VERSION "HNNBNNNYNNNNNNNNNNNNNNNNNNNNNNNNNNNNNNNNNN/4/%%%/4/'%**4NNN///"

NS_ :

BS_:

BU_: Airbag Allrad_Haldex BAP_Tester DCC_Gen3 EBKV_MQBW ESC_MQBW Gateway_Max Lenkhilfe_REPS

BO_ 958 Motor_14: 8 Gateway_Max
 SG_ Motor_14_CRC : 0|8@1+ (1,0) [0|255] ""  ESC_MQBW
 SG_ Motor_14_BZ : 8|4@1+ (1,0) [0|15] ""  ESC_MQBW
 SG_ MO_StartStopp_Status : 12|2@1+ (1.0,0.0) [0.0|3] ""  ESC_MQBW,Lenkhilfe_REPS
 SG_ MO_StartStopp_Wiederstart : 14|1@1+ (1.0,0.0) [0.0|1] ""  EBKV_MQBW,ESC_MQBW,Lenkhilfe_REPS
 SG_ MO_StartStopp_Motorstopp : 15|1@1+ (1.0,0.0) [0.0|1] ""  ESC_MQBW,Lenkhilfe_REPS
 SG_ MO_Freig_Reku : 16|2@1+ (1.0,0.0) [0.0|3] ""  Vector__XXX
 SG_ MO_Kl_75 : 18|1@1+ (1.0,0.0) [0.0|1] ""  EBKV_MQBW,ESC_MQBW,Lenkhilfe_REPS
 SG_ MO_Kl_50 : 19|1@1+ (1.0,0.0) [0.0|1] ""  EBKV_MQBW,ESC_MQBW
 SG_ MO_Gangposition : 20|4@1+ (1.0,0.0) [0.0|15] ""  Airbag,Allrad_Haldex,EBKV_MQBW
 SG_ MO_StartStopp_Fahrerwunsch : 24|2@1+ (1.0,0.0) [0.0|3] ""  ESC_MQBW,Lenkhilfe_REPS
 SG_ MO_HYB_Fahrbereitschaft : 26|1@1+ (1.0,0.0) [0.0|1] ""  EBKV_MQBW,ESC_MQBW,Lenkhilfe_REPS
 SG_ MO_Ext_E_Fahrt_aktiv : 27|1@1+ (1.0,0.0) [0.0|1] ""  Vector__XXX
 SG_ MO_Fahrer_bremst : 28|1@1+ (1.0,0.0) [0.0|1] ""  Airbag,Allrad_Haldex,ESC_MQBW
 SG_ MO_QBit_Fahrer_bremst : 29|1@1+ (1.0,0.0) [0.0|1] ""  Airbag,Allrad_Haldex,ESC_MQBW
 SG_ MO_BLS : 30|1@1+ (1.0,0.0) [0.0|1] ""  Airbag,ESC_MQBW,Lenkhilfe_REPS
 SG_ MO_Konsistenz_Bremsped : 31|1@1+ (1.0,0.0) [0.0|1] ""  Vector__XXX
 SG_ MO_Timeout_ESP : 32|1@1+ (1.0,0.0) [0.0|1] ""  ESC_MQBW
 SG_ MO_Klima_Eingr : 33|2@1+ (1.0,0.0) [0.0|3] ""  Vector__XXX
 SG_ MO_Aussp_Anlass : 35|1@1+ (1.0,0.0) [0.0|1] ""  Vector__XXX
 SG_ MO_Freig_Anlass : 36|1@1+ (1.0,0.0) [0.0|1] ""  Lenkhilfe_REPS
 SG_ MO_Kuppl_schalter : 37|1@1+ (1.0,0.0) [0.0|1] ""  Allrad_Haldex,ESC_MQBW
 SG_ MO_Interlock : 38|1@1+ (1.0,0.0) [0.0|1] ""  Vector__XXX
 SG_ MO_Motor_laeuft : 39|1@1+ (1.0,0.0) [0.0|1] ""  ESC_MQBW
 SG_ MO_Kickdown : 40|1@1+ (1.0,0.0) [0.0|1] ""  ESC_MQBW,Lenkhilfe_REPS
 SG_ MO_QBit_KL_75 : 41|1@1+ (1.0,0.0) [0.0|1] ""  EBKV_MQBW,ESC_MQBW,Lenkhilfe_REPS
 SG_ MO_EKlKomLeiRed : 42|2@1+ (1.0,0.0) [0.0|3] ""  Vector__XXX
 SG_ MO_Handshake_STH : 44|1@1+ (1.0,0.0) [0.0|1] ""  Vector__XXX
 SG_ MO_BKV_Unterdruckwarnung : 45|1@1+ (1.0,0.0) [0.0|1] ""  Vector__XXX
 SG_ MO_Freigabe_Segeln : 46|1@1+ (1.0,0.0) [0.0|1] ""  Vector__XXX
 SG_ MO_PTC_Status : 47|3@1+ (1.0,0.0) [0.0|7] ""  Vector__XXX
 SG_ MO_QBit_Gangposition : 50|1@1+ (1.0,0.0) [0.0|1] ""  Airbag
 SG_ MO_Signalquelle_Gangposition : 51|1@1+ (1.0,0.0) [0.0|1] ""  Vector__XXX
 SG_ MO_Remotestart_Betrieb : 52|1@1+ (1.0,0.0) [0.0|1] ""  Vector__XXX
 SG_ MO_Remotestart_moeglich : 53|1@1+ (1.0,0.0) [0.0|1] ""  Vector__XXX
 SG_ MO_FMAus_aktiv : 55|1@1+ (1.0,0.0) [0.0|1] ""  ESC_MQBW
 SG_ MO_FMAus_Startvariante : 56|2@1+ (1.0,0.0) [0.0|3] ""  Vector__XXX
 SG_ MO_BMS_NV_Anf_stuetzen : 58|1@1+ (1.0,0.0) [0.0|1] ""  Vector__XXX
 SG_ MO_Zylinderabschaltung : 59|2@1+ (1.0,0.0) [0.0|3] ""  ESC_MQBW
 SG_ MO_HYB_VM_aktiv : 61|1@1+ (1.0,0.0) [0.0|1] ""  Vector__XXX
 SG_ MO_StartVorauss_erfuellt : 62|2@1+ (1.0,0.0) [0.0|3] ""  Vector__XXX

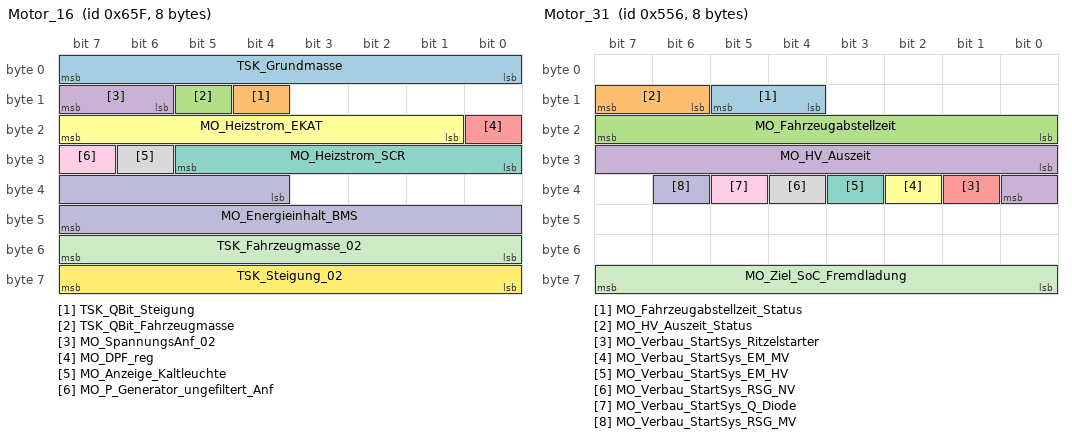
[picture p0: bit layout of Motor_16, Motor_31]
BO_ 1631 Motor_16: 8 Gateway_Max
 SG_ TSK_Grundmasse : 0|8@1+ (32,0) [0|8128] "Unit_KiloGram"  Vector__XXX
 SG_ TSK_QBit_Steigung : 12|1@1+ (1.0,0.0) [0.0|1] ""  Vector__XXX
 SG_ TSK_QBit_Fahrzeugmasse : 13|1@1+ (1.0,0.0) [0.0|1] ""  ESC_MQBW
 SG_ MO_SpannungsAnf_02 : 14|2@1+ (1.0,0.0) [0.0|3] ""  Vector__XXX
 SG_ MO_DPF_reg : 16|1@1+ (1.0,0.0) [0.0|1] ""  Vector__XXX
 SG_ MO_Heizstrom_EKAT : 17|7@1+ (1,0) [0|126] "Unit_Amper"  Vector__XXX
 SG_ MO_Heizstrom_SCR : 24|6@1+ (1,0) [0|62] "Unit_Amper"  Vector__XXX
 SG_ MO_Anzeige_Kaltleuchte : 30|1@1+ (1.0,0.0) [0.0|1] ""  Vector__XXX
 SG_ MO_P_Generator_ungefiltert_Anf : 31|1@1+ (1.0,0.0) [0.0|1] ""  Vector__XXX
 SG_ MO_Energieinhalt_BMS : 36|12@1+ (25,0) [0|102325] "Unit_WattHour"  Vector__XXX
 SG_ TSK_Fahrzeugmasse_02 : 48|8@1+ (32,0) [0|8128] "Unit_KiloGram"  ESC_MQBW
 SG_ TSK_Steigung_02 : 56|8@1+ (0.8,-101.6) [-100.8|101.6] "Unit_PerCent"  Vector__XXX

BO_ 1648 Motor_18: 8 Gateway_Max
 SG_ MO_max_Ladedruck : 0|6@1+ (0.1,0) [0.0|6.3] "Unit_Bar"  Vector__XXX
 SG_ MO_ANC_Kennfeld_Anf : 6|2@1+ (1.0,0.0) [0.0|3] ""  Vector__XXX
 SG_ MO_Bremslicht_Reku : 8|1@1+ (1.0,0.0) [0.0|1] ""  ESC_MQBW
 SG_ MO_StartStopp_PopUp : 9|2@1+ (1.0,0.0) [0.0|3] ""  Vector__XXX
 SG_ MO1_Sperr_Info_WFS : 11|1@1+ (1.0,0.0) [0.0|1] ""  Vector__XXX
 SG_ MO1_Freigabe_Info_WFS : 12|1@1+ (1.0,0.0) [0.0|1] ""  Vector__XXX
 SG_ MO_EPCL : 13|3@1+ (1.0,0.0) [0.0|7] ""  Vector__XXX
 SG_ MO_Zylabsch_Texte_02 : 16|4@1+ (1.0,0.0) [0.0|15] ""  Vector__XXX
 SG_ MO_Fahrzeugtyp : 20|3@1+ (1.0,0.0) [0.0|7] ""  EBKV_MQBW,ESC_MQBW
 SG_ MO_NMAX_Schaltanzeige : 23|9@1+ (25,0) [0|12775] "Unit_MinutInver"  Vector__XXX
 SG_ MO_Abstellzeit : 32|8@1+ (8,0) [0|2024] "Unit_Minut"  Vector__XXX
 SG_ MO_Abstellzeit_Status : 40|2@1+ (1.0,0.0) [0.0|3] ""  Vector__XXX
 SG_ MO1_Freigabe_Verfallsinfo_WFS : 42|1@1+ (1.0,0.0) [0.0|1] ""  Vector__XXX
 SG_ MO_Hybrid_StartStopp_LED : 43|2@1+ (1.0,0.0) [0.0|3] ""  Vector__XXX
 SG_ MO_Fehler_Zylabsch : 45|2@1+ (1.0,0.0) [0.0|3] ""  Vector__XXX
 SG_ MO_Anzahl_Abgesch_Zyl : 47|3@1+ (1.0,0.0) [0.0|7] ""  ESC_MQBW
 SG_ MO_Zylabsch_Texte : 50|2@1+ (1.0,0.0) [0.0|3] ""  Vector__XXX
 SG_ MO_Ethanol_BS_Texte : 52|3@1+ (1.0,0.0) [0.0|7] ""  Vector__XXX
 SG_ MO_Drehzahl_Warnung : 55|1@1+ (1.0,0.0) [0.0|1] ""  Vector__XXX
 SG_ MO_obere_Drehzahlgrenze : 56|8@1+ (50,0) [50|12750] "Unit_MinutInver"  Vector__XXX

BO_ 1366 Motor_31: 8 Gateway_Max
 SG_ MO_Fahrzeugabstellzeit_Status : 12|2@1+ (1.0,0.0) [0.0|3] ""  EBKV_MQBW
 SG_ MO_HV_Auszeit_Status : 14|2@1+ (1.0,0.0) [0.0|3] ""  Vector__XXX
 SG_ MO_Fahrzeugabstellzeit : 16|8@1+ (8,0) [0|2024] "Unit_Minut"  EBKV_MQBW
 SG_ MO_HV_Auszeit : 24|9@1+ (4,0) [0|2036] "Unit_Minut"  Vector__XXX
 SG_ MO_Verbau_StartSys_Ritzelstarter : 33|1@1+ (1.0,0.0) [0.0|1] ""  Vector__XXX
 SG_ MO_Verbau_StartSys_EM_MV : 34|1@1+ (1.0,0.0) [0.0|1] ""  Vector__XXX
 SG_ MO_Verbau_StartSys_EM_HV : 35|1@1+ (1.0,0.0) [0.0|1] ""  Vector__XXX
 SG_ MO_Verbau_StartSys_RSG_NV : 36|1@1+ (1.0,0.0) [0.0|1] ""  Vector__XXX
 SG_ MO_Verbau_StartSys_Q_Diode : 37|1@1+ (1.0,0.0) [0.0|1] ""  Vector__XXX
 SG_ MO_Verbau_StartSys_RSG_MV : 38|1@1+ (1.0,0.0) [0.0|1] ""  Vector__XXX
 SG_ MO_Ziel_SoC_Fremdladung : 56|8@1+ (0.4,0) [0.0|100.0] "Unit_PerCent"  Vector__XXX

BO_ 269 Motor_50: 48 Gateway_Max
 SG_ Motor_50_CRC : 0|8@1+ (1,0) [0|255] ""  ESC_MQBW
 SG_ Motor_50_BZ : 8|4@1+ (1,0) [0|15] ""  ESC_MQBW
 SG_ MO_Mom_Soll_Roh : 12|10@1+ (1,-509) [-509|509] ""  Allrad_Haldex,DCC_Gen3,ESC_MQBW,Lenkhilfe_REPS
 SG_ MO_Mom_Ist_Summe : 22|10@1+ (1,-509) [-509|509] ""  Allrad_Haldex,ESC_MQBW,Lenkhilfe_REPS
 SG_ MO_Mom_Traegheit_Summe : 32|10@1+ (1,-509) [-509|509] ""  ESC_MQBW,Lenkhilfe_REPS
 SG_ MO_Mom_Soll_gefiltert : 42|10@1+ (1,-509) [-509|509] ""  Allrad_Haldex
 SG_ MO_Mom_Schub : 52|9@1+ (1,-509) [-509|0] ""  Allrad_Haldex,ESC_MQBW,Lenkhilfe_REPS
 SG_ MO_Status_Normalbetrieb_01 : 61|1@1+ (1.0,0.0) [0.0|1] ""  Allrad_Haldex
 SG_ MO_erste_Ungenauschwelle : 62|1@1+ (1.0,0.0) [0.0|1] ""  Vector__XXX
 SG_ MO_QBit_Motormomente : 63|1@1+ (1.0,0.0) [0.0|1] ""  ESC_MQBW,Lenkhilfe_REPS
 SG_ MO_Mom_neg_verfuegbar : 76|9@1+ (1,-509) [-509|0] ""  Vector__XXX
 SG_ MO_Mom_Begr_Fahr : 85|9@1+ (1,0) [0|509] ""  Vector__XXX
 SG_ MO_Mom_Begr_Schalt : 94|10@1+ (1,-509) [-509|509] ""  Vector__XXX
 SG_ MO_Momentenintegral_02 : 104|7@1+ (1,0) [0|100] "Unit_PerCent"  Vector__XXX
 SG_ MO_QBit_Drehzahl_01 : 111|1@1+ (1.0,0.0) [0.0|1] ""  Airbag,ESC_MQBW,Lenkhilfe_REPS
 SG_ MO_Drehzahl_01 : 112|16@1+ (0.25,0) [0.00|16383.00] "Unit_MinutInver"  Airbag,Allrad_Haldex,ESC_MQBW,Lenkhilfe_REPS
 SG_ MO_HYB_EMode_Info : 142|2@1+ (1.0,0.0) [0.0|3] ""  Vector__XXX
 SG_ MO_HYB_max_ind_VM_Mom_02 : 144|8@1+ (1.186,0) [0.000|300.058] "Unit_NewtoMeter"  Vector__XXX
 SG_ MO_HYB_Zielzustand : 152|3@1+ (1.0,0.0) [0.0|7] ""  ESC_MQBW
 SG_ MO_HYB_Modus_Ankopplung_VM : 155|1@1+ (1.0,0.0) [0.0|1] ""  Vector__XXX
 SG_ MO_HYB_Freigabe_VM_Eingr : 156|2@1+ (1.0,0.0) [0.0|3] ""  Vector__XXX
 SG_ MO_HYB_Sollstatus_K0 : 158|1@1+ (1.0,0.0) [0.0|1] ""  Vector__XXX
 SG_ MO_HYB_Komfortstufe : 159|1@1+ (1.0,0.0) [0.0|1] ""  Vector__XXX
 SG_ MO_HYB_VM_bereit : 160|1@1+ (1.0,0.0) [0.0|1] ""  Vector__XXX
 SG_ MO_HYB_Stoppmodus : 161|1@1+ (1.0,0.0) [0.0|1] ""  Vector__XXX
 SG_ MO_HYB_LowSpeedModus : 162|1@1+ (1.0,0.0) [0.0|1] ""  Vector__XXX
 SG_ MO_HYB_Schaltverhinderung : 163|1@1+ (1.0,0.0) [0.0|1] ""  Vector__XXX
 SG_ MO_HYB_E_Faktor : 164|4@1+ (1.0,0.0) [0.0|15] ""  Vector__XXX
 SG_ MO_HYB_VM_Mom_oE_02 : 168|8@1+ (1.186,-50) [-50.000|250.058] "Unit_NewtoMeter"  Vector__XXX
 SG_ MO_Drehzahl_VM : 176|16@1+ (0.25,0) [0.00|16383.00] "Unit_MinutInver"  EBKV_MQBW,ESC_MQBW
 SG_ MO_EM1_SollDrehzahl : 192|15@1+ (1,-10000) [-10000|22766] "Unit_MinutInver"  Vector__XXX
 SG_ MO_Luftpfad_Verzugszeit_praed : 207|5@1+ (10,0) [10|310] "Unit_MilliSecon"  Vector__XXX
 SG_ MO_EM2_SollDrehzahl : 212|15@1+ (1,-10000) [-10000|22766] "Unit_MinutInver"  Vector__XXX
 SG_ MO_TNW_Min_Strom_Lim : 227|13@1+ (0.5,-2047) [-2047.0|2047.5] "Unit_Amper"  Vector__XXX
 SG_ MO_TNW_Max_Strom_Lim : 240|13@1+ (0.5,-2047) [-2047.0|2047.5] "Unit_Amper"  Vector__XXX

BO_ 267 Motor_51_Auth: 48 Gateway_Max
 SG_ Motor_51_CRC : 0|8@1+ (1,0) [0|255] ""  ESC_MQBW
 SG_ Motor_51_BZ : 8|4@1+ (1,0) [0|15] ""  ESC_MQBW
 SG_ MO_Fahrpedalrohwert_01 : 12|8@1+ (0.4,0) [0.0|101.6] "Unit_PerCent"  Airbag,Allrad_Haldex,DCC_Gen3,EBKV_MQBW,ESC_MQBW,Lenkhilfe_REPS
 SG_ MO_QBit_Fahrpedalwerte_01 : 20|1@1+ (1.0,0.0) [0.0|1] ""  Airbag,Allrad_Haldex,EBKV_MQBW,ESC_MQBW,Lenkhilfe_REPS
 SG_ MO_Fahrpedalgradient : 21|8@1+ (25,0) [0|6350] "Unit_PerCentPerSecon"  ESC_MQBW
 SG_ MO_Sig_Fahrpedalgradient : 29|1@1+ (1.0,0.0) [0.0|1] ""  ESC_MQBW
 SG_ MO_rel_Saugrohrdruck : 30|6@1+ (18,0) [0|1116] "Unit_MilliBar"  Vector__XXX
 SG_ MO_rel_Saugrohrdruck_gem_err : 36|1@1+ (1.0,0.0) [0.0|1] ""  Vector__XXX
 SG_ MO_Moment_im_Leerlauf : 37|1@1+ (1.0,0.0) [0.0|1] ""  ESC_MQBW
 SG_ MO_Schubabschaltung : 38|1@1+ (1.0,0.0) [0.0|1] ""  Vector__XXX
 SG_ MO_StartStopp_StoppVorbereitung : 39|1@1+ (1.0,0.0) [0.0|1] ""  Vector__XXX
 SG_ MO_Solldrehz_Leerlauf : 40|8@1+ (10,0) [0|2540] "Unit_MinutInver"  ESC_MQBW
 SG_ MO_Entkopplung_Sollschlupf : 48|7@1+ (20,0) [0|2480] "Unit_MinutInver"  Vector__XXX
 SG_ MO_temporaere_Fahrerabwesenheit : 55|1@1+ (1.0,0.0) [0.0|1] ""  ESC_MQBW
 SG_ TSK_a_Soll_gradientenbegrenzt : 57|7@1+ (0.1,-7.2) [-7.2|5.4] "Unit_MeterPerSeconSquar"  Vector__XXX
 SG_ TSK_Radbremsmom : 76|12@1+ (8,0) [0|32760] "Unit_NewtoMeter"  ESC_MQBW
 SG_ TSK_Status : 88|3@1+ (1.0,0.0) [0.0|7] ""  Airbag,ESC_MQBW
 SG_ TSK_v_Begrenzung_aktiv : 91|1@1+ (1.0,0.0) [0.0|1] ""  Vector__XXX
 SG_ TSK_Standby_Anf_ESP : 92|1@1+ (1.0,0.0) [0.0|1] ""  ESC_MQBW
 SG_ TSK_Freig_Verzoeg_Anf : 94|1@1+ (1.0,0.0) [0.0|1] ""  ESC_MQBW
 SG_ TSK_Limiter_ausgewaehlt : 95|1@1+ (1.0,0.0) [0.0|1] ""  Vector__XXX
 SG_ TSK_Hauptschalter_GRA_ACC : 106|2@1+ (1.0,0.0) [0.0|3] ""  Vector__XXX
 SG_ TSK_SRBM_Anf_ASIL : 108|3@1+ (1.0,0.0) [0.0|7] ""  ESC_MQBW
 SG_ TSK_ax_Getriebe_02 : 112|9@1+ (0.024,-2.016) [-2.016|10.224] "Unit_MeterPerSeconSquar"  Vector__XXX
 SG_ TSK_Zwangszusch_ESP : 121|1@1+ (1.0,0.0) [0.0|1] ""  ESC_MQBW
 SG_ TSK_zul_Regelabw : 122|6@1+ (0.024,0) [0.000|1.512] "Unit_MeterPerSeconSquar"  Vector__XXX
 SG_ TSK_Radsollmoment : 128|16@1+ (0.5,-16383) [-16383.0|16383.5] "Unit_NewtoMeter"  Vector__XXX
 SG_ TSK_Kategorie_Verzoegerungsfkt : 144|2@1+ (1.0,0.0) [0.0|3] ""  ESC_MQBW
 SG_ TSK_Notstopp_Anf : 233|2@1+ (1.0,0.0) [0.0|3] ""  ESC_MQBW
 SG_ MO_Status_MinDrzEingriff : 235|3@1+ (1.0,0.0) [0.0|7] ""  Vector__XXX
 SG_ MO_Status_MaxDrzEingriff : 238|3@1+ (1.0,0.0) [0.0|7] ""  Vector__XXX
 SG_ MO_Status_MinDrzEingriff_sek : 241|3@1+ (1.0,0.0) [0.0|7] ""  Vector__XXX
 SG_ MO_Status_MaxDrzEingriff_sek : 244|3@1+ (1.0,0.0) [0.0|7] ""  Vector__XXX
 SG_ TSK_SRBM_max_Gradient : 248|7@1+ (50,0) [0|6250] "Unit_NewtoMeterPerSecon"  ESC_MQBW
 SG_ SOK_Motor_51_Signatur : 352|32@1+ (1,0) [0|4294967295] ""  Vector__XXX

BO_ 512 Motor_53: 32 Gateway_Max
 SG_ TSK_Wunschgeschw : 12|10@1+ (0.32,0) [0.00|326.72] "Unit_KiloMeterPerHour"  Vector__XXX
 SG_ TSK_praediktiver_Hinweis : 22|3@1+ (1.0,0.0) [0.0|7] ""  Vector__XXX
 SG_ TSK_naechstes_Event : 25|6@1+ (1.0,0.0) [0.0|63] ""  Vector__XXX
 SG_ TSK_Fahrzeugstatus_praed_Fkt : 31|3@1+ (1.0,0.0) [0.0|7] ""  Vector__XXX
 SG_ TSK_praediktiver_Automode : 34|1@1+ (1.0,0.0) [0.0|1] ""  Vector__XXX
 SG_ CE_StStrtDlyEmiSysPrep : 35|2@1+ (1.0,0.0) [0.0|3] ""  Vector__XXX
 SG_ CE_StLdRdcEmiSysPrep : 37|3@1+ (1.0,0.0) [0.0|7] ""  Vector__XXX
 SG_ TSK_Texte : 40|5@1+ (1.0,0.0) [0.0|31] ""  Vector__XXX
 SG_ TSK_Akustik : 45|3@1+ (1.0,0.0) [0.0|7] ""  Vector__XXX
 SG_ TSK_Texte_Primaeranz : 48|5@1+ (1.0,0.0) [0.0|31] ""  Vector__XXX
 SG_ TSK_Limiter_Fahrerinfo : 53|2@1+ (1.0,0.0) [0.0|3] ""  Vector__XXX
 SG_ TSK_Limiter_Anzeige : 55|1@1+ (1.0,0.0) [0.0|1] ""  Vector__XXX
 SG_ TSK_Fahrzeugstatus_GRA : 56|1@1+ (1.0,0.0) [0.0|1] ""  Vector__XXX
 SG_ TSK_Fahrzeugstatus_Limiter : 57|1@1+ (1.0,0.0) [0.0|1] ""  Vector__XXX
 SG_ MO_Motorlaufwarnung : 58|1@1+ (1.0,0.0) [0.0|1] ""  Vector__XXX
 SG_ TSK_naechstes_Event_Einheit : 60|1@1+ (1.0,0.0) [0.0|1] ""  Vector__XXX
 SG_ TSK_Status_Anzeige : 61|3@1+ (1.0,0.0) [0.0|7] ""  Vector__XXX
 SG_ MO_Sperrung_FahrPr_BZS : 64|8@1+ (1.0,0.0) [0.0|255] ""  Vector__XXX
 SG_ MO_Rampenzeit_Generator_Anf : 72|4@1+ (1.0,0.0) [0.0|15] ""  Vector__XXX
 SG_ MO_Prio_MAX_Wunschdrehzahl : 76|1@1+ (1.0,0.0) [0.0|1] ""  Vector__XXX
 SG_ MO_Prio_MIN_Wunschdrehzahl : 77|1@1+ (1.0,0.0) [0.0|1] ""  Vector__XXX
 SG_ MO_Luftpfad_aktiv : 78|1@1+ (1.0,0.0) [0.0|1] ""  Vector__XXX
 SG_ MO_v_Begrenz_Aktivierbar : 79|1@1+ (1.0,0.0) [0.0|1] ""  Vector__XXX
 SG_ MO_Drehzahlbeeinflussung : 80|8@1+ (0.39,0) [0.00|99.45] "Unit_PerCent"  Vector__XXX
 SG_ MO_MIN_Wunschdrehzahl : 88|8@1+ (25,0) [0|6350] "Unit_MinutInver"  Vector__XXX
 SG_ MO_MAX_Wunschdrehzahl : 96|9@1+ (25,0) [0|12750] "Unit_MinutInver"  Vector__XXX
 SG_ MO_Charisma_FahrPr : 105|4@1+ (1.0,0.0) [0.0|15] ""  Vector__XXX
 SG_ MO_Charisma_Status : 109|2@1+ (1.0,0.0) [0.0|3] ""  Vector__XXX
 SG_ MO_StSt_Charisma_FahrPr : 111|4@1+ (1.0,0.0) [0.0|15] ""  Vector__XXX
 SG_ MO_StSt_Charisma_Status : 115|2@1+ (1.0,0.0) [0.0|3] ""  Vector__XXX
 SG_ MO_BZS_Charisma_FahrPr : 117|4@1+ (1.0,0.0) [0.0|15] ""  Vector__XXX
 SG_ MO_BZS_Charisma_Status : 121|2@1+ (1.0,0.0) [0.0|3] ""  Vector__XXX
 SG_ MO_NGS_Position : 123|1@1+ (1.0,0.0) [0.0|1] ""  ESC_MQBW
 SG_ MO_NGS_Status : 124|2@1+ (1.0,0.0) [0.0|3] ""  ESC_MQBW
 SG_ MO_v_Begrenzung_Niveau : 126|2@1+ (1.0,0.0) [0.0|3] ""  Vector__XXX
 SG_ MO_Anzeige_Rekuperation : 128|8@1+ (0.5,-0.5) [0.0|100.0] "Unit_PerCent"  Vector__XXX
 SG_ PEA_Fortschrittsanzeige : 136|7@1+ (1,0) [0|100] "Unit_PerCent"  Vector__XXX
 SG_ MO_Anzeige_Fahrbereitschaft : 143|1@1+ (1.0,0.0) [0.0|1] ""  Vector__XXX
 SG_ MO_Boost_verfuegbar : 144|8@1+ (0.4,-0.4) [0.0|100.4] "Unit_PerCent"  Vector__XXX
 SG_ MO_Overboost : 152|1@1+ (1.0,0.0) [0.0|1] ""  Vector__XXX
 SG_ MO_Boost_aktiv : 153|1@1+ (1.0,0.0) [0.0|1] ""  Vector__XXX
 SG_ MO_Anzeige_Betriebsmodus : 154|4@1+ (1.0,0.0) [0.0|15] ""  Vector__XXX
 SG_ PEA_Hinweis : 158|2@1+ (1.0,0.0) [0.0|3] ""  Vector__XXX
 SG_ PEA_Ereignisanzeige : 160|5@1+ (1.0,0.0) [0.0|31] ""  Vector__XXX
 SG_ PEA_Ereignisanzeige_temporaer : 165|1@1+ (1.0,0.0) [0.0|1] ""  Vector__XXX
 SG_ PEA_Abschalttexte : 166|2@1+ (1.0,0.0) [0.0|3] ""  Vector__XXX
 SG_ PEA_Zielgeschw_Einheit : 168|1@1+ (1.0,0.0) [0.0|1] ""  Vector__XXX
 SG_ PEA_Zielgeschw : 169|5@1+ (1.0,0.0) [0.0|31] ""  Vector__XXX
 SG_ MO_Antriebsstrang_Warnung_HS : 174|2@1+ (1.0,0.0) [0.0|3] ""  Vector__XXX
 SG_ MO_Anzeige_Verbrauch_oE : 176|16@1+ (0.005,0) [0.000|327.675] "Unit_None"  Vector__XXX
 SG_ MO_Text_Aktivierung_Antrieb : 192|4@1+ (1.0,0.0) [0.0|15] ""  Vector__XXX
 SG_ ISA_Tempolimit_Regelung : 196|6@1+ (1.0,0.0) [0.0|63] ""  Vector__XXX
 SG_ PEA_Fahrerinfo : 202|4@1+ (1.0,0.0) [0.0|15] ""  Vector__XXX
 SG_ CE_CtrPrpPrep : 206|3@1+ (1.0,0.0) [0.0|7] ""  Vector__XXX
 SG_ CE_PrctPrpPrep : 209|7@1+ (1,0) [0|100] "Unit_PerCent"  Vector__XXX
 SG_ MO_Kuehlmitttel_Sensor_AGB2 : 216|1@1+ (1.0,0.0) [0.0|1] ""  Vector__XXX
 SG_ CE_FlgEmiColdLmp : 217|1@1+ (1.0,0.0) [0.0|1] ""  Vector__XXX
 SG_ CE_FlgEmiColdTxt : 218|1@1+ (1.0,0.0) [0.0|1] ""  Vector__XXX
 SG_ CE_FlgHybModAdvi : 219|1@1+ (1.0,0.0) [0.0|1] ""  Vector__XXX
 SG_ CE_FlgPTLimPrfTxt : 220|1@1+ (1.0,0.0) [0.0|1] ""  Vector__XXX
 SG_ TSK_praed_Wunschgeschw : 246|10@1+ (0.32,0) [0.00|326.72] "Unit_KiloMeterPerHour"  Vector__XXX

BO_ 332 Motor_54: 32 Gateway_Max
 SG_ Motor_54_CRC : 0|8@1+ (1,0) [0|255] ""  ESC_MQBW
 SG_ Motor_54_BZ : 8|4@1+ (1,0) [0|15] ""  ESC_MQBW
 SG_ MO_Anforderung_HMS : 12|3@1+ (1.0,0.0) [0.0|7] ""  ESC_MQBW
 SG_ FoD_DTC_TSK_GRA : 15|1@1+ (1.0,0.0) [0.0|1] ""  Vector__XXX
 SG_ TSK_vMax_aktuell : 16|8@1+ (1,0) [0|253] "Unit_KiloMeterPerHour"  Vector__XXX
 SG_ ISA_Status : 24|3@1+ (1.0,0.0) [0.0|7] ""  Vector__XXX
 SG_ ISA_Regelung_aktiv : 27|1@1+ (1.0,0.0) [0.0|1] ""  Vector__XXX
 SG_ ISA_Tempolimitwarnung : 28|1@1+ (1.0,0.0) [0.0|1] ""  Vector__XXX
 SG_ MO_Red_El_Fahrleistung : 29|3@1+ (1.0,0.0) [0.0|7] ""  Vector__XXX
 SG_ TSK_Status_EA : 32|3@1+ (1.0,0.0) [0.0|7] ""  Vector__XXX
 SG_ FoD_DTC_TSK_ACC : 35|1@1+ (1.0,0.0) [0.0|1] ""  Vector__XXX
 SG_ TSK_ACC_FoD_Status : 36|2@1+ (1.0,0.0) [0.0|3] ""  Vector__XXX
 SG_ TSK_GRA_FoD_Status : 38|2@1+ (1.0,0.0) [0.0|3] ""  Vector__XXX
 SG_ TSK_vMax_Fahrerassistenz : 40|9@1+ (1,0) [0|510] ""  Vector__XXX
 SG_ TSK_Einheit_vMax_Fahrerassistenz : 49|1@1+ (1.0,0.0) [0.0|1] ""  Vector__XXX
 SG_ TSK_Status_PLA : 50|3@1+ (1.0,0.0) [0.0|7] ""  Vector__XXX
 SG_ TSK_aktives_System : 53|3@1+ (1.0,0.0) [0.0|7] ""  Vector__XXX
 SG_ TSK_erhoehter_Fahrwiderstand : 56|1@1+ (1.0,0.0) [0.0|1] ""  Vector__XXX
 SG_ TSK_Anf_Antriebsmoment : 57|1@1+ (1.0,0.0) [0.0|1] ""  Vector__XXX
 SG_ TSK_Status_ARA : 58|3@1+ (1.0,0.0) [0.0|7] ""  Vector__XXX
 SG_ TSK_Status_IPA : 61|3@1+ (1.0,0.0) [0.0|7] ""  Vector__XXX
 SG_ TSK_aktives_System_02 : 64|4@1+ (1.0,0.0) [0.0|15] ""  ESC_MQBW
 SG_ TSK_Status_RHP : 68|3@1+ (1.0,0.0) [0.0|7] ""  ESC_MQBW
 SG_ MO_Kuppl_betaetigt : 72|1@1+ (1.0,0.0) [0.0|1] ""  Vector__XXX
 SG_ MO_QBit_Kuppl_betaetigt : 73|1@1+ (1.0,0.0) [0.0|1] ""  Vector__XXX
 SG_ MO_Klima_Regelmodus : 74|2@1+ (1.0,0.0) [0.0|3] ""  Vector__XXX
 SG_ MO_Fahrbereitschaft : 76|2@1+ (1.0,0.0) [0.0|3] ""  EBKV_MQBW,ESC_MQBW,Lenkhilfe_REPS
 SG_ MO_Freilauf_Info : 78|2@1+ (1.0,0.0) [0.0|3] ""  Vector__XXX
 SG_ CE_FlgLnchCtlPreCnd : 80|1@1+ (1.0,0.0) [0.0|1] ""  Vector__XXX
 SG_ MO_Krit_Heckobjekt : 81|3@1+ (1.0,0.0) [0.0|7] ""  Vector__XXX
 SG_ MO_NGS_Gangpos : 84|3@1+ (1.0,0.0) [0.0|7] ""  Vector__XXX
 SG_ MO_Freilauf_Status : 87|3@1+ (1.0,0.0) [0.0|7] ""  Vector__XXX
 SG_ MO_EBoost_verf_praed : 90|2@1+ (1.0,0.0) [0.0|3] ""  Vector__XXX
 SG_ MO_Heckspoiler_Anf : 92|1@1+ (1.0,0.0) [0.0|1] ""  Vector__XXX
 SG_ MO_eLaunch_verf : 93|2@1+ (1.0,0.0) [0.0|3] ""  Vector__XXX
 SG_ MO_Positionierung_aktiv : 95|1@1+ (1.0,0.0) [0.0|1] ""  Vector__XXX
 SG_ MO_Veto_Launchcontrol : 96|1@1+ (1.0,0.0) [0.0|1] ""  Vector__XXX
 SG_ MO_Startwunsch : 100|1@1+ (1.0,0.0) [0.0|1] ""  Vector__XXX
 SG_ MO_LaunchControl : 101|1@1+ (1.0,0.0) [0.0|1] ""  Vector__XXX
 SG_ MO_UBE_Hybrid_Reserve : 102|10@1+ (5,0) [0|5110] "Unit_WattHour"  Vector__XXX
 SG_ OBDProtocol_req : 112|8@1+ (1.0,0.0) [0.0|255] ""  EBKV_MQBW,ESC_MQBW
 SG_ OBD_Calc_Load_Val : 128|8@1+ (0.39215686274509803,0) [0E-17|99.99999999999999765] "Unit_PerCent"  EBKV_MQBW,ESC_MQBW
 SG_ OBD_Eng_Cool_Temp : 136|8@1+ (1,-40) [-40|215] "Unit_DegreCelsi"  EBKV_MQBW,ESC_MQBW
 SG_ OBD_Abs_Throttle_Pos : 144|8@1+ (0.39215686274509803,0) [0E-17|99.99999999999999765] "Unit_PerCent"  Airbag,EBKV_MQBW,ESC_MQBW
 SG_ OBD_Abs_Load_Val : 152|16@1+ (0.39215686274509803,0) [0E-17|25699.99999999999939605] "Unit_PerCent"  EBKV_MQBW,ESC_MQBW
 SG_ OBD_Abs_Pedal_Pos : 168|8@1+ (0.39215686274509803,0) [0E-17|99.99999999999999765] "Unit_PerCent"  EBKV_MQBW,ESC_MQBW
 SG_ MO_Servicemodus : 176|4@1+ (1.0,0.0) [0.0|15] ""  Vector__XXX
 SG_ OBD_ClearMem_Inhibit : 183|1@1+ (1.0,0.0) [0.0|1] ""  EBKV_MQBW,ESC_MQBW
 SG_ OBD_Sperrung_Kaltstart_Denom : 184|1@1+ (1.0,0.0) [0.0|1] ""  EBKV_MQBW,ESC_MQBW
 SG_ MO_QBit_Aussen_Temp : 185|1@1+ (1.0,0.0) [0.0|1] ""  Vector__XXX
 SG_ OBD_Sperrung_IUMPR : 186|1@1+ (1.0,0.0) [0.0|1] ""  EBKV_MQBW,ESC_MQBW
 SG_ OBD_Kaltstart_Denominator : 187|1@1+ (1.0,0.0) [0.0|1] ""  EBKV_MQBW,ESC_MQBW
 SG_ OBD_Minimum_Trip : 188|1@1+ (1.0,0.0) [0.0|1] ""  EBKV_MQBW,ESC_MQBW
 SG_ OBD_Driving_Cycle : 189|1@1+ (1.0,0.0) [0.0|1] ""  EBKV_MQBW,ESC_MQBW
 SG_ OBD_Warm_Up_Cycle : 190|1@1+ (1.0,0.0) [0.0|1] ""  DCC_Gen3,EBKV_MQBW,ESC_MQBW,Lenkhilfe_REPS
 SG_ OBD_Normed_Trip : 191|1@1+ (1.0,0.0) [0.0|1] ""  EBKV_MQBW,ESC_MQBW
 SG_ MO_EMG_Min_Leistung : 192|11@1+ (100,-102200) [-102200|102300] "Unit_Watt"  Vector__XXX
 SG_ MO_EMG_Max_Leistung : 203|11@1+ (100,-102200) [-102200|102300] "Unit_Watt"  Vector__XXX
 SG_ MO_MVEM_MinLeistung_MVVerbrauch : 214|10@1+ (50,-10500) [-10500|40500] "Unit_Watt"  Vector__XXX
 SG_ MO_MVEM_MaxLeistung_MVVerbrauch : 224|10@1+ (50,-10500) [-10500|40500] "Unit_Watt"  Vector__XXX
 SG_ MO_UBE_Reserve : 238|10@1+ (5,0) [0|5110] "Unit_WattHour"  Vector__XXX
 SG_ OBD_Aussen_Temp_gef : 248|8@1+ (1,-40) [-40|213] "Unit_DegreCelsi"  ESC_MQBW

BO_ 553 Motor_54_SOK_Signatur: 4 Gateway_Max
 SG_ SOK_Motor_54_Signatur : 0|32@1+ (1,0) [0|4294967295] ""  EBKV_MQBW,ESC_MQBW

BO_ 246 Motor_55_Auth: 48 Gateway_Max
 SG_ Motor_55_CRC : 0|8@1+ (1,0) [0|255] ""  ESC_MQBW
 SG_ Motor_55_BZ : 8|4@1+ (1,0) [0|15] ""  ESC_MQBW
 SG_ TS_Faktor_Radmomente : 12|2@1+ (1.0,0.0) [0.0|3] ""  ESC_MQBW
 SG_ TS_Status_MomRad_Ist : 14|2@1+ (1.0,0.0) [0.0|3] ""  ESC_MQBW
 SG_ TS_MomRad_verfuegb_maxReku_Summe : 16|12@1+ (3,-12279) [-12279|0] ""  ESC_MQBW
 SG_ TS_MomRad_Ist : 28|13@1+ (3,-12279) [-12279|12279] "Unit_None"  ESC_MQBW
 SG_ TS_MomRad_Soll_Summe : 41|13@1+ (3,-12279) [-12279|12279] "Unit_None"  ESC_MQBW
 SG_ TS_MomRad_Wunsch : 54|13@1+ (3,-12279) [-12279|12279] "Unit_None"  ESC_MQBW
 SG_ TS_MomRad_Wunsch_sek : 67|13@1+ (3,-12279) [-12279|12279] "Unit_None"  ESC_MQBW
 SG_ TS_MomRad_verfuegb_max : 80|12@1+ (3,0) [0|12279] "Unit_None"  ESC_MQBW
 SG_ TS_MomRad_verfuegb_max_sek : 92|12@1+ (3,0) [0|12279] "Unit_None"  Vector__XXX
 SG_ TS_MomRad_verfuegb_maxReku : 104|12@1+ (3,-12279) [-12279|0] "Unit_None"  ESC_MQBW
 SG_ TS_MomRad_verfuegb_maxReku_sek : 116|12@1+ (3,-12279) [-12279|0] "Unit_None"  Vector__XXX
 SG_ TS_MomRad_Ist_sek : 128|13@1+ (3,-12279) [-12279|12279] "Unit_None"  Vector__XXX
 SG_ TS_Allrad_Anteil_sek : 141|9@1+ (0.2,0) [0.0|100.0] "Unit_PerCent"  Vector__XXX
 SG_ FDR_Allrad_Anteil_max_sek : 150|9@1+ (0.2,0) [0.0|100.0] "Unit_PerCent"  Vector__XXX
 SG_ FDR_Allrad_Anteil_min_sek : 159|9@1+ (0.2,0) [0.0|100.0] "Unit_PerCent"  Vector__XXX
 SG_ FDR_MomRad_Eingriff : 168|13@1+ (3,-12279) [-12279|12279] "Unit_NewtoMeter"  Vector__XXX
 SG_ FDR_Status_Eingriff : 181|1@1+ (1.0,0.0) [0.0|1] ""  Vector__XXX
 SG_ FDR_MomRad_Eingriff_sek : 182|13@1+ (3,-12279) [-12279|12279] "Unit_NewtoMeter"  Vector__XXX
 SG_ FDR_Status_Eingriff_sek : 195|1@1+ (1.0,0.0) [0.0|1] ""  Vector__XXX
 SG_ MO_Mom_Begr_Fahr_Pred : 196|9@1+ (1,0) [0|509] ""  Vector__XXX
 SG_ FDR_Zwangszusch_ESP : 205|1@1+ (1.0,0.0) [0.0|1] ""  Vector__XXX
 SG_ MO_EMG_Sollmodus : 206|4@1+ (1.0,0.0) [0.0|15] ""  Vector__XXX
 SG_ TS_Status_DrzReg : 210|2@1+ (1.0,0.0) [0.0|3] ""  Vector__XXX
 SG_ TS_Status_DrzReg_sek : 212|2@1+ (1.0,0.0) [0.0|3] ""  Vector__XXX
 SG_ MO_EMG_SollDrehzahl : 257|15@1+ (1,-10000) [-10000|22766] "Unit_MinutInver"  Vector__XXX
 SG_ MO_EMG_Max_Momentengradient : 272|7@1+ (1,0) [0|124] "Unit_NewtoMeterPerSecon"  Vector__XXX
 SG_ MO_EMG_Generator_Leistung : 279|11@1+ (20,-20440) [-20440|20460] "Unit_Watt"  Vector__XXX
 SG_ MO_EMG_Max_Strom_Lim : 290|11@1+ (1,-1023) [-1023|1022] "Unit_Amper"  Vector__XXX
 SG_ MO_EMG_Min_Strom_Lim : 301|11@1+ (1,-1023) [-1023|1022] "Unit_Amper"  Vector__XXX
 SG_ MO_EMG_Max_Spannung_Lim : 312|8@1+ (0.25,0) [0.00|63.25] "Unit_Volt"  Vector__XXX
 SG_ MO_EMG_Min_Spannung_Lim : 320|8@1+ (0.25,0) [0.00|63.25] "Unit_Volt"  Vector__XXX
 SG_ MO_EMG_SollMoment_02 : 328|16@1+ (0.01,-327.68) [-327.68|327.65] "Unit_NewtoMeter"  Vector__XXX
 SG_ MO_EMG_Sollspannung : 344|8@1+ (0.25,0) [0.00|63.25] "Unit_Volt"  Vector__XXX
 SG_ SOK_Motor_55_Signatur : 352|32@1+ (1,0) [0|4294967295] ""  Vector__XXX

CM_ BO_ 1648 "Kombischnittstelle";

CM_ SG_ 958 MO_Aussp_Anlass "Das Signal zeigt an, ob die Wiederholstartsperre aktiv ist. D. h. eine Ansteuerung des Anlassers wird auch bei erfüllten Startvoraussetzungen (HS: Interlock betätigt bzw. AT: P/N eingelegt und Bremse betätigt) nicht erfolgen.";
CM_ SG_ 958 MO_BKV_Unterdruckwarnung "Über die Unterdruckwarnung signalisiert das MSG dem ESP, dass kein ausreichender Unterdruck für den BKV zur Verfügung gestellt werden kann.";
CM_ SG_ 958 MO_BLS "Ungefiltertes Rohsignal des Bremslichtschalters, nur wenn HW-Eingang bestückt und ausgewertet wird. Bei Motoren ohne genutzten HW-Eingang wird kein Ersatzwert (bspw. SW-Signal über CAN) ausgegeben!
Bei AUDI muss das Signal wg. Bremslichtfunktion immer be";
CM_ SG_ 958 MO_BMS_NV_Anf_stuetzen "Garantierte Unterstützung des Zusatzspeichers ist erforderlich. Zusatzspeicher muss an das Versorgungsnezt angebunden werden. ";
CM_ SG_ 958 MO_EKlKomLeiRed "Anforderung an die Klimasteuerung, die Leistungsaufnahme des E-Kompressors bei schlechtem SOC und in bestimmten Fahrsituationen zu begrenzen. (Das bereits bestehende Signal 'Klimakompressor aus' als stets umzusetzende Anforderung bleibt unverändert besteh";
CM_ SG_ 958 MO_Ext_E_Fahrt_aktiv "Funktionsrückmeldung zum erw. E-Fahr-Betrieb über Lampe/LED im E-Mode-Taster";
CM_ SG_ 958 MO_Fahrer_bremst "Redundante Bremsinformation vom Motor.

MLB:
AUDI D4: Zykluszeit: 10ms (siehe Zykluszeit schnell/Cycletime Fast)
Im AUDI B8 wird in diesem Bit der Wert der ESP-CAN-Information 'ESP_Fahrer_bremst' ausgegeben.

Achtung:
Reduktion der Zykluszeit Motor";
CM_ SG_ 958 MO_FMAus_aktiv "Das Signal gibt Rückmeldung ob Freilauf Motor aus aktiv ist. Beleibt auch 0km/h (unterhalb der StartStopp Schwelle) weiterhin aktiv.";
CM_ SG_ 958 MO_FMAus_Startvariante "Startvariante beim Motorstart aus der Freilauf-Motor-AUS Phase";
CM_ SG_ 958 MO_Freig_Anlass "Bit wird gesetzt, wenn der Motor beim Automatikstart gestartet werden darf (Motorstillstand, Emissionsmaßnahmen sind erfüllt).";
CM_ SG_ 958 MO_Freig_Reku "Empfehlung des Motor-SG's zur Spannungsabsenkung/-anhebung für den Rekuperationsbetrieb";
CM_ SG_ 958 MO_Freigabe_Segeln "Freigabebit des Segelbetriebs im Getriebe. Bedingt durch bestimmte Diagnosen und Adaptionen des MSGs, die nur im Schub möglich sind, darf nicht jede Schubphase für einen Segelbetrieb genutzt werden. Eine Freigabe bleibt auch außerhalb einer Schubphase bes";
CM_ SG_ 958 MO_Gangposition "MLB:
Stellung des Wählhebels in der Schaltgasse des Handschaltgetriebes.
MLBevo: 
Ausweitung der Bedienung auch auf Automatikgetriebe;
Routing des Signals GE_Fahrstufe: 
1. Position_R (dez. 6) auf MO_Gangposition: Gang_R (dez. 13) wegen Entfall Signa";
CM_ SG_ 958 MO_Handshake_STH "Es gilt: Signalspec MO_Handshake v1.0

Handshake zwischen MSG und STH. Wenn das MSG die EKP aufgrund einer STH-Anforderung ansteuert und kein Fehlereintrag bzgl. EKP/KPE/NDR vorliegt, wird das Bit gesetzt.";
CM_ SG_ 958 MO_HYB_Fahrbereitschaft "Signal steuert u.a. in der Lenkhilfe zusammen mit weiteren Informationen den Modewechsel in den 'Drivemode'
Grüne Anzeige im Kombiinstrument zur Signalisierung der Bereitschaft des Hybridsystems.";
CM_ SG_ 958 MO_HYB_VM_aktiv "0 = VMotor wird nicht aktiv gehalten (nVM < n_min und keine LL-Regelung aktiv)
1 = VMotor aktiv (ab der ersten Einspritzung; gilt auch für Schubbetrieb, wenn VMotor spätestens durch LLRegelung befeuert würde)
Verwendet zur Bestimmung des Ist-Zustandes";
CM_ SG_ 958 MO_Interlock "Das Motorsteuergerät gibt die Information aus, ab wann der Kupplungsschalter durch das Motorsteuergerät als getreten gesehen wird.
Bei Systemen für Start Stopp muss das Interlocksignal für einen Start durch das MSG generiert werden, sobald der Schalthebe";
CM_ SG_ 958 MO_Kickdown "Es gilt: Signalspec MO_Kickdown v1.0";
CM_ SG_ 958 MO_Kl_50 "Klemme 50: Startausführung durch Ritzelstarter

MLB: nicht von allen Motoren gesendet
MQB/MLBevo: gesendet von allen Motoren";
CM_ SG_ 958 MO_Kl_75 "Klemme X
";
CM_ SG_ 958 MO_Klima_Eingr "Eingriffe des Motor bei der Klima";
CM_ SG_ 958 MO_Konsistenz_Bremsped "MLB:

AUDI D4: Zykluszeit: 10ms (siehe Zykluszeit schnell/Cycletime Fast)
Siehe 'Funktionsspezifikation Bremslichtinfo B8'

Achtung:
Reduktion der Zykluszeit Motor_03 auf 10ms geplant.
Projektabhängig soll künftig mit 10ms gesendet werden.
Empfäng";
CM_ SG_ 958 MO_Kuppl_schalter "MLB:
Das Motorsteuergerät gibt die Information aus, ab wann der Kupplungsschalter durch das Motorsteuergerät als getreten gesehen wird
0x0: Schalter sagt betätigt (Ausgekuppelt)
0x1: Schalter sagt nicht betätigt (Eingekuppelt)

MQB:
Nur Handschalter";
CM_ SG_ 958 MO_Motor_laeuft "Das Motorsteuergerät gibt die Information aus, ab wann der Motor verbrennungsbedingt autark läuft und durch zuschaltbare Nebenaggregate mechanisch belastbar ist (z.B. durch Generator, Klimakompressor, etc.).

Die 'Motor läuft' Information wird ausgegebe";
CM_ SG_ 958 MO_PTC_Status "Status-Rückmeldung vom MSG zum aktuellen PTC-Status (stufiges PTC, Relais am MSG). Bei Ansteuerung eines stufigen PTC durch ein anderes SG beschreibt das Signal die vom MSG freigegebene PTC-Stufe.";
CM_ SG_ 958 MO_QBit_Fahrer_bremst "MLB:
AUDI D4: Zykluszeit: 10ms (siehe Zykluszeit schnell/Cycletime Fast)

Achtung:
Reduktion der Zykluszeit Motor_03 auf 10ms geplant.
Projektabhängig soll künftig mit 10ms gesendet werden.
Empfänger die in weiteren Konzern-Projekten eingesetzt werd";
CM_ SG_ 958 MO_QBit_Gangposition "Qualitätsbit zum Signal MO_Gangposition";
CM_ SG_ 958 MO_QBit_KL_75 "Q - Bit für das KL 75 Signal zur Vermeidung der fehlerhaften Erkennung von Motorstarts. 
Wird auf 1 gesetzt, solange das Motorsteuergerät KL15 = AUS erkannt hat.";
CM_ SG_ 958 MO_Remotestart_Betrieb "Das MSG ist für den Remotestart-Betrieb bereit. Nach Empfang der Motorstartanforderung für RSt-Betrieb durch BCM wird der Fahrzeugmotor gestartet und solange der Motor läuft, bleibt dieses Bit aktiv. Dieses Signal ist nur zur Verwendung durch das BCM zur ";
CM_ SG_ 958 MO_Remotestart_moeglich "Wenn Bit gesetzt, würde das MSG bei entsprechender Anforderung durch das BCM den Remotestartbetrieb einleiten, d.h. das MSG ist remotestartfähig und es liegen aktuell keine relevanten Fehler oder andere Abbruchgründe vor.";
CM_ SG_ 958 MO_Signalquelle_Gangposition "Signalquelle des Signals MO_Gangposition
0: Signalquelle Gangpositionssensor
1: Signalquelle Modellwert (v/n)";
CM_ SG_ 958 MO_StartStopp_Fahrerwunsch "Fahreraktivität Start/Stop";
CM_ SG_ 958 MO_StartStopp_Motorstopp "Motor-Stopp durch Start/Stopp-Koordinator
HYBRID:
Wenn MO_Hybridfahrzeug = 1 gilt:
Verbrennungsmotor durch Hybrid-Koordinator im MSG ausgeschaltet. 
Die definierten Start/Stopp-Signale beziehen sich nur auf den Verbrennungsmotor!";
CM_ SG_ 958 MO_StartStopp_Status "Aktivitätsstatus Start/Stopp-Koordinator
HYBRID:
Wenn MO_Hybridfahrzeug = 1 gilt:
Signal bezieht sich nur auf den Verbrennungsmotor, nicht auf den Hybridantrieb
";
CM_ SG_ 958 MO_StartStopp_Wiederstart "Motorwiederstart durch Start/Stopp-Koordinator
HYBRID:
Wenn MO_Hybridfahrzeug =1 gilt:
Warnung vor Spannungseinbruch beim Zustart des Verbrennungsmotors. 
-nicht relevant, da derzeit kein Start über 12V-Starter geplant-
Dieses Signal wird nur vom Hyb";
CM_ SG_ 958 MO_StartVorauss_erfuellt "Dient der Fallunterscheidung bei ZAT-Betätigung im Zustand 'KL15 ein' (bei nicht gesetztem Signal folgt KL15 aus, bei gesetztem Signal folgt setzen KL50-Anf.)

0: Signal nicht bedient 
1: Voraussetzungen zur Antriebsstrangaktivierung / Startvoraussetzu";
CM_ SG_ 958 MO_Timeout_ESP "500 ms Timeout auf Bremsen-Botschaft ist >= 1 mal aufgelaufen, Löschen des Bits nach Neustart (KL15).

MLB:
AUDI D4: Zykluszeit: 10ms (siehe Zykluszeit schnell/Cycletime Fast)

Achtung:
Reduktion der Zykluszeit Motor_03 auf 10ms geplant.
Projektabh";
CM_ SG_ 958 MO_Zylinderabschaltung "Status Zylinderabschaltung Motor";
CM_ SG_ 958 Motor_14_CRC "Ab MQB und MLBevo:
'Berechnung siehe Lastenheft 'End-to-End Kommunikationsabsicherung'

Endwerte siehe Begleitdokument 'S-PDU Kennungsfolgen'";

CM_ SG_ 1631 MO_Anzeige_Kaltleuchte "Fahrleistungseinschänkungen aus dem Motor-Abgasmanagement zur Anzeige als Lampe ohne Hinweistext im Kombiinstrument";
CM_ SG_ 1631 MO_DPF_reg "Regeneration Diesel-Partikel-Filter";
CM_ SG_ 1631 MO_Energieinhalt_BMS "Restenergieinhalt der Traktionsbatterie, beeinflusst durch Fahrstrategie und weiteren Faktoren der Antriebssteuerung.";
CM_ SG_ 1631 MO_Heizstrom_EKAT "Aktuelle Gesamtstromaufnahme des E-Katalysators";
CM_ SG_ 1631 MO_Heizstrom_SCR "Aktuelle Gesamtstromaufnahme der Tank-, Fördermodul- und Leitungsheizung des SCR-Systems";
CM_ SG_ 1631 MO_P_Generator_ungefiltert_Anf "Bei Empfang der Anforderung soll der Sender BEM_P_Generator ungefiltert befüllen.";
CM_ SG_ 1631 MO_SpannungsAnf_02 "Forderung des Motor-SG's zur Spannungsanhebung";
CM_ SG_ 1631 TSK_Fahrzeugmasse_02 "Neue Definition ab D4
Fahrzeugmasse in kg. Das Signal dient der Anpassung der Sollbeschleunigung vom ACC


";
CM_ SG_ 1631 TSK_Grundmasse "Fahrzeuggrundmasse in kg. Das Signal dient der Anpassung der Sollbeschleunigung vom ACC

Hinweis: Ehemaliger Fehlerwert 0x7F wird senderseitig nicht unterstützt. Diesen Wert aus Kompatibilitätsgründen nicht neu belegen!";
CM_ SG_ 1631 TSK_Steigung_02 "Steigung in % Berg. Das Signal dient der Anpassung der Sollbeschleunigung vom ACC

Positive Werte > bergauf; 
Negative Werte < bergab

Fehler: Die Steigung aufgrund eines Fehlers (mit KD-Fehlereintrag) nicht mehr berechnet werden";

CM_ SG_ 1648 MO1_Freigabe_Info_WFS "WFS-Freigabeinformation";
CM_ SG_ 1648 MO1_Freigabe_Verfallsinfo_WFS "WFS-Freigabeverfallsinformation";
CM_ SG_ 1648 MO1_Sperr_Info_WFS "WFS-Sperrinformation";
CM_ SG_ 1648 MO_Abstellzeit "Abstelldauer nach letztem KL15 aus

Hinweis: 
Ehemaliger Fehlerwert 0xFF wird senderseitig nicht unterstützt. 
Diesen Wert aus Kompatibilitätsgründen nicht neu belegen!";
CM_ SG_ 1648 MO_Abstellzeit_Status "Statusinformation zur Abstellzeit
0: Die dem Status zugeordnete Variable konnte noch nicht berechnet werden. 
1: Die dem Status zugehörige Variable wurde korrekt berechnet. 
2: Der Wert der zugehörigen Variablen ist nur ein Minimalwert. 
3: Der Wert d";
CM_ SG_ 1648 MO_ANC_Kennfeld_Anf "Anforderung ANC Kennfeldumschaltung";
CM_ SG_ 1648 MO_Anzahl_Abgesch_Zyl "Gibt die Anzahl der abgeschalteten Zylinder an. In Übergangszuständen wird der Zielbetriebszustand angezeigt.";
CM_ SG_ 1648 MO_Bremslicht_Reku "Bremslicht (ggf. bei Rekuperation durch E-Motor) wird angesteuert";
CM_ SG_ 1648 MO_Drehzahl_Warnung "Warnhinweis zum Kombi im Fall einer fehlerbehafteten Drehzahlbegrenzung";
CM_ SG_ 1648 MO_EPCL "Die Anforderung der EPC-Lampe vom MSG ans Kombi soll durch das Bus-Signal MO_EPCL gemäß folgender Logik erfolgen:
MO_EPCL = 0 dez -> EPC Lampe aus, kein Text
MO_EPCL = 1 dez -> gelbe EPC-Symbolik, Text „Antrieb: Störung! Bitte Service aufsuchen“
MO_EPC";
CM_ SG_ 1648 MO_Ethanol_BS_Texte "Ethanol Brennstoff-Texte im Kombi

0 = kein Text
1 = E85 Warm_Up
2 = FlexFuel Warnung 3.Stufe (Too cold for ethanol)
3 = Warmfahrempfehlung MQB / FlexFuel Warnung 1.Stufe (Refuel with gasoline)
4 = FlexFuel Warnung 2. Stufe (Refuel with gasoline)
5";
CM_ SG_ 1648 MO_Fahrzeugtyp "Unterscheidet die Fahrzeugtypen bzgl. der Antriebsart";
CM_ SG_ 1648 MO_Fehler_Zylabsch "Fehlerstatus der Funktion Zylinderabschaltung ";
CM_ SG_ 1648 MO_Hybrid_StartStopp_LED "Ansteuerung der Funktions-LED der Hybrid Taste bzw. Start/Stop Deaktivierungstaste.
Der Start/Stopp-Master (derzeit im MSG) (oder ein künftiger Hybrid-Master) soll die Ansteuerung senden.";
CM_ SG_ 1648 MO_max_Ladedruck "maximal möglicher Ladedruck (zur Anpassung des Anzeigebereichs bei absoluter Ladedruckanzeige)";
CM_ SG_ 1648 MO_NMAX_Schaltanzeige "Maximaldrehzahl für Schaltanzeige";
CM_ SG_ 1648 MO_obere_Drehzahlgrenze "obere Drehzahlgrenze des Motors";
CM_ SG_ 1648 MO_StartStopp_PopUp "Das Signal zeigt an, ob der StSt-Status mittels Deaktivierungstaster geändert wurde. Ein Wechsel auf die Werte 01 oder 10 löst im Kombi ein entsprechendes PopUp aus. Bei einem Statuswechsel durch andere Signalquellen (z.B. Charisma, fehlerbedingte Abschal";
CM_ SG_ 1648 MO_Zylabsch_Texte "Zylinderabschaltung mode in Kombi, fuer Zylinderabschaltung";
CM_ SG_ 1648 MO_Zylabsch_Texte_02 "ZAS-Anzeige für den Fahrer im Kombi
0: kein ZAS (generell keinerlei ZAS-Anzeigen)  (Init für nicht ZAS-Motor)
1: ZAS im Vollmotorbetrieb  (Init für ZAS-Motor)
2: ZAS im Abschaltbetrieb: 1 Zyl aktiv
3: ZAS im Abschaltbetrieb: 2 Zyl aktiv
4: ZAS im Abs";

CM_ SG_ 1366 MO_Fahrzeugabstellzeit "Zeit seit letzter Fahrbereitschaft.";
CM_ SG_ 1366 MO_Fahrzeugabstellzeit_Status "Status Fahrzeugabstellzeit";
CM_ SG_ 1366 MO_HV_Auszeit "Zeit seit letzter Hochvoltaktivität.";
CM_ SG_ 1366 MO_HV_Auszeit_Status "Status HV-Auszeit.";
CM_ SG_ 1366 MO_Verbau_StartSys_EM_HV "Signal zeigt an, welche Komponenten des Startsystemes verbaut sind.
Verbau E-Maschine HV";
CM_ SG_ 1366 MO_Verbau_StartSys_EM_MV "Signal zeigt an, welche Komponenten des Startsystemes verbaut sind.
Verbau E-Maschine MV z.B. 48V";
CM_ SG_ 1366 MO_Verbau_StartSys_Q_Diode "Signal zeigt an, welche Komponenten des Startsystemes verbaut sind.
Verbau Q_Diode";
CM_ SG_ 1366 MO_Verbau_StartSys_Ritzelstarter "Signal zeigt an, welche Komponenten des Startsystemes verbaut sind.
Verbau Ritzel Starter";
CM_ SG_ 1366 MO_Verbau_StartSys_RSG_MV "Signal zeigt an, welche Komponenten des Startsystemes verbaut sind.
Verbau Riemen Starter Generator MV z.B. 48V";
CM_ SG_ 1366 MO_Verbau_StartSys_RSG_NV "Signal zeigt an, welche Komponenten des Startsystemes verbaut sind.
Verbau Riemen Starter Generator NV z.B. 12V";
CM_ SG_ 1366 MO_Ziel_SoC_Fremdladung "Auf diesen SoC soll MHEV-Speicher geladen werden, wenn ein Ladegerät erkannt ist.";

CM_ SG_ 269 MO_Drehzahl_01 "Im Fehlerfall wird die Motordrehzahl über die Nockenwellendrehzahl als Ersatzgrösse ausgegeben

Bei Parallelhybrid: Getriebeeingangsdrehzahl (=E-Maschinen Drehzahl)

Hinweis: 
Ehemaliger Fehlerwert 0xFFFF wird senderseitig nicht unterstützt. 
Diesen";
CM_ SG_ 269 MO_Drehzahl_VM "Motordrehzahl des Verbrennungsmotors

für OBD freeze frame

Hinweis: 
Ehemaliger Fehlerwert 0xFFFF wird senderseitig nicht unterstützt. 
Diesen Wert aus Kompatibilitätsgründen nicht neu belegen!";
CM_ SG_ 269 MO_EM1_SollDrehzahl "E-Maschinen Soll-Drehzahl";
CM_ SG_ 269 MO_EM2_SollDrehzahl "E-Maschinen Soll-Drehzahl";
CM_ SG_ 269 MO_erste_Ungenauschwelle "Zusätzliche Ungenauigkeit (zur Grundungenauigkeit). Motormomente ungenau >8% (kleinste Ungenauschwelle)
";
CM_ SG_ 269 MO_HYB_E_Faktor "Signed Nibble, verwendet vom GSG zur Interpolation zwischen VMKennfeld und dem Rekuperations-Grenzkennfeld (negative Werte des E-Faktors) bzw. dem Boost-Grenzkennfeld (positive Werte des E-Faktors).
0000 = VM-Kennfeld (keine Interpolation)
0001..0111 = ";
CM_ SG_ 269 MO_HYB_EMode_Info "Hybrid-Mode der Motorsteuerung zur Beeinflussung der Schaltkennfelder im Getriebe. Nicht-Hybridfahrzeuge senden den Initwert.";
CM_ SG_ 269 MO_HYB_Freigabe_VM_Eingr "Hybridsteuerung zeigt an, ob der VM beim Ankoppeln nicht anbrennen darf bzw. anbrennen soll.
";
CM_ SG_ 269 MO_HYB_Komfortstufe "Hybridsteuerung zeigt Startkomfort(-wunsch) an";
CM_ SG_ 269 MO_HYB_LowSpeedModus "MSG legt fest:
0 = klassisches Ausrollen/Anfahren mit N_mot >= N_Leerlauf_VM
1 = elektr. Ausrollen/Anfahren mit geschl. Triebstrang mit N_mot < N_Leerlauf_VM";
CM_ SG_ 269 MO_HYB_max_ind_VM_Mom_02 "inneres maximal mögliches VM-Moment bei einer Drehzahl (z.B. Rauchbegrenzung oder Fehlerfall).";
CM_ SG_ 269 MO_HYB_Modus_Ankopplung_VM "Hybridsteuerung zeigt an, auf welche Weise  der VM angekoppelt werden soll.";
CM_ SG_ 269 MO_HYB_Schaltverhinderung "Schaltungen werden an den DZ-Grenzen (Nullgas-Schaltdrehzahl und Kickdown-Schaltdrehzahl) ausgeführt.";
CM_ SG_ 269 MO_HYB_Sollstatus_K0 "Zusatzinformation zu MO_HYB_Zielzustand, die den  Zielzustand  mit geschlossener bzw. nicht offener K0  weiter differenziert in  die Unterstatus  'schlupfend 'und 'geschlossen'. Zur  Darstellung von asynchronen Ankopplungsvorgängen wie asynchronem Schmier";
CM_ SG_ 269 MO_HYB_Stoppmodus "Hybridsteuerung zeigt an, auf welche Weise gestoppt werden soll.";
CM_ SG_ 269 MO_HYB_VM_bereit "Hybridspezifisches Signal zum VKM-Status beim Ankoppeln,
VKM ist brennbereit";
CM_ SG_ 269 MO_HYB_VM_Mom_oE_02 "Verbrenner-Fahrmoment abzüglich Verbrenner-Verlustmoment. Vorzeichenbehaftet. Für Benutzung in Getriebe-Schaltstrategie";
CM_ SG_ 269 MO_HYB_Zielzustand "Ziel-Betriebszustand des Hybriden, definiert die gewünschten Status der K0 und der Getriebekupplungen.
Der Zielzustand  gibt dabei u.a. an, ob der VM angekoppelt ist oder nicht. Er beinhaltet nicht die Information, ob der VM tatsächlich einspritzt und an";
CM_ SG_ 269 MO_Luftpfad_Verzugszeit_praed "Aktuelle Verzugszeit des luftführenden Systems im Motor, welche dem Getriebe bereitgestellt wird, um reduzierende Momenteneingriffe einer Hochschaltung entsprechend dieser Zeit zu prädizieren.";
CM_ SG_ 269 MO_Mom_Begr_Fahr "Einheitenloser Wert! Faktor in MO_Faktor_Momente (CAN V6.x) bzw. MO_Faktor_Momente_02 (CAN V7.x und höher) in Motor_Code_01 beachten!

Bei aktueller Drehzahl quasistationär (nach ca. 3…5 s) max. mögliches Getriebeeingangsmoment (Summe aus Verbrennungsmo";
CM_ SG_ 269 MO_Mom_Begr_Schalt "Einheitenloser Wert! Faktor in MO_Faktor_Momente (CAN V6.x) bzw. MO_Faktor_Momente_02 (CAN V7.x/8.x) in Motor_Code_01 beachten!

Bei aktueller Drehzahl kurzfristig (ca. 100..200 ms) für momentenerhöhende Getriebeeingriffe max. zur Verfügung stehendes Ge";
CM_ SG_ 269 MO_Mom_Ist_Summe "Einheitenloser Wert! Faktor in MO_Faktor_Momente_02 in Motor_Code_01 beachten!

Ist-Moment als Summe aus Verbrennungsmotor und E-Motor (bei Hybrid-Konzepten) incl. allen Eingriffen und Korrekturen

In Fahrzeugen mit einer Antriebsachse bzw. mit mechan";
CM_ SG_ 269 MO_Mom_neg_verfuegbar "Einheitenloser Wert! Faktor in MO_Faktor_Momente (CAN V6.x) bzw. MO_Faktor_Momente_02 (CAN V7.x) in Motor_Code_01 beachten!

Bei aktueller Drehzahl im nächsten Task (bei CAN-Übertragung z.B. 10ms) tatsächlich verfügbares negatives Moment (Summe aus Verl";
CM_ SG_ 269 MO_Mom_Schub "Einheitenloser Wert! Faktor in MO_Faktor_Momente_02 in Motor_Code_01 beachten!

Moment das sich einstellt, wenn der Fahrer 0% Fahrpedal gibt; bei konventionellen Projekten = alle Verluste (mechanische Reibung und sonstige Verluste) des Verbrennungsmotor";
CM_ SG_ 269 MO_Mom_Soll_gefiltert "Einheitenloser Wert! Faktor in MO_Faktor_Momente_02 in Motor_Code_01 beachten!

MO_Mom_Soll_Roh nach Fahrverhaltensfilter, begrenzt nach oben mit MO_Mom_Begr_dyn, Einrechnung der plausibilisierten Bremsen-Eingriffe; ohne Getriebe-Schalt-Eingriffe, ohne ";
CM_ SG_ 269 MO_Mom_Soll_Roh "Einheitenloser Wert! Faktor in MO_Faktor_Momente_02 in Motor_Code_01 beachten!

Momentenanforderung aus Fahrpedal bzw. von ACC/GRA bzw. aus dem Leerlaufregler (quasistatischer Anteil) bzw. aus Rekuperationsanforderung; keine Begrenzungen, keine Filterun";
CM_ SG_ 269 MO_Mom_Traegheit_Summe "Einheitenloser Wert! Faktor in MO_Faktor_Momente (CAN V6.x) bzw. MO_Faktor_Momente_02 (CAN V7.x) in Motor_Code_01 beachten!

Moment, das zur Beschleunigung der trägen Massen aufgewendet wird bzw. frei wird; Summen aus Anteilen für Verbrennungsmotor und ";
CM_ SG_ 269 MO_Momentenintegral_02 "100  %  entspricht volle Verfügbarkeit aktuell vorhanden. 0 % entspricht Integral bis Limit gefüllt, erhöhender Eingriff kann aktuell nicht berücksichtigt werden oder aufgrund eines Fehlers nicht verfügbar
";
CM_ SG_ 269 MO_QBit_Drehzahl_01 "AUDI D4: Zykluszeit: 10ms (siehe Zykluszeit schnell/Cycletime Fast)

Achtung:
Reduktion der Zykluszeit Motor_03 auf 10ms geplant.
Projektabhängig soll künftig mit 10ms gesendet werden.
Empfänger die in weiteren Konzern-Projekten eingesetzt werden müs";
CM_ SG_ 269 MO_QBit_Motormomente "AUDI D4: Zykluszeit: 10ms (siehe Zykluszeit schnell/Cycletime Fast)

Ungenaue Momentenangaben, weil die Momente aus Ersatzwerten berechnet wurden (z.B. HFM ausgefallen). Qualifizierungsbit für die Motormomente.

Achtung:
Reduktion der Zykluszeit Moto";
CM_ SG_ 269 MO_Status_Normalbetrieb_01 "Das Motorsteuergerät sendet das Informationsbit, wenn die Initialisierungsphase des Steuergerätes abgeschlossen ist. Zusätzlich muss die Klemme 15 eingeschalten sein und eine applizierbare Mindestdrehzahlschwelle (Kennlinie in Abh. von der Kühlwassertempe";
CM_ SG_ 269 MO_TNW_Max_Strom_Lim "maximal zulässiger HV-Strom, der von dem TNW (Traktionsnetzwandler) im motorischen Betrieb aufgenommen werden darf; Abregelstrom zum Einhalten der HV-Systemgrenzen (Bauteilschutz)";
CM_ SG_ 269 MO_TNW_Min_Strom_Lim "minimal zulässiger HV-Strom, der von dem TNW (Traktionsnetzwandler) im generatorischen Betrieb abgegeben werden darf (betragsmäßig maximal aber i.d.R. negativ, daher ‚Min‘); Abregelstrom zum Einhalten der HV-Systemgrenzen (Bauteilschutz)";
CM_ SG_ 269 Motor_50_BZ "4bit Botschaftszähler, wird mit jeder Sendebotschaft inkrementiert";
CM_ SG_ 269 Motor_50_CRC "Für MLB:
Berechnung siehe Lastenheft 'Kommunikationsabsicherung für FlexRay und CAN'
Ab MQB und MLBevo:
Berechnung siehe Lastenheft 'End-to-End Kommunikationsabsicherung'

Endwerte siehe Begleitdokument 'S-PDU Kennungsfolgen'";

CM_ SG_ 267 MO_Entkopplung_Sollschlupf "MSG fordert von GSG an, das Anfahrelement (Fahr-/Wandlerkupplung) zu entkoppeln; das GSG soll die gesendete Drehzahl als Schlupf einstellen und ggf. die Regler-Parameter umschalten, damit Rucke aus dem Antrieb nicht im Fahrzeug spürbar werden; nutzbar z.B";
CM_ SG_ 267 MO_Fahrpedalgradient "Das Motorsteuergerät besitzt 2 analoge Fahrpedalsignale. Das Signal des ersten Kanals wird alle 4ms abgetastet. Um Bitschwankungen des A/D-Wandler herauszufiltern wird das Signal entjittert. Anschließend wird der Gradient berechnet. Entsprechend der Zyklu";
CM_ SG_ 267 MO_Fahrpedalrohwert_01 "AUDI D4: Zykluszeit: 10ms (siehe Zykluszeit schnell/Cycletime Fast)

Stellung des Fahrpedales (Rohwert, ohne Überlagerung durch GRA-Eingriffe etc.)

Die Funktionen zur Berechung des Fahrpedalrohwerts laufen im 10ms Raster. Der Fahrpedalwert berechnet ";
CM_ SG_ 267 MO_Moment_im_Leerlauf "Fahrerwunschmoment ist minimal: keine Momentenanforderung durch Fahrpedal, ACC oder GRA+; (Das Signal ist unabhängig von Momentenerhöhungen durch Leerlaufregler oder MSR).

AUDI D4: Zykluszeit: 10ms (siehe Zykluszeit schnell/Cycletime Fast)

Achtung:";
CM_ SG_ 267 MO_QBit_Fahrpedalwerte_01 "AUDI D4: Zykluszeit: 10ms (siehe Zykluszeit schnell/Cycletime Fast)

QBit für beide Fahrpedalwerte des Motors (Fahrpedalrohsignal für ESP, EPB, ACC; Fahrpedalwert für Getriebe)

Achtung:
Reduktion der Zykluszeit Motor_03 auf 10ms geplant.
Projektabh";
CM_ SG_ 267 MO_rel_Saugrohrdruck "Der Wert gibt an, um wieviel mbar der Saugrohrdruck unterhalb des Umgebungsdrucks liegt. Überdruck im Saugrohr wird nicht ausgegeben.
0: Saugrohrdruck=Umgebungsdruck";
CM_ SG_ 267 MO_rel_Saugrohrdruck_gem_err "0: mind. eine Modellrechnung wird zur Berechnung des relativen Saugdrucks herangezogen
1: Relativer Saugrohrdruck wird ausschließlich über Messgrößen bestimmt";
CM_ SG_ 267 MO_Schubabschaltung "ESP plausibilisiert Unterdrucksensor nur bei aktiver Schubabschaltung

MLBevo:
Signal wird nur in MLBevo Projekten mit PDKII Getriebe bedient. In allen anderen MLBevo Projekten wird das Signal mit '0' bedient
PDKII berücksichtigt Verzugszeiten, die in";
CM_ SG_ 267 MO_Sig_Fahrpedalgradient "Kennzeichnet das Vorzeichen des Signal 'Fahrpedalgradient'. Die Ausgabe erfolgt nur parallel statisch mit gesendetem Signal: 'Steuerungsbit Fahrpedalgradient' ";
CM_ SG_ 267 MO_Solldrehz_Leerlauf "Leerlaufsolldrehzahl, die im Motor eingestellt ist (Bei Parallelhybrid im E-Fahr-Betrieb Leerlaufsolldrehzahl der E-Maschine). Der Motor paßt aufgrund der Anforderung von anderen Steuergeräten seine Leerlaufsolldrehzahl an, bspw. Kat-Heizen, Anforderung v";
CM_ SG_ 267 MO_StartStopp_StoppVorbereitung "Zeigt allen aktiven Start-/Stoppteilnehmern einen möglichen Motorstopp im Anhaltevorgang an (Empfänger notwendige Vorbereitungen treffen)
Es liegen keine Vetos vor.";
CM_ SG_ 267 MO_Status_MaxDrzEingriff "Aktuell drehzahlführender Anforderer der Maximaldrehzahl (Begrenzungsregelung) des Pulswechselrichters der Primärachse.";
CM_ SG_ 267 MO_Status_MaxDrzEingriff_sek "Aktuell drehzahlführender Anforderer der Maximaldrehzahl (Begrenzungsregelung) des Pulswechselrichters der Sekundärachse.";
CM_ SG_ 267 MO_Status_MinDrzEingriff "Aktuell drehzahlführender Anforderer der Minimaldrehzahl (Begrenzungsregelung) des Pulswechselrichters der Primärachse.";
CM_ SG_ 267 MO_Status_MinDrzEingriff_sek "Aktuell drehzahlführender Anforderer der Minimaldrehzahl (Begrenzungsregelung) des Pulswechselrichters der Sekundärachse.";
CM_ SG_ 267 MO_temporaere_Fahrerabwesenheit "Das Signal dient zur Signalisierung einer temporären Abwesenheit des Fahrers. In dieser Zeit ist es ihm möglich, sich durch gewisse ¿ im Verlassenskonzept definierte ¿ Fahreraktionen im aktuellen Fahrzyklus zurückzumelden.
Das Signal wird gesetzt, sobald";
CM_ SG_ 267 Motor_51_BZ "4bit Botschaftszähler, wird mit jeder Sendebotschaft inkrementiert";
CM_ SG_ 267 Motor_51_CRC "Für MLB:
Berechnung siehe Lastenheft 'Kommunikationsabsicherung für FlexRay und CAN'
Ab MQB und MLBevo:
Berechnung siehe Lastenheft 'End-to-End Kommunikationsabsicherung'

Endwerte siehe Begleitdokument 'S-PDU Kennungsfolgen'";
CM_ SG_ 267 SOK_Motor_51_Signatur "Signatur im Rahmen der durch SOK geschützten Broadcast-Kommunikation

Geschützte Funktion: Bremsfunktion HDC und Airbag-Funktionen 
Geschützte Botschaft: Motor_51";
CM_ SG_ 267 TSK_a_Soll_gradientenbegrenzt "TSK Sollbeschleunigung für Fahrerassistenzsysteme mit aktiver Längsführung (GRA, ACC, IPA...). Der Wert stellt den ruckbegrenzten Sollwert der TSK-Regelung dar und ist Basis der TSK-Antriebs- und Bremsmomentenvorsteuerung.";
CM_ SG_ 267 TSK_ax_Getriebe_02 "Beschleunigungsanforderung des Beschleunigungsreglers (u. a. für ACC, GRA, Speed Limiter). Das Signal wird vom Getriebe benutzt, um die von GRA/ACC geforderte Sollbeschleunigung in dem verbrauchsgünstigsten Gang einzustellen.
MQB: Im MQB wird die Sollbes";
CM_ SG_ 267 TSK_Freig_Verzoeg_Anf "Freigabe der Verzögerungsanforderung der ACC oder ggf. GRA+ Funktion für ECD Regelung im ESP";
CM_ SG_ 267 TSK_Hauptschalter_GRA_ACC "Stellung des GRA/ACC Hauptschalters. Das Signal wird auch bei Fehlerabschaltungen von GRA/ACC weiterhin bedient und ermöglicht für ACC die Steuerung der ACC-Anzeige auch in Fehlerfällen.";
CM_ SG_ 267 TSK_Kategorie_Verzoegerungsfkt "Zeigt der Bremslichtfunktion an, ob die aktuell verzögerungswirksame Teilnehmerfunktion am TSK als Fahrerassistenzsystem oder als Schubrekuperation zu interpretieren ist.";
CM_ SG_ 267 TSK_Limiter_ausgewaehlt "ACC/GRA-Betrieb nur bei nicht ausgewähltem Limiter möglich";
CM_ SG_ 267 TSK_Notstopp_Anf "Anforderung Notstopp des TSK";
CM_ SG_ 267 TSK_Radbremsmom "Bei der Schnittstelle vom TSK zum ESP soll in Folgeprojekten des B8 und insbesondere bei VW-Projekten die Ansteuerung der Bremse nicht über Sollbeschleunigung sondern Bremsmoment erfolgen.  Es handelt sich genauer um das Summenradbremsmoment, welches die ";
CM_ SG_ 267 TSK_Radsollmoment "Sollradmoment vom TSK";
CM_ SG_ 267 TSK_SRBM_Anf_ASIL "ASIL-Level des TSK-Anforderers, der aktuell eine Bremsmomentenanforderung auslöst";
CM_ SG_ 267 TSK_SRBM_max_Gradient "In diesem Signal wird der vom TSK maximal geforderte SummenRadBremsMomentengradient gesendet, der von der Bremse bei der Umsetzung der TSK-Verzögerung nicht überschritten werden darf.";
CM_ SG_ 267 TSK_Standby_Anf_ESP "Mit diesem Bit wird das aktive Bremssystem auf eine anstehende TSK-Verzögerungsanforderung vorbereitet (Überfahren Leerweg, Anlegen Bremsbeläge)";
CM_ SG_ 267 TSK_Status "Betriebszustand des TSK-Reglers";
CM_ SG_ 267 TSK_v_Begrenzung_aktiv "Limiter oder HGB begrenzen die Beschleunigung/das Moment";
CM_ SG_ 267 TSK_zul_Regelabw "Anforderung der zulässigen Regelabweichung vom Triebstrangkoordinator. Zulässiger Betrag der Abweichung zwischen angeforderter 'TSK_Sollbeschleunigung_Getriebe' und umzusetzender Sollbeschleunigung  im Getriebe. Im TSK wird, abhängig vom Arbeitspunkt die ";
CM_ SG_ 267 TSK_Zwangszusch_ESP "Mit diesem Bit wird das ESP/ASR zwangsweise aktiviert. Bei gesetztem Bit ist ein ausgetastetes ESP (oder ASR) wieder aktiviert bzw. wird die Austastung verhindert.";

CM_ SG_ 512 CE_CtrPrpPrep "Anzeigesignal für Countdown des Aufheizfortschritts (VW-Anzeigekonzept)";
CM_ SG_ 512 CE_FlgEmiColdLmp "Ausgabe einer aktiven Momenteneinschränkung während des Kaltstart.";
CM_ SG_ 512 CE_FlgEmiColdTxt "„Volle Antriebsleistung demnächst verfügbar“
VW: mit Aktivierung der Emissionskaltleuchte für 5s sichtbar
AUDI: Anzeige solange max. Leistung < Schwelle (zB. 50%)";
CM_ SG_ 512 CE_FlgHybModAdvi "'Für volle Antriebsleistung Hybrid-Modus wählen'";
CM_ SG_ 512 CE_FlgPTLimPrfTxt "PopUp für Fahrerwarnung bei Derating aufgrund zu hoher Abgastemperatur

„Fahrleistung temporär eingeschränkt“";
CM_ SG_ 512 CE_PrctPrpPrep "Anzeigesignal für Ladebalken des Aufheizfortschritts";
CM_ SG_ 512 CE_StLdRdcEmiSysPrep "Status Lastreduktion zur Konditionierung des Abgassystems";
CM_ SG_ 512 CE_StStrtDlyEmiSysPrep "Startverzögerung aufgrund Emissionssystem";
CM_ SG_ 512 ISA_Tempolimit_Regelung "Anzeige des expliziten Tempolimits zur Regelgrundanzeige";
CM_ SG_ 512 MO_Antriebsstrang_Warnung_HS "Status der Fehlerlampen-Ansteuerung und Textausgabe für Fehlerspeichereinträge aus der Kupplungsschutz-Funktion für Handschaltgetriebe.";
CM_ SG_ 512 MO_Anzeige_Betriebsmodus "Info an das Kombi zur Anzeige verschiedener Betriebsmodi";
CM_ SG_ 512 MO_Anzeige_Fahrbereitschaft "Signalisiert dauerhaft an das Kombi, ob die Fahrbereitschaft vorhanden ist (Drehzahlmesser auf READY)";
CM_ SG_ 512 MO_Anzeige_Rekuperation "Signal steht im Kontext zu MO_Anzeige_Verbrauch und wird für die Anzeige des Reku-Bereiches im grafischen Momentanverbrauch verwendet";
CM_ SG_ 512 MO_Anzeige_Verbrauch_oE "Anzeige Verbrauchssignal fürs Kombi. Im Bezug auf Verbrennerbeteiligung. Das Signal ist einheitenlos. Die zugehörige Einheit wird in MO_Anzeige_Verbr_Einheit übertragen.";
CM_ SG_ 512 MO_Boost_aktiv "Anzeige im Kombi ob Boost aktiv ist.
Die Anzeige wird zusätzlich über das Signal MO_Boost_verfuegbar gesteuert.
";
CM_ SG_ 512 MO_Boost_verfuegbar "Anzeige des aktuell verfügbaren Boostpotentials im Kombiinstrument.";
CM_ SG_ 512 MO_BZS_Charisma_FahrPr "Rückmeldung des aktuellen Charisma-Fahrprogramms der MSG Betriebsstrategie

MLBevo: Aktuelles Fahrprogramm des Charisma-Teilnehmers (siehe Systemlastenheft Drive Select)
MQB: Istwert der Kennlinie (siehe Systemlastenheft MQB FPA)";
CM_ SG_ 512 MO_BZS_Charisma_Status "Charisma Systemstatus des Charisma-Teilnehmers MSG (Betriebszustände)

Wert 0x3 ist nur für Fahrzeuge ab MQB relevant";
CM_ SG_ 512 MO_Charisma_FahrPr "MLBevo: Aktuelles Fahrprogramm des Charisma-Teilnehmers (siehe Systemlastenheft Drive Select)
MQB: Istwert der Kennlinie (siehe Systemlastenheft MQB FPA)";
CM_ SG_ 512 MO_Charisma_Status "Charisma Systemstatus des Charisma-Teilnehmers

Wert 0x3 ist nur für Fahrzeuge ab MQB relevant";
CM_ SG_ 512 MO_Drehzahlbeeinflussung "Faktor zur Anhebung der Fahrdrehzahl im Warmlauf";
CM_ SG_ 512 MO_Kuehlmitttel_Sensor_AGB2 "Signal der Sensorelektroden für den Kühlmittelfüllstand HV-Kreis im HEV aktuell, entstört, bewertet (OK/Mangel)";
CM_ SG_ 512 MO_Luftpfad_aktiv "Getriebeeingriff wird zusätzlich zum Zündungspfad auch über den Luftpfad umgesetzt, kommt zu MLB neu in die PL48-Getriebe";
CM_ SG_ 512 MO_MAX_Wunschdrehzahl "maximale Motorwunschdrehzahl, die vom Getriebe nicht überschritten werden darf

Signal darf GE_Synchro_Wunschdrehzahl nicht spiegeln";
CM_ SG_ 512 MO_MIN_Wunschdrehzahl "minimale Motorwunschdrehzahl aufgrund Regeneration, die vom Getriebe nicht unterschritten werden darf

Hinweis: 
Ehemaliger Fehlerwert 0xFF wird senderseitig nicht unterstützt. 
Diesen Wert aus Kompatibilitätsgründen nicht neu belegen!";
CM_ SG_ 512 MO_Motorlaufwarnung "Signal zur Anforderung der 'Motorlaufwarnung' im Kombi.";
CM_ SG_ 512 MO_NGS_Position "Messwert des Neutralgangsensors
(nur Handschalter)";
CM_ SG_ 512 MO_NGS_Status "Status des Signals MO_NGS_Position. Das MSG prüft die Plausibilität nur hinsichtlich sicher geöffnetem Triebstrang.";
CM_ SG_ 512 MO_Overboost "Nur Turbo. Anzeige eines Overboostpfeils im Kombi während Overboostzustand der Ladedruckregelung.";
CM_ SG_ 512 MO_Prio_MAX_Wunschdrehzahl "Prioritätsbit der Motorwunschdrehzahl  als MAX";
CM_ SG_ 512 MO_Prio_MIN_Wunschdrehzahl "Prioritätsbit der Motorwunschdrehzahl als MIN";
CM_ SG_ 512 MO_Rampenzeit_Generator_Anf "Das Motorsteuergerät kann eine Load-Response-Zeit des Generators vom Niedervoltenergiemanagement (NVEM) anfordern. Die Load-Response-Zeit wird vom NVEM umgesetzt, wenn dies bordnetzverträglich möglich ist.";
CM_ SG_ 512 MO_Sperrung_FahrPr_BZS "Sperrung einzelner Betriebszustände bzgl. Kommunikation zwischen Motor-SG und Charisma-SG (Gateway)";
CM_ SG_ 512 MO_StSt_Charisma_FahrPr "MLBevo: Aktuelles Fahrprogramm des Charisma-Teilnehmers (siehe Systemlastenheft Drive Select)
MQB: Istwert der Kennlinie (siehe Systemlastenheft MQB FPA)";
CM_ SG_ 512 MO_StSt_Charisma_Status "Charisma Systemstatus des Charisma-Teilnehmers

Wert 0x3 ist nur für Fahrzeuge ab MQB relevant";
CM_ SG_ 512 MO_Text_Aktivierung_Antrieb "Fahrerinformation zur Antriebsstrangaktivierung.";
CM_ SG_ 512 MO_v_Begrenz_Aktivierbar "Fehlerbit wird vom Motor-SG gesetzt, wenn dieses nicht in dieGeschwindigkeits-begrenzung gehen kann, ein Fehler während der v-Begrenzung auftritt oder v > v_Begrenzung - v_Delta";
CM_ SG_ 512 MO_v_Begrenzung_Niveau "Zeigt an, ob eine v-Begrenzung aufgrund Anforderung der Niveauregelung  im MSG aktiv ist oder nicht (Signal für Niveau zum Steuern der Kombianzeige).";
CM_ SG_ 512 PEA_Abschalttexte "Das Signal dient dem Anzeigen von Abschalttexten, wenn PEA nicht verfügbar ist";
CM_ SG_ 512 PEA_Ereignisanzeige "Das Signal dient der Anzeige des Hinweisgrundes";
CM_ SG_ 512 PEA_Ereignisanzeige_temporaer "Signal dient zur Steuerung einer TPA Anzeige im Kombi";
CM_ SG_ 512 PEA_Fahrerinfo "PEA sendet im Hinweis-/Störungsfall an das Kombi Informationen zum Anzeigen (Text + Akustik)";
CM_ SG_ 512 PEA_Fortschrittsanzeige "Ablaufbalken für PEA-Hinweise";
CM_ SG_ 512 PEA_Hinweis "Aufforderung für Fahrerhandlung durch PEA";
CM_ SG_ 512 PEA_Zielgeschw "Das Signal dient der Anzeige einer Geschwindigkeit eines Geschwindigkeitsereignisses für PEA";
CM_ SG_ 512 PEA_Zielgeschw_Einheit "Einheit der anzuzeigenden Zielgeschwindigkeit für PEA (Prädiktiver Effizienz Assistent)";
CM_ SG_ 512 TSK_Akustik "Anforderung zur Ausgabe Akustischer Meldungen des Triebstrangkoordinators";
CM_ SG_ 512 TSK_Fahrzeugstatus_GRA "Zur Anzeige der Nicht-Verfuegbarkeit des Geschwindigkeitsregelanlage im Fahrzeugstatus";
CM_ SG_ 512 TSK_Fahrzeugstatus_Limiter "Zur Anzeige der Nicht-Verfuegbarkeit des Speedlimiters im Fahrzeugstatus";
CM_ SG_ 512 TSK_Fahrzeugstatus_praed_Fkt "Zeigt den Status der Prädiktion der Kundenfunktionen P_LIM und P_ GRA an";
CM_ SG_ 512 TSK_Limiter_Anzeige "Signalisiert den Wunsch des MSG an das Kombiinstrument, seine Anzeige auf Limiter umzuschalten";
CM_ SG_ 512 TSK_Limiter_Fahrerinfo "Fahrerhinweise und Warnungen des Speedlimiters";
CM_ SG_ 512 TSK_naechstes_Event "Anzeige des naechsten Streckenereignisses, welches in der PGRA-PLIM Regelung eine Änderung der Zielgeschwindigkeit zur Folge hat";
CM_ SG_ 512 TSK_naechstes_Event_Einheit "Das Signal zeigt an in welcher Einheit der Hinweis anzuzeigen ist. Bspw. Schilder in mph und Anzeige in Km/h";
CM_ SG_ 512 TSK_praed_Wunschgeschw "Zur Anzeige der prädiktiven Wunschgeschwindigkeit von GRA/Speedlimiter im Kombiinstrument";
CM_ SG_ 512 TSK_praediktiver_Automode "Signal zur Anzeige des Automodes bei praediktivem Limiter/GRA";
CM_ SG_ 512 TSK_praediktiver_Hinweis "Anzeigesteuerung ob Geschwindigkeitshinweis als Vorschlag (zur Übernahme) oder als Hinweis (bei automatischer Übernahme) behandelt werden soll";
CM_ SG_ 512 TSK_Status_Anzeige "Signalisiert den Status von GRA oder Limiter zur Anzeige im Kombiinstrument.
Der Signalwert 'Limitierung_aktiv' wird nur verwendet für den Audi Speedlimiter und zeigt bei aktivier Funktion an, dass nahe an der Abregelgeschwindigkeit gefahren wird und die";
CM_ SG_ 512 TSK_Texte "Textmeldungen des TSK zur Darstellung im Kombi";
CM_ SG_ 512 TSK_Texte_Primaeranz "Trigger für Anzeigetexte von GRA und Limiter, GRA Temporäranzeige (Audi) und Limiter Warnungen

0 keine Anzeige 
1 GRA Symbol passiv xxx km/h / mph (nur Audi)
2 GRA Symbol aktiv xxx km/h / mph (nur Audi)
3 Bremse überhitzt ! (reserv.)
4 Limiter Modu";
CM_ SG_ 512 TSK_Wunschgeschw "Zur Anzeige der Wunschgeschwindigkeit von GRA/Speedlimiter im Kombiinstrument";

CM_ SG_ 332 CE_FlgLnchCtlPreCnd "Launch Control: status of combustion engine preconditions";
CM_ SG_ 332 FoD_DTC_TSK_ACC "DTC ist entweder bereits eingetragen oder wird eingetragen, sobald die zugehörige FOD Funktion freigeschaltet wird.";
CM_ SG_ 332 FoD_DTC_TSK_GRA "DTC ist entweder bereits eingetragen oder wird eingetragen, sobald die zugehörige FoD Funktion freigeschaltet wird.";
CM_ SG_ 332 ISA_Regelung_aktiv "Signalisiert, dass die Regelung zur Überführung der Fahrzeuggeschwindigkeit auf ein gültiges Tempolimit der Funktion Intelligent Speed Assist (ISA) aktiv ist.";
CM_ SG_ 332 ISA_Status "Signalisiert den Status der Funktion Intelligent Speed Assist (ISA). Der Status zeigt an, ob ISA Tempolimits übernimmt und einregelt. Dabei wird unterschieden, ob es sich um eine globale Aktivierung/Deaktivierung der Funktion, oder um eine temporäre Einsc";
CM_ SG_ 332 ISA_Tempolimitwarnung "Signal zur Ausgabe einer Warnung an den Fahrer, wenn bei aktiviertem Intelligent Speed Assit (ISA) das gültige Tempolimit überschritten wird.";
CM_ SG_ 332 MO_Anforderung_HMS "Halteanforderung vom Motor an HMS";
CM_ SG_ 332 MO_EBoost_verf_praed "Zeigt an, ob für eine im Projekt definierte Zeit (max. 10s) E-Boost in Höhe von EM1_maxPred_Moment verfügbar sein wird.

0 - Init_oder_nicht_verfügbar
1 - EBoost_kurzzeit_verfügbar (~3Sek.)
2 - EBoost_langzeit_verfügbar (~10Sek)";
CM_ SG_ 332 MO_eLaunch_verf "Zeigt an, ob aus Antriebssicht E-Launch verfügbar ist.";
CM_ SG_ 332 MO_EMG_Max_Leistung "zugeteilte elektrische Leistung für den motorischen Betrieb;
elektrische Leistung zur Berechnung eines momentan möglichen maximalen Moments";
CM_ SG_ 332 MO_EMG_Min_Leistung "zugeteilte elektrische Leistung für den generatorischen Betrieb;
elektrische Leistung zur Berechnung eines momentan möglichen minimalen Moments";
CM_ SG_ 332 MO_Fahrbereitschaft "Das Signal MO_Fahrbereitschaft zeigt in mehreren Stufen an, ob der Motor in einem anfahrbereiten Zustand ist.";
CM_ SG_ 332 MO_Freilauf_Info "Freilauf Informationssignal vom Motorsteuergerät zum Getriebesteuergerät. Das Motorsteuergerät kann über dieses Signal den Freilauf freigeben, verhindern bzw. explizit anfordern.";
CM_ SG_ 332 MO_Freilauf_Status "Freilauf-Status-Signal vom Frailauf-Master an aktive Freilauf-Teilnehmer. In diesem Signal zeigt der Freilauf-Master an, welchen aktuellen Status die Freilauf-Betriebsstrategie hat.";
CM_ SG_ 332 MO_Heckspoiler_Anf "Anforderung den Heckspoiler zur Ladeluft- bzw. Motorraumkühlung auszufahren.";
CM_ SG_ 332 MO_Klima_Regelmodus "Anforderung an Klima SG zur Regelungsanpassung der HV Klimakomponenten bei bestimmten Umweltbedingungen";
CM_ SG_ 332 MO_Krit_Heckobjekt "Beschreibt die Kritikalität des hinter einem in der Spur fahrenden Fahrzeuges";
CM_ SG_ 332 MO_Kuppl_betaetigt "Das Motorsteuergerät gibt eine plausibilisierte Information aus, ob die Kupplung betätigt oder nicht betätigt wurde.";
CM_ SG_ 332 MO_LaunchControl "Signalisierung einer verfügbaren LaunchControl Funktion ans Kombiinstrument";
CM_ SG_ 332 MO_MVEM_MaxLeistung_MVVerbrauch "Einzuhaltende Max-Grenze der Leistungsaufnahme bzw. -abgabe der 48V-Verbraucher (inkl 48V-DC/DC-Wandler) im 48V-Netz. Für Begrenzung der Leistungsaufnahme der MV-Verbraucher vorgesehen.

Verbrauch - positiv";
CM_ SG_ 332 MO_MVEM_MinLeistung_MVVerbrauch "Einzuhaltende Min-Grenze der Leistungsaufnahme bzw. -abgabe der 48V-Verbraucher (inkl 48V-DC/DC-Wandler) im 48V-Netz. Für Anforderung einer Leistungsaufnahme der MV-Verbraucher vorgesehen. 
 
Verbrauch - positiv
Rückspeisung - negativ";
CM_ SG_ 332 MO_NGS_Gangpos "Gang- bzw. Neutralinformation des erweiterten Neutralgangsensors. Bedingt durch den eingeschränkten Erfassungssbereich des Sensors sind die Ganginformationen als eingelegt bzw. fast eingelegt/vorausgewählt zu interpretieren (nur Handschalter)";
CM_ SG_ 332 MO_Positionierung_aktiv "Zeigt an, dass die Motorpositionierung mit Hilfe des Riemenstartergenerator momentan aktiv ist.";
CM_ SG_ 332 MO_QBit_Aussen_Temp "QBit der Aussentemperatur. Gesetzt bei Ersatzwert, Init oder Fehler.";
CM_ SG_ 332 MO_QBit_Kuppl_betaetigt "Q - Bit für das Signal Kupplung betätigt";
CM_ SG_ 332 MO_Red_El_Fahrleistung "Anzeige einer eingeschränkten Fahrleistung";
CM_ SG_ 332 MO_Servicemodus "Ausgabe aktiver Service-Mode";
CM_ SG_ 332 MO_Startwunsch "o	Setzen bei Erfüllung der kompletten Fahrerbedienhandlung (z.B. Zündanlasstaster + Bremse + Fahrstufe P/N [klassisch] oder Fahrstufe D/R + Bremse [MEB]), je nach Fahrzeug z.T. bereits vor oder immer erst nach Einschalten der Klemme 15;
o	Rücksetzen bei ";
CM_ SG_ 332 MO_UBE_Hybrid_Reserve "Seitens Antrieb in einem (P)HEV erforderliche Energiereserve der HV-Batterie, die den Fußpunkt der „Usable Battery Energy“ (BMS_UBE) verschiebt. Die Reserve dient der Darstellung von Hybrid-Grundfunktionen (z.B. Start/Stopp, elektrisch Kriechen,usw.) unte";
CM_ SG_ 332 MO_UBE_Reserve "Seitens Antrieb erforderliche Energiereserve der HV-Batterie, die den Fußpunkt der „Usable Battery Energy“ (BMS_UBE) verschiebt. Die Reserve dient der Gewährleistung von Sicherheitsfunktionen und ggf. Emissionierungsmaßnahmen unterhalb des Fahrbetriebs im";
CM_ SG_ 332 MO_Veto_Launchcontrol "Veto des Motor-Steuergeräts bzgl. der Aktivierung der Launch-Control";
CM_ SG_ 332 Motor_54_BZ "4bit Botschaftszähler, wird mit jeder Sendebotschaft inkrementiert";
CM_ SG_ 332 Motor_54_CRC "Für MLB:
Berechnung siehe Lastenheft 'Kommunikationsabsicherung für FlexRay und CAN'
Ab MQB und MLBevo:
Berechnung siehe Lastenheft 'End-to-End Kommunikationsabsicherung'

Endwerte siehe Begleitdokument 'S-PDU Kennungsfolgen'";
CM_ SG_ 332 OBD_Abs_Load_Val "Absolute Load Value

Übertragung von Meßgrößen an das Getriebesteuergerät für Freeze Frame Abspeicherung bei Getriebefehlern

PID $43 Absolute Load Value; 0 .. 25700%  mit 100/255 %/bit";
CM_ SG_ 332 OBD_Abs_Pedal_Pos "Absolute Pedal Position

Übertragung von Meßgrößen an das Getriebesteuergerät für Freeze Frame Abspeicherung bei Getriebefehlern

PID $49 Accelerator Pedal Position D; 0 .. 100% mit 100/255 %/bit";
CM_ SG_ 332 OBD_Abs_Throttle_Pos "Absolute Throttle Position

Übertragung von Meßgrößen an das Getriebesteuergerät für Freeze Frame Abspeicherung bei Getriebefehlern

PID $11 Absolute Throttle Position; 0 .. 100% mit 100/255 %/bit";
CM_ SG_ 332 OBD_Aussen_Temp_gef "Gefilterte Aussentemperatur vom Motor für OBD Funktionen.";
CM_ SG_ 332 OBD_Calc_Load_Val "Calculated Load Value

Übertragung von Meßgrößen an das Getriebesteuergerät für Freeze Frame Abspeicherung bei Getriebefehlern

PID $04 Calculated Load Value; 0 .. 100% mit 100/255 % per bit
";
CM_ SG_ 332 OBD_ClearMem_Inhibit "Bei FSP_Loeschen_zulässig müssen alle OBD-ECUs im Gesamtfahrzeug einen Service 04hex Request (Ereignisspeicher löschen) korrekt ausführen. 

In MLB-, MLBevo-, MQB-Fahrzeugkonzepten muss der MIL-Master/Motorsteuergerät bei Kl.15 ein, projektabhängig, kon";
CM_ SG_ 332 OBD_Driving_Cycle "Signalisierung Driving Cycle Qualifizierung - Trigger Ignition Cycle Counter";
CM_ SG_ 332 OBD_Eng_Cool_Temp "Engine Coolant Temperature

Übertragung von Meßgrößen an das Getriebesteuergerät für Freeze Frame Abspeicherung bei Getriebefehlern

PID $05 Engine Coolant Temperature; -40 .. +215°C mit 1°C/bit und 40°C Offset";
CM_ SG_ 332 OBD_Kaltstart_Denominator "Bestimmte Diagnosen werden nur unter Kaltstartbedingungen durchgeführt, der entsprechende Denominator bei IUMPR-pflichtigen Systemen wird anhand dieses vom MSG gebildeten Signals inkrementiert. (Entspricht EVAP-Denominator)";
CM_ SG_ 332 OBD_Minimum_Trip "Grundlage OBD-Gesetz CCR 1968.2 (d)(4.3) Denominator Specifications
Bildung des General Denominator 'Normed Trip':
 600 sec. (kumulativ) Zeit nach Motorstart
 300 sec. (kumulativ) mit Fahrzeuggeschwindigkeit > 25 mph (40 km/h)
 30 sec. (kontinuierlich";
CM_ SG_ 332 OBD_Normed_Trip "Gesetzlich definierte 'Normed Condition' erfüllt, 'General Denominator' darf erhöht werden";
CM_ SG_ 332 OBD_Sperrung_IUMPR "Wenn der General Denominator auf Grund eines Fehlers in den Eingangsgrößen gesperrt wird, wird diese Information über Bussystem als OBD-Statusinformation OBD_Sperrung_IUMPR für andere OBD-Steuergeräte bereitgestellt. 

Das MSG (MIL-Master) setzt dieses ";
CM_ SG_ 332 OBD_Sperrung_Kaltstart_Denom "Information vom MIL Master, dass die Bildung des EVAP Denominators  im Motor nicht möglich ist und damit der noECM-Denominator gesperrt werden darf.";
CM_ SG_ 332 OBD_Warm_Up_Cycle "Mit dem Warm-Up-Cycle wird der zentrale Verlernzähler vom Gateway inkrementiert";
CM_ SG_ 332 OBDProtocol_req "Der PrimaryOBDECU_MILMaster stellt allen PrimaryOBDECUnoMILMaster über das Bussignal [OBDProtocol_req], das für das Fahrzeug zu verwendende OBD-Diagnoseprotokoll bereit.";
CM_ SG_ 332 TSK_ACC_FoD_Status "Information, ob die TSK-ACC-Funktion freigeschaltet ist oder nicht.";
CM_ SG_ 332 TSK_aktives_System "Anzeige der in der TSK-Längsführung aktiven Funktion";
CM_ SG_ 332 TSK_aktives_System_02 "Anzeige der in der TSK-Längsführung aktiven Funktion";
CM_ SG_ 332 TSK_Anf_Antriebsmoment "Das Signal zeigt an, ob die TSK-Laengsregelung aktuell Antriebsmoment anfordert, zur Verwendung in der ASR/EDS-Funktion";
CM_ SG_ 332 TSK_Einheit_vMax_Fahrerassistenz "Einheit zu Signal TSK_vMax_Fahrerassistenz";
CM_ SG_ 332 TSK_erhoehter_Fahrwiderstand "Rueckmeldung vom Triebstrangkoordinator, dass eine große Reglerdifferenz detektiert wurde. Soll ermoeglichen, einen ggfs. unbekannten Fahrwiderstand am Boden zu erkennen.";
CM_ SG_ 332 TSK_GRA_FoD_Status "Information, ob die TSK-GRA-Funktion freigeschaltet ist oder nicht.";
CM_ SG_ 332 TSK_Status_ARA "Funktionsstatus des Triebstrangkoordinators für den Anhängerrangierassistenten";
CM_ SG_ 332 TSK_Status_EA "Funktionsstatus des Triebstrangkoordinators für den Anforderer Emergency Assist";
CM_ SG_ 332 TSK_Status_IPA "Funktionsstatus des Triebstrangkoordinators für die Längsführung des Einparkassistenten";
CM_ SG_ 332 TSK_Status_PLA "Funktionsstatus des Triebstrangkoordinators für den Speedlimiter des Parkassistenten";
CM_ SG_ 332 TSK_Status_RHP "Functional status of the drive train coordinator for the longitudinal guidance of the rush hour pilot.";
CM_ SG_ 332 TSK_vMax_aktuell "Im aktuellen Betriebszustand global gültige Geschwindigkeitslimitierung.";
CM_ SG_ 332 TSK_vMax_Fahrerassistenz "maximale Sollgeschwindigkeit für GRA/ACC/Limiter
Hinweis: Signal ist mit Signal TSK_Einheit_vMax_Fahrerassistenz zu interpretieren.  Das Signal wird abwechselnd in km/h und mph gesendet.";

CM_ SG_ 553 SOK_Motor_54_Signatur "Signatur im Rahmen der durch SOK geschützten Broadcast-Kommunikation

Geschützte Funktion: ORU
Geschützte Botschaft: Motor_54";

CM_ SG_ 246 FDR_Allrad_Anteil_max_sek "Maximaler prozentualer Anteil der sekundären Antriebsachse am Gesamtmoment - wird soweit dies durch die Leistungsfähigkeit der Achse möglich ist eingehalten";
CM_ SG_ 246 FDR_Allrad_Anteil_min_sek "Minimaler prozentualer Anteil der sekundären Antriebsachse am Gesamtmoment - wird soweit dies durch die Leistungsfähigkeit der Achse möglich ist eingehalten";
CM_ SG_ 246 FDR_MomRad_Eingriff "maximal zulässiges Moment primäre Antriebsachse";
CM_ SG_ 246 FDR_MomRad_Eingriff_sek "maximal zulässiges Moment sekundäre Antriebsachse";
CM_ SG_ 246 FDR_Status_Eingriff "Eingriff primäre Antriebsachse aktiv";
CM_ SG_ 246 FDR_Status_Eingriff_sek "Eingriff sekundäre Antriebsachse aktiv";
CM_ SG_ 246 FDR_Zwangszusch_ESP "Mit diesem Bit wird das ESP/ASR zwangsweise aktiviert. Bei gesetztem Bit ist ein ausgetastetes ESP (oder ASR) wieder aktiviert bzw. wird die Austastung verhindert.";
CM_ SG_ 246 MO_EMG_Generator_Leistung "Elektrische Wunschleistung zur Berechnung eines momentan erforderlichen Moments im Generatorbetrieb";
CM_ SG_ 246 MO_EMG_Max_Momentengradient "maximale Änderung des E-Maschinen Moments";
CM_ SG_ 246 MO_EMG_Max_Spannung_Lim "Maximal zulässige Spannung (DC), die vom RSG im generatorischen Betrieb nicht überschritten werden darf; Abregelspannung zur Begrenzung des minimalen Moments im generatorischen Betrieb";
CM_ SG_ 246 MO_EMG_Max_Strom_Lim "maximal zulässiger Strom, der vom RSG im motorischen Betrieb aufgenommen werden darf;
Abregelstrom zur Begrenzung des maximalen Moments im motorischen Betrieb";
CM_ SG_ 246 MO_EMG_Min_Spannung_Lim "Minimal zulässige Spannung (DC), die vom RSG im motorischen Betrieb nicht unterschritten werden darf;
Abregelspannung zur Begrenzung des maximalen Moments im motorischen Betrieb";
CM_ SG_ 246 MO_EMG_Min_Strom_Lim "minimal zulässiger HV-Strom, der von der LE im generatorischen Betrieb abgegeben werden darf (betragsmäßig maximal aber i.d.R. negativ, daher ‚Min‘);
Abregelstrom zur Begrenzung des minimalen Moments im generatorischen Betrieb";
CM_ SG_ 246 MO_EMG_SollDrehzahl "E-Maschinen Soll-Drehzahl";
CM_ SG_ 246 MO_EMG_Sollmodus "Anforderung der Betriebsart der E-Maschine
Werte:
0: Standby; Kommunikation aktiv
1: Momentenregelung
2: Drehzahlregelung (interner Regelkreis)
3: Spannungsregelung
4: Spannungsregelung Batterie Ab
6: Kalibrierung / Anlernen einer neuen EM
8: Frei";
CM_ SG_ 246 MO_EMG_SollMoment_02 "48V-RSG Soll-Moment vom Hybridcontroller";
CM_ SG_ 246 MO_EMG_Sollspannung "Sollspannung des MSGs für den Spannungsgeregelten Modus";
CM_ SG_ 246 MO_Mom_Begr_Fahr_Pred "Einheitenloser Wert!  MO_Faktor_Momente_02  in Motor_Code_01 beachten!

Bei Bezugsdrehzahl quasistationär max. mögliches Moment (Summe aus max. Moment des Verbren-nungsmotors und max. Moment des E-Motors).

Die Bezugsdrehzahl soll je nach Bedienung de";
CM_ SG_ 246 Motor_55_BZ "4bit Botschaftszähler, wird mit jeder Sendebotschaft inkrementiert";
CM_ SG_ 246 Motor_55_CRC "Für MLB:
Berechnung siehe Lastenheft 'Kommunikationsabsicherung für FlexRay und CAN'
Ab MQB und MLBevo:
Berechnung siehe Lastenheft 'End-to-End Kommunikationsabsicherung'

Endwerte siehe Begleitdokument 'S-PDU Kennungsfolgen'";
CM_ SG_ 246 SOK_Motor_55_Signatur "Signatur im Rahmen der durch SOK geschützten Broadcast-Kommunikation

Geschützte Funktion: Bremsfunktionen 
Geschützte Botschaft: Motor_55";
CM_ SG_ 246 TS_Allrad_Anteil_sek "Vom Antrieb gewünschter prozentualer Anteil der sekundären Antriebsachse am Gesamtmoment";
CM_ SG_ 246 TS_Faktor_Radmomente "Schaltet den Wertebereich von Rad-Momenten-Signale diverser SG um, so dass zum einen die max. möglichen Werte übertragen werden können und zum anderen die Auflösung möglichst hoch ist.
Faktor ist über Laufzeit konstant, variiert nur zwischen Fahrzeug-Pro";
CM_ SG_ 246 TS_MomRad_Ist "Gesamt-Istmoment der Antriebsmaschinen, umgerechnet auf Radebene, unter Berücksichtigung der Massenträgheiten der Antriebsmaschinen und des Getriebes, unter Berücksichtigung der Verluste der Antriebsmaschinen, der Nebenaggregate und des Getriebes (d.h. ke";
CM_ SG_ 246 TS_MomRad_Ist_sek "Gesamt-Istmoment der Antriebsmaschinen, umgerechnet auf Radebene, unter Berücksichtigung der Massenträgheiten der Antriebsmaschinen und des Getriebes, unter Berücksichtigung der Verluste der Antriebsmaschinen, der Nebenaggregate und des Getriebes.
Zeigt ";
CM_ SG_ 246 TS_MomRad_Soll_Summe "Faktor in TS_Faktor_Radmomente beachten!

Momentenanforderung aus Fahrpedal bzw. von ACC/GRA bzw. aus dem Leerlaufregler (quasistatischer Anteil); keine Begrenzungen, keine Fahrverhaltensformung, keine Abbildung externer Eingriffsanforderungen; definier";
CM_ SG_ 246 TS_MomRad_verfuegb_max "Faktor in TS_Faktor_Radmomente beachten!

In aktuellem Betriebszustand (u.a. Übersetzung) kurzfristig (ca. 100..200 ms) verfügbares max. positives Moment; 

Zeigt bei antriebstechnisch getrennten Achsen das Moment der primären Achse; zeigt bei mechani";
CM_ SG_ 246 TS_MomRad_verfuegb_max_sek "Faktor in TS_Faktor_Radmomente beachten!

In aktuellem Betriebszustand (u.a. Übersetzung) kurzfristig (ca. 100..200 ms) verfügbares max. positives Moment; 

Zeigt bei antriebstechnisch getrennten Achsen das Moment der sekundären Achse; steht bei mecha";
CM_ SG_ 246 TS_MomRad_verfuegb_maxReku "Faktor in TS_Faktor_Radmomente beachten!

In aktuellem Betriebszustand (u.a. Übersetzung) kurzfristig (ca. 100..200 ms) verfügbares max. negatives Moment; 

Zeigt bei antriebstechnisch getrennten Achsen das Moment der primären Achse; zeigt bei mechani";
CM_ SG_ 246 TS_MomRad_verfuegb_maxReku_sek "Faktor in TS_Faktor_Radmomente beachten!

In aktuellem Betriebszustand (u.a. Übersetzung) kurzfristig (ca. 100..200 ms) verfügbares max. negatives Moment; 

Zeigt bei antriebstechnisch getrennten Achsen das Moment der sekundären Achse; steht bei mecha";
CM_ SG_ 246 TS_MomRad_verfuegb_maxReku_Summe "Im aktuellen Betriebszustand kurzfristig (ca. 100..200 ms) verfügbares max. negatives Summenmoment; definiert auf Bezugsebene Rad.
Faktor in TS_Faktor_Radmomente beachten!";
CM_ SG_ 246 TS_MomRad_Wunsch "Faktor in TS_Faktor_Radmomente beachten!

Wunsch-Moment nach MSG-Betriebs-Strategie-Aufteilung und Umverteilung der Achs-Aufteilung durch EF; nach Lastschlagdämpfung der jeweiligen Achse; incl. Deckelung aufgrund von Schutz-Eingriffen, ohne Berücksichti";
CM_ SG_ 246 TS_MomRad_Wunsch_sek "Faktor in TS_Faktor_Radmomente beachten!

Wunsch-Moment nach MSG-Betriebs-Strategie-Aufteilung und Umverteilung der Achs-Aufteilung durch EF; nach Lastschlagdämpfung der jeweiligen Achse; incl. Deckelung aufgrund von Schutz-Eingriffen, ohne Berücksichti";
CM_ SG_ 246 TS_Status_DrzReg "Dient zur Kommunikation von Fehlerzuständen von Antrieb zum ESC";
CM_ SG_ 246 TS_Status_DrzReg_sek "Dient zur Kommunikation von Fehlerzuständen von Antrieb zum ESC (sekundäre Achse)";
CM_ SG_ 246 TS_Status_MomRad_Ist "Qualitätsstatus zu TS_MomRad_Ist und TS_MomRad_Ist_Sek
Qualifiziert bei antriebstechnisch getrennten Achsen sowohl das Moment der primären Achse als auch das Moment der sekundären Achse, und bei mechanischem Allradantrieb das Gesamtmoment für beide Achse";
BA_DEF_REL_ BU_SG_REL_  "GenSigTimeoutTime" INT 0 65535;
BA_DEF_ BO_  "DiagRequest" ENUM "No", "Yes";
BA_DEF_ BO_  "DiagResponse" ENUM "No", "Yes";
BA_DEF_ BO_  "DiagState" ENUM "No", "Yes";
BA_DEF_ BO_  "GenMsgChkConstant" HEX 0 4095;
BA_DEF_ BO_  "GenMsgCycleTime" INT 0 65535;
BA_DEF_ BO_  "GenMsgCycleTimeFast" INT 0 65535;
BA_DEF_ BO_  "GenMsgDelayTime" INT 0 100000;
BA_DEF_ BO_  "GenMsgILSupport" ENUM "No", "Yes";
BA_DEF_ BO_  "GenMsgNrOfRepetition" INT 0 100;
BA_DEF_ BO_  "GenMsgPDUConstants" STRING;
BA_DEF_ BO_  "GenMsgSendType" ENUM "Cyclic", "not_used", "not_used", "not_used", "not_used", "not_used", "not_used", "IfActive", "NoMsgSendType";
BA_DEF_ BO_  "GenMsgStartDelayTime" INT 0 100000;
BA_DEF_ BO_  "NmMessage" ENUM "No", "Yes";
BA_DEF_ BO_  "NmhMessage" ENUM "No", "Yes";
BA_DEF_ BO_  "MsgType" ENUM "Application", "NM ", "NMH", "TP2.0", "ISO-TP ", "BAP", "EID", "KS", "XCP_PRE_CONFIGURED", "XCP_RUNTIME_CONFIGURED";
BA_DEF_ BO_  "VAGTP20_API" HEX 0 255;
BA_DEF_ BO_  "VAGTP20_DynConnection" ENUM "No", "Yes";
BA_DEF_ BO_  "VAGTP20_DynSetup" ENUM "No", "Yes";
BA_DEF_ BO_  "VAGTP20_StatConnection" ENUM "No", "Yes";
BA_DEF_ BO_  "CANFD_BRS" ENUM "0", "1";
BA_DEF_ BO_  "VFrameFormat" ENUM "StandardCAN", "ExtendedCAN", "reserved", "reserved", "reserved", "reserved", "reserved", "reserved", "reserved", "reserved", "reserved", "reserved", "reserved", "reserved", "StandardCAN_FD", "ExtendedCAN_FD";
BA_DEF_ SG_  "GenSigActiveRepetitions" INT -2147483648 2147483647;
BA_DEF_ SG_  "GenSigInactiveValue" INT -2147483648 2147483647;
BA_DEF_ SG_  "GenSigSendType" ENUM "Cyclic", "OnWrite", "OnWriteWithRepetition", "OnChange", "OnChangeWithRepetition", "IfActive", "IfActiveWithRepetition", "NoSigSendType", "OnChangeAndIfActive", "OnChangeAndIfActiveWithRepetition";
BA_DEF_ SG_  "GenSigStartValue" INT -2147483648 2147483647;
BA_DEF_ SG_  "NWM-WakeupAllowed" ENUM "No", "Yes";
BA_DEF_ SG_  "GenSigFuncType" ENUM "NoFunction", "MsgCounter", "CRC-8", "XOR", "XOR-2", "DatedBit", "SW-Kl15", "CHK", "Constant", "Protocol", "CRC-8-SAE_J1850", "CRC-32", "DataLength", "DataID", "MsgCounter16", "SOK-Signatur", "Cluster";
BA_DEF_ SG_  "GenSigSwitchedByIgnition" ENUM "No", "Yes";
BA_DEF_ SG_  "Fehlerwert" HEX 0 2147483647;
BA_DEF_ SG_  "GenSigMissingSourceValue" HEX 0 2147483647;
BA_DEF_DEF_REL_  "GenSigTimeoutTime" 0;
BA_DEF_DEF_  "DiagRequest" "No";
BA_DEF_DEF_  "DiagResponse" "No";
BA_DEF_DEF_  "DiagState" "No";
BA_DEF_DEF_  "GenMsgChkConstant" 0;
BA_DEF_DEF_  "GenMsgCycleTime" 0;
BA_DEF_DEF_  "GenMsgCycleTimeFast" 0;
BA_DEF_DEF_  "GenMsgDelayTime" 0;
BA_DEF_DEF_  "GenMsgILSupport" "No";
BA_DEF_DEF_  "GenMsgNrOfRepetition" 0;
BA_DEF_DEF_  "GenMsgPDUConstants" "";
BA_DEF_DEF_  "GenMsgSendType" "NoMsgSendType";
BA_DEF_DEF_  "GenMsgStartDelayTime" 0;
BA_DEF_DEF_  "NmMessage" "No";
BA_DEF_DEF_  "NmhMessage" "No";
BA_DEF_DEF_  "MsgType" "Application";
BA_DEF_DEF_  "VAGTP20_API" 0;
BA_DEF_DEF_  "VAGTP20_DynConnection" "No";
BA_DEF_DEF_  "VAGTP20_DynSetup" "No";
BA_DEF_DEF_  "VAGTP20_StatConnection" "No";
BA_DEF_DEF_  "CANFD_BRS" "1";
BA_DEF_DEF_  "VFrameFormat" "StandardCAN";
BA_DEF_DEF_  "GenSigActiveRepetitions" 0;
BA_DEF_DEF_  "GenSigInactiveValue" 0;
BA_DEF_DEF_  "GenSigSendType" "NoSigSendType";
BA_DEF_DEF_  "GenSigStartValue" 0;
BA_DEF_DEF_  "NWM-WakeupAllowed" "No";
BA_DEF_DEF_  "GenSigFuncType" "NoFunction";
BA_DEF_DEF_  "GenSigSwitchedByIgnition" "Yes";
BA_DEF_DEF_  "Fehlerwert" 0;
BA_DEF_DEF_  "GenSigMissingSourceValue" 0;
BA_ "GenMsgCycleTime" BO_ 958 100;
BA_ "GenMsgDelayTime" BO_ 958 10;
BA_ "GenMsgILSupport" BO_ 958 1;
BA_ "GenMsgPDUConstants" BO_ 958 "0x1f,0x28,0xc6,0x85,0xe6,0xf8,0xb0,0x19,0x5b,0x64,0x35,0x21,0xe4,0xf7,0x9c,0x24";
BA_ "GenMsgSendType" BO_ 958 0;
BA_ "VFrameFormat" BO_ 958 14;
BA_ "GenMsgCycleTime" BO_ 1631 500;
BA_ "GenMsgILSupport" BO_ 1631 1;
BA_ "GenMsgSendType" BO_ 1631 0;
BA_ "VFrameFormat" BO_ 1631 14;
BA_ "GenMsgCycleTime" BO_ 1648 500;
BA_ "GenMsgDelayTime" BO_ 1648 20;
BA_ "GenMsgILSupport" BO_ 1648 1;
BA_ "GenMsgSendType" BO_ 1648 0;
BA_ "VFrameFormat" BO_ 1648 14;
BA_ "GenMsgCycleTime" BO_ 1366 1000;
BA_ "GenMsgILSupport" BO_ 1366 1;
BA_ "GenMsgSendType" BO_ 1366 0;
BA_ "VFrameFormat" BO_ 1366 14;
BA_ "GenMsgCycleTime" BO_ 269 10;
BA_ "GenMsgILSupport" BO_ 269 1;
BA_ "GenMsgPDUConstants" BO_ 269 "0x0f,0x67,0x6e,0x8a,0xa9,0xae,0x23,0x22,0x77,0x4d,0xf9,0xd0,0x81,0x51,0x9c,0x80";
BA_ "GenMsgSendType" BO_ 269 0;
BA_ "VFrameFormat" BO_ 269 14;
BA_ "GenMsgCycleTime" BO_ 267 20;
BA_ "GenMsgILSupport" BO_ 267 1;
BA_ "GenMsgPDUConstants" BO_ 267 "0x2c,0xb1,0x1a,0x75,0xbb,0x65,0x79,0x47,0x81,0x2b,0xcc,0x96,0x17,0xdb,0xc0,0x94";
BA_ "GenMsgSendType" BO_ 267 0;
BA_ "VFrameFormat" BO_ 267 14;
BA_ "GenMsgCycleTime" BO_ 512 50;
BA_ "GenMsgILSupport" BO_ 512 1;
BA_ "GenMsgSendType" BO_ 512 0;
BA_ "VFrameFormat" BO_ 512 14;
BA_ "GenMsgCycleTime" BO_ 332 100;
BA_ "GenMsgDelayTime" BO_ 332 10;
BA_ "GenMsgILSupport" BO_ 332 1;
BA_ "GenMsgPDUConstants" BO_ 332 "0x16,0x35,0x59,0x15,0x9a,0x2a,0x97,0xb8,0x0e,0x4e,0x30,0xcc,0xb3,0x07,0x01,0xad";
BA_ "GenMsgSendType" BO_ 332 0;
BA_ "VFrameFormat" BO_ 332 14;
BA_ "GenMsgCycleTime" BO_ 553 100;
BA_ "GenMsgDelayTime" BO_ 553 10;
BA_ "GenMsgSendType" BO_ 553 0;
BA_ "VFrameFormat" BO_ 553 14;
BA_ "GenMsgCycleTime" BO_ 246 10;
BA_ "GenMsgILSupport" BO_ 246 1;
BA_ "GenMsgPDUConstants" BO_ 246 "0xd4,0x37,0x91,0x7d,0x5f,0xf3,0xbc,0xa9,0xd2,0x18,0x96,0x46,0xf8,0x6d,0xf5,0x4d";
BA_ "GenMsgSendType" BO_ 246 0;
BA_ "VFrameFormat" BO_ 246 14;
BA_ "GenSigSendType" SG_ 958 MO_Aussp_Anlass 3;
BA_ "GenSigSwitchedByIgnition" SG_ 958 MO_Aussp_Anlass 0;
BA_ "GenSigSendType" SG_ 958 MO_BKV_Unterdruckwarnung 0;
BA_ "GenSigSwitchedByIgnition" SG_ 958 MO_BKV_Unterdruckwarnung 0;
BA_ "GenSigSendType" SG_ 958 MO_BLS 3;
BA_ "GenSigSwitchedByIgnition" SG_ 958 MO_BLS 0;
BA_ "GenSigSendType" SG_ 958 MO_BMS_NV_Anf_stuetzen 3;
BA_ "GenSigSwitchedByIgnition" SG_ 958 MO_BMS_NV_Anf_stuetzen 0;
BA_ "GenSigSendType" SG_ 958 MO_EKlKomLeiRed 0;
BA_ "GenSigSwitchedByIgnition" SG_ 958 MO_EKlKomLeiRed 0;
BA_ "GenSigSendType" SG_ 958 MO_Ext_E_Fahrt_aktiv 3;
BA_ "NWM-WakeupAllowed" SG_ 958 MO_Ext_E_Fahrt_aktiv 1;
BA_ "GenSigSwitchedByIgnition" SG_ 958 MO_Ext_E_Fahrt_aktiv 0;
BA_ "GenSigSendType" SG_ 958 MO_Fahrer_bremst 3;
BA_ "GenSigSwitchedByIgnition" SG_ 958 MO_Fahrer_bremst 0;
BA_ "GenSigSendType" SG_ 958 MO_FMAus_aktiv 3;
BA_ "GenSigSwitchedByIgnition" SG_ 958 MO_FMAus_aktiv 0;
BA_ "GenSigSendType" SG_ 958 MO_FMAus_Startvariante 3;
BA_ "GenSigSwitchedByIgnition" SG_ 958 MO_FMAus_Startvariante 0;
BA_ "GenSigSendType" SG_ 958 MO_Freig_Anlass 3;
BA_ "GenSigSwitchedByIgnition" SG_ 958 MO_Freig_Anlass 0;
BA_ "GenSigSendType" SG_ 958 MO_Freig_Reku 0;
BA_ "GenSigSwitchedByIgnition" SG_ 958 MO_Freig_Reku 0;
BA_ "GenSigSendType" SG_ 958 MO_Freigabe_Segeln 0;
BA_ "GenSigSwitchedByIgnition" SG_ 958 MO_Freigabe_Segeln 0;
BA_ "GenSigSendType" SG_ 958 MO_Gangposition 3;
BA_ "GenSigStartValue" SG_ 958 MO_Gangposition 14;
BA_ "GenSigSwitchedByIgnition" SG_ 958 MO_Gangposition 0;
BA_ "Fehlerwert" SG_ 958 MO_Gangposition 15;
BA_ "GenSigSendType" SG_ 958 MO_Handshake_STH 0;
BA_ "GenSigSwitchedByIgnition" SG_ 958 MO_Handshake_STH 0;
BA_ "GenSigSendType" SG_ 958 MO_HYB_Fahrbereitschaft 0;
BA_ "GenSigSwitchedByIgnition" SG_ 958 MO_HYB_Fahrbereitschaft 0;
BA_ "GenSigSendType" SG_ 958 MO_HYB_VM_aktiv 3;
BA_ "GenSigSwitchedByIgnition" SG_ 958 MO_HYB_VM_aktiv 0;
BA_ "GenSigSendType" SG_ 958 MO_Interlock 3;
BA_ "GenSigSwitchedByIgnition" SG_ 958 MO_Interlock 0;
BA_ "GenSigSendType" SG_ 958 MO_Kickdown 3;
BA_ "GenSigSwitchedByIgnition" SG_ 958 MO_Kickdown 0;
BA_ "GenSigSendType" SG_ 958 MO_Kl_50 3;
BA_ "GenSigSwitchedByIgnition" SG_ 958 MO_Kl_50 0;
BA_ "GenSigSendType" SG_ 958 MO_Kl_75 3;
BA_ "GenSigSwitchedByIgnition" SG_ 958 MO_Kl_75 0;
BA_ "GenSigSendType" SG_ 958 MO_Klima_Eingr 3;
BA_ "GenSigSwitchedByIgnition" SG_ 958 MO_Klima_Eingr 0;
BA_ "GenSigSendType" SG_ 958 MO_Konsistenz_Bremsped 3;
BA_ "GenSigSwitchedByIgnition" SG_ 958 MO_Konsistenz_Bremsped 0;
BA_ "GenSigSendType" SG_ 958 MO_Kuppl_schalter 3;
BA_ "GenSigSwitchedByIgnition" SG_ 958 MO_Kuppl_schalter 0;
BA_ "GenSigSendType" SG_ 958 MO_Motor_laeuft 3;
BA_ "GenSigSwitchedByIgnition" SG_ 958 MO_Motor_laeuft 0;
BA_ "GenSigSendType" SG_ 958 MO_PTC_Status 0;
BA_ "GenSigSwitchedByIgnition" SG_ 958 MO_PTC_Status 0;
BA_ "GenSigSendType" SG_ 958 MO_QBit_Fahrer_bremst 3;
BA_ "GenSigStartValue" SG_ 958 MO_QBit_Fahrer_bremst 1;
BA_ "GenSigSwitchedByIgnition" SG_ 958 MO_QBit_Fahrer_bremst 0;
BA_ "GenSigSendType" SG_ 958 MO_QBit_Gangposition 3;
BA_ "GenSigStartValue" SG_ 958 MO_QBit_Gangposition 1;
BA_ "GenSigSwitchedByIgnition" SG_ 958 MO_QBit_Gangposition 0;
BA_ "GenSigSendType" SG_ 958 MO_QBit_KL_75 3;
BA_ "GenSigStartValue" SG_ 958 MO_QBit_KL_75 1;
BA_ "GenSigSwitchedByIgnition" SG_ 958 MO_QBit_KL_75 0;
BA_ "GenSigSendType" SG_ 958 MO_Remotestart_Betrieb 3;
BA_ "GenSigSwitchedByIgnition" SG_ 958 MO_Remotestart_Betrieb 0;
BA_ "GenSigSendType" SG_ 958 MO_Remotestart_moeglich 0;
BA_ "GenSigSwitchedByIgnition" SG_ 958 MO_Remotestart_moeglich 0;
BA_ "GenSigSendType" SG_ 958 MO_Signalquelle_Gangposition 0;
BA_ "GenSigSwitchedByIgnition" SG_ 958 MO_Signalquelle_Gangposition 0;
BA_ "GenSigSendType" SG_ 958 MO_StartStopp_Fahrerwunsch 0;
BA_ "GenSigSwitchedByIgnition" SG_ 958 MO_StartStopp_Fahrerwunsch 0;
BA_ "GenSigSendType" SG_ 958 MO_StartStopp_Motorstopp 3;
BA_ "GenSigSwitchedByIgnition" SG_ 958 MO_StartStopp_Motorstopp 0;
BA_ "GenSigSendType" SG_ 958 MO_StartStopp_Status 0;
BA_ "GenSigSwitchedByIgnition" SG_ 958 MO_StartStopp_Status 0;
BA_ "GenSigSendType" SG_ 958 MO_StartStopp_Wiederstart 3;
BA_ "GenSigSwitchedByIgnition" SG_ 958 MO_StartStopp_Wiederstart 0;
BA_ "GenSigSendType" SG_ 958 MO_StartVorauss_erfuellt 3;
BA_ "GenSigStartValue" SG_ 958 MO_StartVorauss_erfuellt 1;
BA_ "GenSigSwitchedByIgnition" SG_ 958 MO_StartVorauss_erfuellt 0;
BA_ "GenSigSendType" SG_ 958 MO_Timeout_ESP 3;
BA_ "GenSigSwitchedByIgnition" SG_ 958 MO_Timeout_ESP 0;
BA_ "GenSigSendType" SG_ 958 MO_Zylinderabschaltung 3;
BA_ "GenSigSwitchedByIgnition" SG_ 958 MO_Zylinderabschaltung 0;
BA_ "GenSigSendType" SG_ 958 Motor_14_BZ 0;
BA_ "GenSigFuncType" SG_ 958 Motor_14_BZ 1;
BA_ "GenSigSwitchedByIgnition" SG_ 958 Motor_14_BZ 0;
BA_ "GenSigSendType" SG_ 958 Motor_14_CRC 0;
BA_ "GenSigFuncType" SG_ 958 Motor_14_CRC 2;
BA_ "GenSigSwitchedByIgnition" SG_ 958 Motor_14_CRC 0;
BA_ "GenSigSendType" SG_ 1631 MO_Anzeige_Kaltleuchte 0;
BA_ "GenSigSwitchedByIgnition" SG_ 1631 MO_Anzeige_Kaltleuchte 0;
BA_ "GenSigSendType" SG_ 1631 MO_DPF_reg 0;
BA_ "GenSigSwitchedByIgnition" SG_ 1631 MO_DPF_reg 0;
BA_ "GenSigSendType" SG_ 1631 MO_Energieinhalt_BMS 0;
BA_ "GenSigStartValue" SG_ 1631 MO_Energieinhalt_BMS 4094;
BA_ "GenSigSwitchedByIgnition" SG_ 1631 MO_Energieinhalt_BMS 0;
BA_ "Fehlerwert" SG_ 1631 MO_Energieinhalt_BMS 4095;
BA_ "GenSigSendType" SG_ 1631 MO_Heizstrom_EKAT 0;
BA_ "GenSigSwitchedByIgnition" SG_ 1631 MO_Heizstrom_EKAT 0;
BA_ "Fehlerwert" SG_ 1631 MO_Heizstrom_EKAT 127;
BA_ "GenSigSendType" SG_ 1631 MO_Heizstrom_SCR 0;
BA_ "GenSigSwitchedByIgnition" SG_ 1631 MO_Heizstrom_SCR 0;
BA_ "Fehlerwert" SG_ 1631 MO_Heizstrom_SCR 63;
BA_ "GenSigSendType" SG_ 1631 MO_P_Generator_ungefiltert_Anf 0;
BA_ "GenSigSwitchedByIgnition" SG_ 1631 MO_P_Generator_ungefiltert_Anf 0;
BA_ "GenSigSendType" SG_ 1631 MO_SpannungsAnf_02 0;
BA_ "GenSigSwitchedByIgnition" SG_ 1631 MO_SpannungsAnf_02 0;
BA_ "GenSigSendType" SG_ 1631 TSK_Fahrzeugmasse_02 0;
BA_ "GenSigSwitchedByIgnition" SG_ 1631 TSK_Fahrzeugmasse_02 0;
BA_ "Fehlerwert" SG_ 1631 TSK_Fahrzeugmasse_02 255;
BA_ "GenSigSendType" SG_ 1631 TSK_Grundmasse 0;
BA_ "GenSigSwitchedByIgnition" SG_ 1631 TSK_Grundmasse 0;
BA_ "GenSigSendType" SG_ 1631 TSK_QBit_Fahrzeugmasse 0;
BA_ "GenSigStartValue" SG_ 1631 TSK_QBit_Fahrzeugmasse 1;
BA_ "GenSigSwitchedByIgnition" SG_ 1631 TSK_QBit_Fahrzeugmasse 0;
BA_ "GenSigSendType" SG_ 1631 TSK_QBit_Steigung 0;
BA_ "GenSigStartValue" SG_ 1631 TSK_QBit_Steigung 1;
BA_ "GenSigSwitchedByIgnition" SG_ 1631 TSK_QBit_Steigung 0;
BA_ "GenSigSendType" SG_ 1631 TSK_Steigung_02 0;
BA_ "GenSigSwitchedByIgnition" SG_ 1631 TSK_Steigung_02 0;
BA_ "Fehlerwert" SG_ 1631 TSK_Steigung_02 255;
BA_ "GenSigSendType" SG_ 1648 MO1_Freigabe_Info_WFS 3;
BA_ "GenSigSwitchedByIgnition" SG_ 1648 MO1_Freigabe_Info_WFS 0;
BA_ "GenSigSendType" SG_ 1648 MO1_Freigabe_Verfallsinfo_WFS 3;
BA_ "GenSigSwitchedByIgnition" SG_ 1648 MO1_Freigabe_Verfallsinfo_WFS 0;
BA_ "GenSigSendType" SG_ 1648 MO1_Sperr_Info_WFS 3;
BA_ "GenSigSwitchedByIgnition" SG_ 1648 MO1_Sperr_Info_WFS 0;
BA_ "GenSigSendType" SG_ 1648 MO_Abstellzeit 0;
BA_ "GenSigStartValue" SG_ 1648 MO_Abstellzeit 254;
BA_ "GenSigSwitchedByIgnition" SG_ 1648 MO_Abstellzeit 0;
BA_ "GenSigSendType" SG_ 1648 MO_Abstellzeit_Status 0;
BA_ "GenSigSwitchedByIgnition" SG_ 1648 MO_Abstellzeit_Status 0;
BA_ "GenSigSendType" SG_ 1648 MO_ANC_Kennfeld_Anf 3;
BA_ "GenSigSwitchedByIgnition" SG_ 1648 MO_ANC_Kennfeld_Anf 0;
BA_ "GenSigSendType" SG_ 1648 MO_Anzahl_Abgesch_Zyl 3;
BA_ "GenSigSwitchedByIgnition" SG_ 1648 MO_Anzahl_Abgesch_Zyl 0;
BA_ "GenSigSendType" SG_ 1648 MO_Bremslicht_Reku 3;
BA_ "GenSigSwitchedByIgnition" SG_ 1648 MO_Bremslicht_Reku 0;
BA_ "GenSigSendType" SG_ 1648 MO_Drehzahl_Warnung 0;
BA_ "GenSigSwitchedByIgnition" SG_ 1648 MO_Drehzahl_Warnung 0;
BA_ "GenSigSendType" SG_ 1648 MO_EPCL 3;
BA_ "GenSigSwitchedByIgnition" SG_ 1648 MO_EPCL 0;
BA_ "GenSigSendType" SG_ 1648 MO_Ethanol_BS_Texte 0;
BA_ "GenSigSwitchedByIgnition" SG_ 1648 MO_Ethanol_BS_Texte 0;
BA_ "GenSigSendType" SG_ 1648 MO_Fahrzeugtyp 0;
BA_ "GenSigFuncType" SG_ 1648 MO_Fahrzeugtyp 8;
BA_ "GenSigSwitchedByIgnition" SG_ 1648 MO_Fahrzeugtyp 0;
BA_ "GenSigSendType" SG_ 1648 MO_Fehler_Zylabsch 0;
BA_ "GenSigSwitchedByIgnition" SG_ 1648 MO_Fehler_Zylabsch 0;
BA_ "GenSigSendType" SG_ 1648 MO_Hybrid_StartStopp_LED 3;
BA_ "GenSigSwitchedByIgnition" SG_ 1648 MO_Hybrid_StartStopp_LED 0;
BA_ "GenSigSendType" SG_ 1648 MO_max_Ladedruck 0;
BA_ "GenSigFuncType" SG_ 1648 MO_max_Ladedruck 8;
BA_ "GenSigSwitchedByIgnition" SG_ 1648 MO_max_Ladedruck 0;
BA_ "GenSigSendType" SG_ 1648 MO_NMAX_Schaltanzeige 3;
BA_ "GenSigSwitchedByIgnition" SG_ 1648 MO_NMAX_Schaltanzeige 0;
BA_ "GenSigSendType" SG_ 1648 MO_obere_Drehzahlgrenze 0;
BA_ "GenSigSwitchedByIgnition" SG_ 1648 MO_obere_Drehzahlgrenze 0;
BA_ "GenSigSendType" SG_ 1648 MO_StartStopp_PopUp 3;
BA_ "GenSigSwitchedByIgnition" SG_ 1648 MO_StartStopp_PopUp 0;
BA_ "GenSigSendType" SG_ 1648 MO_Zylabsch_Texte 0;
BA_ "GenSigSwitchedByIgnition" SG_ 1648 MO_Zylabsch_Texte 0;
BA_ "GenSigSendType" SG_ 1648 MO_Zylabsch_Texte_02 3;
BA_ "GenSigSwitchedByIgnition" SG_ 1648 MO_Zylabsch_Texte_02 0;
BA_ "GenSigSendType" SG_ 1366 MO_Fahrzeugabstellzeit 0;
BA_ "GenSigStartValue" SG_ 1366 MO_Fahrzeugabstellzeit 254;
BA_ "GenSigSwitchedByIgnition" SG_ 1366 MO_Fahrzeugabstellzeit 0;
BA_ "Fehlerwert" SG_ 1366 MO_Fahrzeugabstellzeit 255;
BA_ "GenSigSendType" SG_ 1366 MO_Fahrzeugabstellzeit_Status 0;
BA_ "GenSigSwitchedByIgnition" SG_ 1366 MO_Fahrzeugabstellzeit_Status 0;
BA_ "GenSigSendType" SG_ 1366 MO_HV_Auszeit 0;
BA_ "GenSigStartValue" SG_ 1366 MO_HV_Auszeit 510;
BA_ "GenSigSwitchedByIgnition" SG_ 1366 MO_HV_Auszeit 0;
BA_ "Fehlerwert" SG_ 1366 MO_HV_Auszeit 511;
BA_ "GenSigSendType" SG_ 1366 MO_HV_Auszeit_Status 0;
BA_ "GenSigSwitchedByIgnition" SG_ 1366 MO_HV_Auszeit_Status 0;
BA_ "GenSigSendType" SG_ 1366 MO_Verbau_StartSys_EM_HV 0;
BA_ "GenSigSwitchedByIgnition" SG_ 1366 MO_Verbau_StartSys_EM_HV 0;
BA_ "GenSigSendType" SG_ 1366 MO_Verbau_StartSys_EM_MV 0;
BA_ "GenSigSwitchedByIgnition" SG_ 1366 MO_Verbau_StartSys_EM_MV 0;
BA_ "GenSigSendType" SG_ 1366 MO_Verbau_StartSys_Q_Diode 0;
BA_ "GenSigSwitchedByIgnition" SG_ 1366 MO_Verbau_StartSys_Q_Diode 0;
BA_ "GenSigSendType" SG_ 1366 MO_Verbau_StartSys_Ritzelstarter 0;
BA_ "GenSigSwitchedByIgnition" SG_ 1366 MO_Verbau_StartSys_Ritzelstarter 0;
BA_ "GenSigSendType" SG_ 1366 MO_Verbau_StartSys_RSG_MV 0;
BA_ "GenSigSwitchedByIgnition" SG_ 1366 MO_Verbau_StartSys_RSG_MV 0;
BA_ "GenSigSendType" SG_ 1366 MO_Verbau_StartSys_RSG_NV 0;
BA_ "GenSigSwitchedByIgnition" SG_ 1366 MO_Verbau_StartSys_RSG_NV 0;
BA_ "GenSigSendType" SG_ 1366 MO_Ziel_SoC_Fremdladung 0;
BA_ "GenSigStartValue" SG_ 1366 MO_Ziel_SoC_Fremdladung 254;
BA_ "GenSigSwitchedByIgnition" SG_ 1366 MO_Ziel_SoC_Fremdladung 0;
BA_ "GenSigSendType" SG_ 269 MO_Drehzahl_01 0;
BA_ "GenSigSwitchedByIgnition" SG_ 269 MO_Drehzahl_01 0;
BA_ "GenSigSendType" SG_ 269 MO_Drehzahl_VM 0;
BA_ "GenSigSwitchedByIgnition" SG_ 269 MO_Drehzahl_VM 0;
BA_ "GenSigSendType" SG_ 269 MO_EM1_SollDrehzahl 0;
BA_ "GenSigStartValue" SG_ 269 MO_EM1_SollDrehzahl 32767;
BA_ "GenSigSwitchedByIgnition" SG_ 269 MO_EM1_SollDrehzahl 0;
BA_ "GenSigSendType" SG_ 269 MO_EM2_SollDrehzahl 0;
BA_ "GenSigStartValue" SG_ 269 MO_EM2_SollDrehzahl 32767;
BA_ "GenSigSwitchedByIgnition" SG_ 269 MO_EM2_SollDrehzahl 0;
BA_ "GenSigSendType" SG_ 269 MO_erste_Ungenauschwelle 0;
BA_ "GenSigSwitchedByIgnition" SG_ 269 MO_erste_Ungenauschwelle 0;
BA_ "GenSigSendType" SG_ 269 MO_HYB_E_Faktor 0;
BA_ "GenSigSwitchedByIgnition" SG_ 269 MO_HYB_E_Faktor 0;
BA_ "GenSigSendType" SG_ 269 MO_HYB_EMode_Info 0;
BA_ "GenSigSwitchedByIgnition" SG_ 269 MO_HYB_EMode_Info 0;
BA_ "GenSigSendType" SG_ 269 MO_HYB_Freigabe_VM_Eingr 0;
BA_ "GenSigSwitchedByIgnition" SG_ 269 MO_HYB_Freigabe_VM_Eingr 0;
BA_ "GenSigSendType" SG_ 269 MO_HYB_Komfortstufe 0;
BA_ "GenSigSendType" SG_ 269 MO_HYB_LowSpeedModus 0;
BA_ "GenSigSwitchedByIgnition" SG_ 269 MO_HYB_LowSpeedModus 0;
BA_ "GenSigSendType" SG_ 269 MO_HYB_max_ind_VM_Mom_02 0;
BA_ "GenSigStartValue" SG_ 269 MO_HYB_max_ind_VM_Mom_02 254;
BA_ "GenSigSwitchedByIgnition" SG_ 269 MO_HYB_max_ind_VM_Mom_02 0;
BA_ "Fehlerwert" SG_ 269 MO_HYB_max_ind_VM_Mom_02 255;
BA_ "GenSigSendType" SG_ 269 MO_HYB_Modus_Ankopplung_VM 0;
BA_ "GenSigSwitchedByIgnition" SG_ 269 MO_HYB_Modus_Ankopplung_VM 0;
BA_ "GenSigSendType" SG_ 269 MO_HYB_Schaltverhinderung 0;
BA_ "GenSigSendType" SG_ 269 MO_HYB_Sollstatus_K0 0;
BA_ "GenSigSwitchedByIgnition" SG_ 269 MO_HYB_Sollstatus_K0 0;
BA_ "GenSigSendType" SG_ 269 MO_HYB_Stoppmodus 0;
BA_ "GenSigSendType" SG_ 269 MO_HYB_VM_bereit 0;
BA_ "GenSigSwitchedByIgnition" SG_ 269 MO_HYB_VM_bereit 0;
BA_ "GenSigSendType" SG_ 269 MO_HYB_VM_Mom_oE_02 0;
BA_ "GenSigStartValue" SG_ 269 MO_HYB_VM_Mom_oE_02 254;
BA_ "GenSigSwitchedByIgnition" SG_ 269 MO_HYB_VM_Mom_oE_02 0;
BA_ "Fehlerwert" SG_ 269 MO_HYB_VM_Mom_oE_02 255;
BA_ "GenSigSendType" SG_ 269 MO_HYB_Zielzustand 0;
BA_ "GenSigSwitchedByIgnition" SG_ 269 MO_HYB_Zielzustand 0;
BA_ "Fehlerwert" SG_ 269 MO_HYB_Zielzustand 7;
BA_ "GenSigSendType" SG_ 269 MO_Luftpfad_Verzugszeit_praed 0;
BA_ "GenSigSwitchedByIgnition" SG_ 269 MO_Luftpfad_Verzugszeit_praed 0;
BA_ "GenSigSendType" SG_ 269 MO_Mom_Begr_Fahr 0;
BA_ "GenSigStartValue" SG_ 269 MO_Mom_Begr_Fahr 510;
BA_ "GenSigSwitchedByIgnition" SG_ 269 MO_Mom_Begr_Fahr 0;
BA_ "Fehlerwert" SG_ 269 MO_Mom_Begr_Fahr 511;
BA_ "GenSigSendType" SG_ 269 MO_Mom_Begr_Schalt 0;
BA_ "GenSigStartValue" SG_ 269 MO_Mom_Begr_Schalt 1022;
BA_ "GenSigSwitchedByIgnition" SG_ 269 MO_Mom_Begr_Schalt 0;
BA_ "GenSigSendType" SG_ 269 MO_Mom_Ist_Summe 0;
BA_ "GenSigStartValue" SG_ 269 MO_Mom_Ist_Summe 1022;
BA_ "GenSigSwitchedByIgnition" SG_ 269 MO_Mom_Ist_Summe 0;
BA_ "GenSigSendType" SG_ 269 MO_Mom_neg_verfuegbar 0;
BA_ "GenSigStartValue" SG_ 269 MO_Mom_neg_verfuegbar 510;
BA_ "GenSigSwitchedByIgnition" SG_ 269 MO_Mom_neg_verfuegbar 0;
BA_ "Fehlerwert" SG_ 269 MO_Mom_neg_verfuegbar 511;
BA_ "GenSigSendType" SG_ 269 MO_Mom_Schub 0;
BA_ "GenSigStartValue" SG_ 269 MO_Mom_Schub 510;
BA_ "GenSigSwitchedByIgnition" SG_ 269 MO_Mom_Schub 0;
BA_ "GenSigSendType" SG_ 269 MO_Mom_Soll_gefiltert 0;
BA_ "GenSigStartValue" SG_ 269 MO_Mom_Soll_gefiltert 1022;
BA_ "GenSigSwitchedByIgnition" SG_ 269 MO_Mom_Soll_gefiltert 0;
BA_ "GenSigSendType" SG_ 269 MO_Mom_Soll_Roh 0;
BA_ "GenSigStartValue" SG_ 269 MO_Mom_Soll_Roh 1022;
BA_ "GenSigSwitchedByIgnition" SG_ 269 MO_Mom_Soll_Roh 0;
BA_ "GenSigSendType" SG_ 269 MO_Mom_Traegheit_Summe 0;
BA_ "GenSigStartValue" SG_ 269 MO_Mom_Traegheit_Summe 1022;
BA_ "GenSigSwitchedByIgnition" SG_ 269 MO_Mom_Traegheit_Summe 0;
BA_ "GenSigSendType" SG_ 269 MO_Momentenintegral_02 0;
BA_ "GenSigSwitchedByIgnition" SG_ 269 MO_Momentenintegral_02 0;
BA_ "GenSigSendType" SG_ 269 MO_QBit_Drehzahl_01 0;
BA_ "GenSigStartValue" SG_ 269 MO_QBit_Drehzahl_01 1;
BA_ "GenSigSwitchedByIgnition" SG_ 269 MO_QBit_Drehzahl_01 0;
BA_ "GenSigSendType" SG_ 269 MO_QBit_Motormomente 0;
BA_ "GenSigStartValue" SG_ 269 MO_QBit_Motormomente 1;
BA_ "GenSigSwitchedByIgnition" SG_ 269 MO_QBit_Motormomente 0;
BA_ "GenSigSendType" SG_ 269 MO_Status_Normalbetrieb_01 0;
BA_ "GenSigSwitchedByIgnition" SG_ 269 MO_Status_Normalbetrieb_01 0;
BA_ "GenSigSendType" SG_ 269 MO_TNW_Max_Strom_Lim 0;
BA_ "GenSigStartValue" SG_ 269 MO_TNW_Max_Strom_Lim 8190;
BA_ "GenSigSwitchedByIgnition" SG_ 269 MO_TNW_Max_Strom_Lim 0;
BA_ "GenSigSendType" SG_ 269 MO_TNW_Min_Strom_Lim 0;
BA_ "GenSigStartValue" SG_ 269 MO_TNW_Min_Strom_Lim 8190;
BA_ "GenSigSwitchedByIgnition" SG_ 269 MO_TNW_Min_Strom_Lim 0;
BA_ "GenSigSendType" SG_ 269 Motor_50_BZ 0;
BA_ "GenSigFuncType" SG_ 269 Motor_50_BZ 1;
BA_ "GenSigSwitchedByIgnition" SG_ 269 Motor_50_BZ 0;
BA_ "GenSigSendType" SG_ 269 Motor_50_CRC 0;
BA_ "GenSigFuncType" SG_ 269 Motor_50_CRC 2;
BA_ "GenSigSwitchedByIgnition" SG_ 269 Motor_50_CRC 0;
BA_ "GenSigSendType" SG_ 267 MO_Entkopplung_Sollschlupf 0;
BA_ "GenSigStartValue" SG_ 267 MO_Entkopplung_Sollschlupf 126;
BA_ "GenSigSwitchedByIgnition" SG_ 267 MO_Entkopplung_Sollschlupf 0;
BA_ "GenSigSendType" SG_ 267 MO_Fahrpedalgradient 0;
BA_ "GenSigSwitchedByIgnition" SG_ 267 MO_Fahrpedalgradient 0;
BA_ "Fehlerwert" SG_ 267 MO_Fahrpedalgradient 255;
BA_ "GenSigSendType" SG_ 267 MO_Fahrpedalrohwert_01 0;
BA_ "GenSigSwitchedByIgnition" SG_ 267 MO_Fahrpedalrohwert_01 0;
BA_ "Fehlerwert" SG_ 267 MO_Fahrpedalrohwert_01 255;
BA_ "GenSigSendType" SG_ 267 MO_Moment_im_Leerlauf 0;
BA_ "GenSigSwitchedByIgnition" SG_ 267 MO_Moment_im_Leerlauf 0;
BA_ "GenSigSendType" SG_ 267 MO_QBit_Fahrpedalwerte_01 0;
BA_ "GenSigStartValue" SG_ 267 MO_QBit_Fahrpedalwerte_01 1;
BA_ "GenSigSwitchedByIgnition" SG_ 267 MO_QBit_Fahrpedalwerte_01 0;
BA_ "GenSigSendType" SG_ 267 MO_rel_Saugrohrdruck 0;
BA_ "GenSigSwitchedByIgnition" SG_ 267 MO_rel_Saugrohrdruck 0;
BA_ "Fehlerwert" SG_ 267 MO_rel_Saugrohrdruck 63;
BA_ "GenSigSendType" SG_ 267 MO_rel_Saugrohrdruck_gem_err 0;
BA_ "GenSigSwitchedByIgnition" SG_ 267 MO_rel_Saugrohrdruck_gem_err 0;
BA_ "GenSigSendType" SG_ 267 MO_Schubabschaltung 0;
BA_ "GenSigSwitchedByIgnition" SG_ 267 MO_Schubabschaltung 0;
BA_ "GenSigSendType" SG_ 267 MO_Sig_Fahrpedalgradient 0;
BA_ "GenSigSwitchedByIgnition" SG_ 267 MO_Sig_Fahrpedalgradient 0;
BA_ "GenSigSendType" SG_ 267 MO_Solldrehz_Leerlauf 0;
BA_ "GenSigSwitchedByIgnition" SG_ 267 MO_Solldrehz_Leerlauf 0;
BA_ "GenSigSendType" SG_ 267 MO_StartStopp_StoppVorbereitung 0;
BA_ "GenSigSwitchedByIgnition" SG_ 267 MO_StartStopp_StoppVorbereitung 0;
BA_ "GenSigSendType" SG_ 267 MO_Status_MaxDrzEingriff 0;
BA_ "GenSigSwitchedByIgnition" SG_ 267 MO_Status_MaxDrzEingriff 0;
BA_ "GenSigSendType" SG_ 267 MO_Status_MaxDrzEingriff_sek 0;
BA_ "GenSigSwitchedByIgnition" SG_ 267 MO_Status_MaxDrzEingriff_sek 0;
BA_ "GenSigSendType" SG_ 267 MO_Status_MinDrzEingriff 0;
BA_ "GenSigSwitchedByIgnition" SG_ 267 MO_Status_MinDrzEingriff 0;
BA_ "GenSigSendType" SG_ 267 MO_Status_MinDrzEingriff_sek 0;
BA_ "GenSigSwitchedByIgnition" SG_ 267 MO_Status_MinDrzEingriff_sek 0;
BA_ "GenSigSendType" SG_ 267 MO_temporaere_Fahrerabwesenheit 0;
BA_ "GenSigSwitchedByIgnition" SG_ 267 MO_temporaere_Fahrerabwesenheit 0;
BA_ "GenSigSendType" SG_ 267 Motor_51_BZ 0;
BA_ "GenSigFuncType" SG_ 267 Motor_51_BZ 1;
BA_ "GenSigSwitchedByIgnition" SG_ 267 Motor_51_BZ 0;
BA_ "GenSigSendType" SG_ 267 Motor_51_CRC 0;
BA_ "GenSigFuncType" SG_ 267 Motor_51_CRC 2;
BA_ "GenSigSwitchedByIgnition" SG_ 267 Motor_51_CRC 0;
BA_ "GenSigSendType" SG_ 267 SOK_Motor_51_Signatur 0;
BA_ "GenSigFuncType" SG_ 267 SOK_Motor_51_Signatur 15;
BA_ "GenSigSendType" SG_ 267 TSK_a_Soll_gradientenbegrenzt 0;
BA_ "GenSigStartValue" SG_ 267 TSK_a_Soll_gradientenbegrenzt 127;
BA_ "GenSigSwitchedByIgnition" SG_ 267 TSK_a_Soll_gradientenbegrenzt 0;
BA_ "GenSigSendType" SG_ 267 TSK_ax_Getriebe_02 0;
BA_ "GenSigStartValue" SG_ 267 TSK_ax_Getriebe_02 511;
BA_ "GenSigSwitchedByIgnition" SG_ 267 TSK_ax_Getriebe_02 0;
BA_ "GenSigSendType" SG_ 267 TSK_Freig_Verzoeg_Anf 0;
BA_ "GenSigSwitchedByIgnition" SG_ 267 TSK_Freig_Verzoeg_Anf 0;
BA_ "GenSigSendType" SG_ 267 TSK_Hauptschalter_GRA_ACC 0;
BA_ "GenSigSwitchedByIgnition" SG_ 267 TSK_Hauptschalter_GRA_ACC 0;
BA_ "Fehlerwert" SG_ 267 TSK_Hauptschalter_GRA_ACC 3;
BA_ "GenSigSendType" SG_ 267 TSK_Kategorie_Verzoegerungsfkt 0;
BA_ "GenSigSwitchedByIgnition" SG_ 267 TSK_Kategorie_Verzoegerungsfkt 0;
BA_ "GenSigSendType" SG_ 267 TSK_Limiter_ausgewaehlt 0;
BA_ "GenSigSwitchedByIgnition" SG_ 267 TSK_Limiter_ausgewaehlt 0;
BA_ "GenSigSendType" SG_ 267 TSK_Notstopp_Anf 0;
BA_ "GenSigSwitchedByIgnition" SG_ 267 TSK_Notstopp_Anf 0;
BA_ "GenSigSendType" SG_ 267 TSK_Radbremsmom 0;
BA_ "GenSigSwitchedByIgnition" SG_ 267 TSK_Radbremsmom 0;
BA_ "GenSigSendType" SG_ 267 TSK_Radsollmoment 0;
BA_ "GenSigStartValue" SG_ 267 TSK_Radsollmoment 65534;
BA_ "GenSigSwitchedByIgnition" SG_ 267 TSK_Radsollmoment 0;
BA_ "Fehlerwert" SG_ 267 TSK_Radsollmoment 65535;
BA_ "GenSigSendType" SG_ 267 TSK_SRBM_Anf_ASIL 0;
BA_ "GenSigSwitchedByIgnition" SG_ 267 TSK_SRBM_Anf_ASIL 0;
BA_ "GenSigSendType" SG_ 267 TSK_SRBM_max_Gradient 0;
BA_ "GenSigStartValue" SG_ 267 TSK_SRBM_max_Gradient 126;
BA_ "GenSigSwitchedByIgnition" SG_ 267 TSK_SRBM_max_Gradient 0;
BA_ "Fehlerwert" SG_ 267 TSK_SRBM_max_Gradient 127;
BA_ "GenSigSendType" SG_ 267 TSK_Standby_Anf_ESP 0;
BA_ "GenSigSwitchedByIgnition" SG_ 267 TSK_Standby_Anf_ESP 0;
BA_ "GenSigSendType" SG_ 267 TSK_Status 0;
BA_ "GenSigStartValue" SG_ 267 TSK_Status 1;
BA_ "GenSigSwitchedByIgnition" SG_ 267 TSK_Status 0;
BA_ "GenSigSendType" SG_ 267 TSK_v_Begrenzung_aktiv 0;
BA_ "GenSigSwitchedByIgnition" SG_ 267 TSK_v_Begrenzung_aktiv 0;
BA_ "GenSigSendType" SG_ 267 TSK_zul_Regelabw 0;
BA_ "GenSigSwitchedByIgnition" SG_ 267 TSK_zul_Regelabw 0;
BA_ "GenSigSendType" SG_ 267 TSK_Zwangszusch_ESP 0;
BA_ "GenSigSwitchedByIgnition" SG_ 267 TSK_Zwangszusch_ESP 0;
BA_ "GenSigSendType" SG_ 512 CE_CtrPrpPrep 0;
BA_ "GenSigStartValue" SG_ 512 CE_CtrPrpPrep 7;
BA_ "GenSigSwitchedByIgnition" SG_ 512 CE_CtrPrpPrep 0;
BA_ "GenSigSendType" SG_ 512 CE_FlgEmiColdLmp 0;
BA_ "GenSigSwitchedByIgnition" SG_ 512 CE_FlgEmiColdLmp 0;
BA_ "GenSigSendType" SG_ 512 CE_FlgEmiColdTxt 0;
BA_ "GenSigSwitchedByIgnition" SG_ 512 CE_FlgEmiColdTxt 0;
BA_ "GenSigSendType" SG_ 512 CE_FlgHybModAdvi 0;
BA_ "GenSigSwitchedByIgnition" SG_ 512 CE_FlgHybModAdvi 0;
BA_ "GenSigSendType" SG_ 512 CE_FlgPTLimPrfTxt 0;
BA_ "GenSigSwitchedByIgnition" SG_ 512 CE_FlgPTLimPrfTxt 0;
BA_ "GenSigSendType" SG_ 512 CE_PrctPrpPrep 0;
BA_ "GenSigStartValue" SG_ 512 CE_PrctPrpPrep 126;
BA_ "Fehlerwert" SG_ 512 CE_PrctPrpPrep 127;
BA_ "GenSigSendType" SG_ 512 CE_StLdRdcEmiSysPrep 0;
BA_ "GenSigStartValue" SG_ 512 CE_StLdRdcEmiSysPrep 6;
BA_ "Fehlerwert" SG_ 512 CE_StLdRdcEmiSysPrep 7;
BA_ "GenSigSendType" SG_ 512 CE_StStrtDlyEmiSysPrep 0;
BA_ "GenSigStartValue" SG_ 512 CE_StStrtDlyEmiSysPrep 2;
BA_ "Fehlerwert" SG_ 512 CE_StStrtDlyEmiSysPrep 3;
BA_ "GenSigSendType" SG_ 512 ISA_Tempolimit_Regelung 0;
BA_ "GenSigSwitchedByIgnition" SG_ 512 ISA_Tempolimit_Regelung 0;
BA_ "GenSigSendType" SG_ 512 MO_Antriebsstrang_Warnung_HS 0;
BA_ "GenSigSwitchedByIgnition" SG_ 512 MO_Antriebsstrang_Warnung_HS 0;
BA_ "GenSigSendType" SG_ 512 MO_Anzeige_Betriebsmodus 0;
BA_ "GenSigSwitchedByIgnition" SG_ 512 MO_Anzeige_Betriebsmodus 0;
BA_ "GenSigSendType" SG_ 512 MO_Anzeige_Fahrbereitschaft 0;
BA_ "GenSigSwitchedByIgnition" SG_ 512 MO_Anzeige_Fahrbereitschaft 0;
BA_ "GenSigSendType" SG_ 512 MO_Anzeige_Rekuperation 0;
BA_ "GenSigSwitchedByIgnition" SG_ 512 MO_Anzeige_Rekuperation 0;
BA_ "GenSigSendType" SG_ 512 MO_Anzeige_Verbrauch_oE 0;
BA_ "GenSigSwitchedByIgnition" SG_ 512 MO_Anzeige_Verbrauch_oE 0;
BA_ "GenSigSendType" SG_ 512 MO_Boost_aktiv 0;
BA_ "GenSigSwitchedByIgnition" SG_ 512 MO_Boost_aktiv 0;
BA_ "GenSigSendType" SG_ 512 MO_Boost_verfuegbar 0;
BA_ "GenSigSwitchedByIgnition" SG_ 512 MO_Boost_verfuegbar 0;
BA_ "Fehlerwert" SG_ 512 MO_Boost_verfuegbar 255;
BA_ "GenSigSendType" SG_ 512 MO_BZS_Charisma_FahrPr 0;
BA_ "GenSigSwitchedByIgnition" SG_ 512 MO_BZS_Charisma_FahrPr 0;
BA_ "GenSigSendType" SG_ 512 MO_BZS_Charisma_Status 0;
BA_ "GenSigSwitchedByIgnition" SG_ 512 MO_BZS_Charisma_Status 0;
BA_ "GenSigSendType" SG_ 512 MO_Charisma_FahrPr 0;
BA_ "GenSigSwitchedByIgnition" SG_ 512 MO_Charisma_FahrPr 0;
BA_ "GenSigSendType" SG_ 512 MO_Charisma_Status 0;
BA_ "GenSigSwitchedByIgnition" SG_ 512 MO_Charisma_Status 0;
BA_ "GenSigSendType" SG_ 512 MO_Drehzahlbeeinflussung 0;
BA_ "GenSigSwitchedByIgnition" SG_ 512 MO_Drehzahlbeeinflussung 0;
BA_ "GenSigSendType" SG_ 512 MO_Kuehlmitttel_Sensor_AGB2 0;
BA_ "GenSigSwitchedByIgnition" SG_ 512 MO_Kuehlmitttel_Sensor_AGB2 0;
BA_ "GenSigSendType" SG_ 512 MO_Luftpfad_aktiv 0;
BA_ "GenSigSwitchedByIgnition" SG_ 512 MO_Luftpfad_aktiv 0;
BA_ "GenSigSendType" SG_ 512 MO_MAX_Wunschdrehzahl 0;
BA_ "GenSigSwitchedByIgnition" SG_ 512 MO_MAX_Wunschdrehzahl 0;
BA_ "GenSigSendType" SG_ 512 MO_MIN_Wunschdrehzahl 0;
BA_ "GenSigSwitchedByIgnition" SG_ 512 MO_MIN_Wunschdrehzahl 0;
BA_ "GenSigSendType" SG_ 512 MO_Motorlaufwarnung 0;
BA_ "GenSigSwitchedByIgnition" SG_ 512 MO_Motorlaufwarnung 0;
BA_ "GenSigSendType" SG_ 512 MO_NGS_Position 0;
BA_ "GenSigSwitchedByIgnition" SG_ 512 MO_NGS_Position 0;
BA_ "GenSigSendType" SG_ 512 MO_NGS_Status 0;
BA_ "GenSigSwitchedByIgnition" SG_ 512 MO_NGS_Status 0;
BA_ "Fehlerwert" SG_ 512 MO_NGS_Status 3;
BA_ "GenSigSendType" SG_ 512 MO_Overboost 0;
BA_ "GenSigSwitchedByIgnition" SG_ 512 MO_Overboost 0;
BA_ "GenSigSendType" SG_ 512 MO_Prio_MAX_Wunschdrehzahl 0;
BA_ "GenSigSwitchedByIgnition" SG_ 512 MO_Prio_MAX_Wunschdrehzahl 0;
BA_ "GenSigSendType" SG_ 512 MO_Prio_MIN_Wunschdrehzahl 0;
BA_ "GenSigSwitchedByIgnition" SG_ 512 MO_Prio_MIN_Wunschdrehzahl 0;
BA_ "GenSigSendType" SG_ 512 MO_Rampenzeit_Generator_Anf 0;
BA_ "GenSigStartValue" SG_ 512 MO_Rampenzeit_Generator_Anf 15;
BA_ "GenSigSwitchedByIgnition" SG_ 512 MO_Rampenzeit_Generator_Anf 0;
BA_ "GenSigSendType" SG_ 512 MO_Sperrung_FahrPr_BZS 0;
BA_ "GenSigSwitchedByIgnition" SG_ 512 MO_Sperrung_FahrPr_BZS 0;
BA_ "GenSigSendType" SG_ 512 MO_StSt_Charisma_FahrPr 0;
BA_ "GenSigSwitchedByIgnition" SG_ 512 MO_StSt_Charisma_FahrPr 0;
BA_ "GenSigSendType" SG_ 512 MO_StSt_Charisma_Status 0;
BA_ "GenSigSwitchedByIgnition" SG_ 512 MO_StSt_Charisma_Status 0;
BA_ "GenSigSendType" SG_ 512 MO_Text_Aktivierung_Antrieb 0;
BA_ "GenSigStartValue" SG_ 512 MO_Text_Aktivierung_Antrieb 15;
BA_ "GenSigSwitchedByIgnition" SG_ 512 MO_Text_Aktivierung_Antrieb 0;
BA_ "GenSigSendType" SG_ 512 MO_v_Begrenz_Aktivierbar 0;
BA_ "GenSigSwitchedByIgnition" SG_ 512 MO_v_Begrenz_Aktivierbar 0;
BA_ "GenSigSendType" SG_ 512 MO_v_Begrenzung_Niveau 0;
BA_ "GenSigSwitchedByIgnition" SG_ 512 MO_v_Begrenzung_Niveau 0;
BA_ "GenSigSendType" SG_ 512 PEA_Abschalttexte 0;
BA_ "GenSigSwitchedByIgnition" SG_ 512 PEA_Abschalttexte 0;
BA_ "GenSigSendType" SG_ 512 PEA_Ereignisanzeige 0;
BA_ "GenSigSwitchedByIgnition" SG_ 512 PEA_Ereignisanzeige 0;
BA_ "GenSigSendType" SG_ 512 PEA_Ereignisanzeige_temporaer 0;
BA_ "GenSigSwitchedByIgnition" SG_ 512 PEA_Ereignisanzeige_temporaer 0;
BA_ "GenSigSendType" SG_ 512 PEA_Fahrerinfo 0;
BA_ "GenSigSwitchedByIgnition" SG_ 512 PEA_Fahrerinfo 0;
BA_ "GenSigSendType" SG_ 512 PEA_Fortschrittsanzeige 0;
BA_ "GenSigStartValue" SG_ 512 PEA_Fortschrittsanzeige 127;
BA_ "GenSigSwitchedByIgnition" SG_ 512 PEA_Fortschrittsanzeige 0;
BA_ "GenSigSendType" SG_ 512 PEA_Hinweis 0;
BA_ "GenSigSwitchedByIgnition" SG_ 512 PEA_Hinweis 0;
BA_ "GenSigSendType" SG_ 512 PEA_Zielgeschw 0;
BA_ "GenSigSwitchedByIgnition" SG_ 512 PEA_Zielgeschw 0;
BA_ "GenSigSendType" SG_ 512 PEA_Zielgeschw_Einheit 0;
BA_ "GenSigSwitchedByIgnition" SG_ 512 PEA_Zielgeschw_Einheit 0;
BA_ "GenSigSendType" SG_ 512 TSK_Akustik 0;
BA_ "GenSigSwitchedByIgnition" SG_ 512 TSK_Akustik 0;
BA_ "GenSigSendType" SG_ 512 TSK_Fahrzeugstatus_GRA 0;
BA_ "GenSigSwitchedByIgnition" SG_ 512 TSK_Fahrzeugstatus_GRA 0;
BA_ "GenSigSendType" SG_ 512 TSK_Fahrzeugstatus_Limiter 0;
BA_ "GenSigSwitchedByIgnition" SG_ 512 TSK_Fahrzeugstatus_Limiter 0;
BA_ "GenSigSendType" SG_ 512 TSK_Fahrzeugstatus_praed_Fkt 0;
BA_ "GenSigSwitchedByIgnition" SG_ 512 TSK_Fahrzeugstatus_praed_Fkt 0;
BA_ "GenSigSendType" SG_ 512 TSK_Limiter_Anzeige 0;
BA_ "GenSigSwitchedByIgnition" SG_ 512 TSK_Limiter_Anzeige 0;
BA_ "GenSigSendType" SG_ 512 TSK_Limiter_Fahrerinfo 0;
BA_ "GenSigSwitchedByIgnition" SG_ 512 TSK_Limiter_Fahrerinfo 0;
BA_ "GenSigSendType" SG_ 512 TSK_naechstes_Event 0;
BA_ "GenSigSwitchedByIgnition" SG_ 512 TSK_naechstes_Event 0;
BA_ "GenSigSendType" SG_ 512 TSK_naechstes_Event_Einheit 0;
BA_ "GenSigSwitchedByIgnition" SG_ 512 TSK_naechstes_Event_Einheit 0;
BA_ "GenSigSendType" SG_ 512 TSK_praed_Wunschgeschw 0;
BA_ "GenSigStartValue" SG_ 512 TSK_praed_Wunschgeschw 1022;
BA_ "GenSigSwitchedByIgnition" SG_ 512 TSK_praed_Wunschgeschw 0;
BA_ "GenSigSendType" SG_ 512 TSK_praediktiver_Automode 0;
BA_ "GenSigSwitchedByIgnition" SG_ 512 TSK_praediktiver_Automode 0;
BA_ "GenSigSendType" SG_ 512 TSK_praediktiver_Hinweis 0;
BA_ "GenSigSwitchedByIgnition" SG_ 512 TSK_praediktiver_Hinweis 0;
BA_ "GenSigSendType" SG_ 512 TSK_Status_Anzeige 0;
BA_ "GenSigStartValue" SG_ 512 TSK_Status_Anzeige 1;
BA_ "GenSigSwitchedByIgnition" SG_ 512 TSK_Status_Anzeige 0;
BA_ "GenSigSendType" SG_ 512 TSK_Texte 0;
BA_ "GenSigSwitchedByIgnition" SG_ 512 TSK_Texte 0;
BA_ "GenSigSendType" SG_ 512 TSK_Texte_Primaeranz 0;
BA_ "GenSigSwitchedByIgnition" SG_ 512 TSK_Texte_Primaeranz 0;
BA_ "GenSigSendType" SG_ 512 TSK_Wunschgeschw 0;
BA_ "GenSigSwitchedByIgnition" SG_ 512 TSK_Wunschgeschw 0;
BA_ "GenSigSendType" SG_ 332 CE_FlgLnchCtlPreCnd 0;
BA_ "GenSigSwitchedByIgnition" SG_ 332 CE_FlgLnchCtlPreCnd 0;
BA_ "GenSigSendType" SG_ 332 FoD_DTC_TSK_ACC 0;
BA_ "GenSigSwitchedByIgnition" SG_ 332 FoD_DTC_TSK_ACC 0;
BA_ "GenSigSendType" SG_ 332 FoD_DTC_TSK_GRA 0;
BA_ "GenSigSwitchedByIgnition" SG_ 332 FoD_DTC_TSK_GRA 0;
BA_ "GenSigSendType" SG_ 332 ISA_Regelung_aktiv 3;
BA_ "GenSigSwitchedByIgnition" SG_ 332 ISA_Regelung_aktiv 0;
BA_ "GenSigSendType" SG_ 332 ISA_Status 3;
BA_ "GenSigStartValue" SG_ 332 ISA_Status 1;
BA_ "GenSigSwitchedByIgnition" SG_ 332 ISA_Status 0;
BA_ "GenSigSendType" SG_ 332 ISA_Tempolimitwarnung 3;
BA_ "GenSigSwitchedByIgnition" SG_ 332 ISA_Tempolimitwarnung 0;
BA_ "GenSigSendType" SG_ 332 MO_Anforderung_HMS 3;
BA_ "GenSigSwitchedByIgnition" SG_ 332 MO_Anforderung_HMS 0;
BA_ "GenSigSendType" SG_ 332 MO_EBoost_verf_praed 0;
BA_ "GenSigSwitchedByIgnition" SG_ 332 MO_EBoost_verf_praed 0;
BA_ "GenSigSendType" SG_ 332 MO_eLaunch_verf 0;
BA_ "GenSigSwitchedByIgnition" SG_ 332 MO_eLaunch_verf 0;
BA_ "GenSigSendType" SG_ 332 MO_EMG_Max_Leistung 0;
BA_ "GenSigStartValue" SG_ 332 MO_EMG_Max_Leistung 2046;
BA_ "GenSigSwitchedByIgnition" SG_ 332 MO_EMG_Max_Leistung 0;
BA_ "Fehlerwert" SG_ 332 MO_EMG_Max_Leistung 2047;
BA_ "GenSigSendType" SG_ 332 MO_EMG_Min_Leistung 0;
BA_ "GenSigStartValue" SG_ 332 MO_EMG_Min_Leistung 2046;
BA_ "GenSigSwitchedByIgnition" SG_ 332 MO_EMG_Min_Leistung 0;
BA_ "Fehlerwert" SG_ 332 MO_EMG_Min_Leistung 2047;
BA_ "GenSigSendType" SG_ 332 MO_Fahrbereitschaft 3;
BA_ "GenSigSwitchedByIgnition" SG_ 332 MO_Fahrbereitschaft 0;
BA_ "GenSigSendType" SG_ 332 MO_Freilauf_Info 3;
BA_ "GenSigSwitchedByIgnition" SG_ 332 MO_Freilauf_Info 0;
BA_ "GenSigSendType" SG_ 332 MO_Freilauf_Status 3;
BA_ "GenSigSwitchedByIgnition" SG_ 332 MO_Freilauf_Status 0;
BA_ "Fehlerwert" SG_ 332 MO_Freilauf_Status 7;
BA_ "GenSigSendType" SG_ 332 MO_Heckspoiler_Anf 0;
BA_ "GenSigSwitchedByIgnition" SG_ 332 MO_Heckspoiler_Anf 0;
BA_ "GenSigSendType" SG_ 332 MO_Klima_Regelmodus 0;
BA_ "GenSigSwitchedByIgnition" SG_ 332 MO_Klima_Regelmodus 0;
BA_ "GenSigSendType" SG_ 332 MO_Krit_Heckobjekt 0;
BA_ "GenSigSwitchedByIgnition" SG_ 332 MO_Krit_Heckobjekt 0;
BA_ "Fehlerwert" SG_ 332 MO_Krit_Heckobjekt 7;
BA_ "GenSigSendType" SG_ 332 MO_Kuppl_betaetigt 3;
BA_ "GenSigSwitchedByIgnition" SG_ 332 MO_Kuppl_betaetigt 0;
BA_ "GenSigSendType" SG_ 332 MO_LaunchControl 0;
BA_ "GenSigSwitchedByIgnition" SG_ 332 MO_LaunchControl 0;
BA_ "GenSigSendType" SG_ 332 MO_MVEM_MaxLeistung_MVVerbrauch 0;
BA_ "GenSigStartValue" SG_ 332 MO_MVEM_MaxLeistung_MVVerbrauch 1022;
BA_ "GenSigSwitchedByIgnition" SG_ 332 MO_MVEM_MaxLeistung_MVVerbrauch 0;
BA_ "Fehlerwert" SG_ 332 MO_MVEM_MaxLeistung_MVVerbrauch 1023;
BA_ "GenSigSendType" SG_ 332 MO_MVEM_MinLeistung_MVVerbrauch 0;
BA_ "GenSigStartValue" SG_ 332 MO_MVEM_MinLeistung_MVVerbrauch 1022;
BA_ "GenSigSwitchedByIgnition" SG_ 332 MO_MVEM_MinLeistung_MVVerbrauch 0;
BA_ "Fehlerwert" SG_ 332 MO_MVEM_MinLeistung_MVVerbrauch 1023;
BA_ "GenSigSendType" SG_ 332 MO_NGS_Gangpos 3;
BA_ "GenSigSwitchedByIgnition" SG_ 332 MO_NGS_Gangpos 0;
BA_ "Fehlerwert" SG_ 332 MO_NGS_Gangpos 7;
BA_ "GenSigSendType" SG_ 332 MO_Positionierung_aktiv 0;
BA_ "GenSigSwitchedByIgnition" SG_ 332 MO_Positionierung_aktiv 0;
BA_ "GenSigSendType" SG_ 332 MO_QBit_Aussen_Temp 0;
BA_ "GenSigStartValue" SG_ 332 MO_QBit_Aussen_Temp 1;
BA_ "GenSigSwitchedByIgnition" SG_ 332 MO_QBit_Aussen_Temp 0;
BA_ "GenSigSendType" SG_ 332 MO_QBit_Kuppl_betaetigt 3;
BA_ "GenSigSwitchedByIgnition" SG_ 332 MO_QBit_Kuppl_betaetigt 0;
BA_ "GenSigSendType" SG_ 332 MO_Red_El_Fahrleistung 0;
BA_ "GenSigSwitchedByIgnition" SG_ 332 MO_Red_El_Fahrleistung 0;
BA_ "GenSigSendType" SG_ 332 MO_Servicemodus 0;
BA_ "GenSigSwitchedByIgnition" SG_ 332 MO_Servicemodus 0;
BA_ "GenSigSendType" SG_ 332 MO_Startwunsch 3;
BA_ "GenSigSwitchedByIgnition" SG_ 332 MO_Startwunsch 0;
BA_ "GenSigSendType" SG_ 332 MO_UBE_Hybrid_Reserve 0;
BA_ "GenSigStartValue" SG_ 332 MO_UBE_Hybrid_Reserve 1023;
BA_ "GenSigSwitchedByIgnition" SG_ 332 MO_UBE_Hybrid_Reserve 0;
BA_ "GenSigSendType" SG_ 332 MO_UBE_Reserve 0;
BA_ "GenSigStartValue" SG_ 332 MO_UBE_Reserve 1023;
BA_ "GenSigSwitchedByIgnition" SG_ 332 MO_UBE_Reserve 0;
BA_ "GenSigSendType" SG_ 332 MO_Veto_Launchcontrol 0;
BA_ "GenSigSwitchedByIgnition" SG_ 332 MO_Veto_Launchcontrol 0;
BA_ "GenSigSendType" SG_ 332 Motor_54_BZ 0;
BA_ "GenSigFuncType" SG_ 332 Motor_54_BZ 1;
BA_ "GenSigSwitchedByIgnition" SG_ 332 Motor_54_BZ 0;
BA_ "GenSigSendType" SG_ 332 Motor_54_CRC 0;
BA_ "GenSigFuncType" SG_ 332 Motor_54_CRC 2;
BA_ "GenSigSwitchedByIgnition" SG_ 332 Motor_54_CRC 0;
BA_ "GenSigSendType" SG_ 332 OBD_Abs_Load_Val 0;
BA_ "GenSigStartValue" SG_ 332 OBD_Abs_Load_Val 65535;
BA_ "GenSigSwitchedByIgnition" SG_ 332 OBD_Abs_Load_Val 0;
BA_ "GenSigSendType" SG_ 332 OBD_Abs_Pedal_Pos 0;
BA_ "GenSigStartValue" SG_ 332 OBD_Abs_Pedal_Pos 255;
BA_ "GenSigSwitchedByIgnition" SG_ 332 OBD_Abs_Pedal_Pos 0;
BA_ "GenSigSendType" SG_ 332 OBD_Abs_Throttle_Pos 0;
BA_ "GenSigStartValue" SG_ 332 OBD_Abs_Throttle_Pos 255;
BA_ "GenSigSwitchedByIgnition" SG_ 332 OBD_Abs_Throttle_Pos 0;
BA_ "GenSigSendType" SG_ 332 OBD_Aussen_Temp_gef 0;
BA_ "GenSigStartValue" SG_ 332 OBD_Aussen_Temp_gef 254;
BA_ "GenSigSwitchedByIgnition" SG_ 332 OBD_Aussen_Temp_gef 0;
BA_ "Fehlerwert" SG_ 332 OBD_Aussen_Temp_gef 255;
BA_ "GenSigSendType" SG_ 332 OBD_Calc_Load_Val 0;
BA_ "GenSigStartValue" SG_ 332 OBD_Calc_Load_Val 255;
BA_ "GenSigSwitchedByIgnition" SG_ 332 OBD_Calc_Load_Val 0;
BA_ "GenSigSendType" SG_ 332 OBD_ClearMem_Inhibit 0;
BA_ "GenSigSwitchedByIgnition" SG_ 332 OBD_ClearMem_Inhibit 0;
BA_ "GenSigSendType" SG_ 332 OBD_Driving_Cycle 0;
BA_ "GenSigSwitchedByIgnition" SG_ 332 OBD_Driving_Cycle 0;
BA_ "GenSigSendType" SG_ 332 OBD_Eng_Cool_Temp 0;
BA_ "GenSigStartValue" SG_ 332 OBD_Eng_Cool_Temp 255;
BA_ "GenSigSwitchedByIgnition" SG_ 332 OBD_Eng_Cool_Temp 0;
BA_ "GenSigSendType" SG_ 332 OBD_Kaltstart_Denominator 0;
BA_ "GenSigSwitchedByIgnition" SG_ 332 OBD_Kaltstart_Denominator 0;
BA_ "GenSigSendType" SG_ 332 OBD_Minimum_Trip 0;
BA_ "GenSigSwitchedByIgnition" SG_ 332 OBD_Minimum_Trip 0;
BA_ "GenSigSendType" SG_ 332 OBD_Normed_Trip 0;
BA_ "GenSigSwitchedByIgnition" SG_ 332 OBD_Normed_Trip 0;
BA_ "GenSigSendType" SG_ 332 OBD_Sperrung_IUMPR 0;
BA_ "GenSigSwitchedByIgnition" SG_ 332 OBD_Sperrung_IUMPR 0;
BA_ "GenSigSendType" SG_ 332 OBD_Sperrung_Kaltstart_Denom 0;
BA_ "GenSigSwitchedByIgnition" SG_ 332 OBD_Sperrung_Kaltstart_Denom 0;
BA_ "GenSigSendType" SG_ 332 OBD_Warm_Up_Cycle 0;
BA_ "GenSigSwitchedByIgnition" SG_ 332 OBD_Warm_Up_Cycle 0;
BA_ "GenSigSendType" SG_ 332 OBDProtocol_req 0;
BA_ "GenSigSwitchedByIgnition" SG_ 332 OBDProtocol_req 0;
BA_ "Fehlerwert" SG_ 332 OBDProtocol_req 255;
BA_ "GenSigSendType" SG_ 332 TSK_ACC_FoD_Status 0;
BA_ "GenSigSwitchedByIgnition" SG_ 332 TSK_ACC_FoD_Status 0;
BA_ "GenSigSendType" SG_ 332 TSK_aktives_System 3;
BA_ "GenSigSwitchedByIgnition" SG_ 332 TSK_aktives_System 0;
BA_ "GenSigSendType" SG_ 332 TSK_aktives_System_02 3;
BA_ "GenSigSwitchedByIgnition" SG_ 332 TSK_aktives_System_02 0;
BA_ "GenSigSendType" SG_ 332 TSK_Anf_Antriebsmoment 3;
BA_ "GenSigSwitchedByIgnition" SG_ 332 TSK_Anf_Antriebsmoment 0;
BA_ "GenSigSendType" SG_ 332 TSK_Einheit_vMax_Fahrerassistenz 0;
BA_ "GenSigSwitchedByIgnition" SG_ 332 TSK_Einheit_vMax_Fahrerassistenz 0;
BA_ "GenSigSendType" SG_ 332 TSK_erhoehter_Fahrwiderstand 3;
BA_ "GenSigSwitchedByIgnition" SG_ 332 TSK_erhoehter_Fahrwiderstand 0;
BA_ "GenSigSendType" SG_ 332 TSK_GRA_FoD_Status 0;
BA_ "GenSigSwitchedByIgnition" SG_ 332 TSK_GRA_FoD_Status 0;
BA_ "GenSigSendType" SG_ 332 TSK_Status_ARA 3;
BA_ "GenSigStartValue" SG_ 332 TSK_Status_ARA 1;
BA_ "GenSigSwitchedByIgnition" SG_ 332 TSK_Status_ARA 0;
BA_ "Fehlerwert" SG_ 332 TSK_Status_ARA 7;
BA_ "GenSigSendType" SG_ 332 TSK_Status_EA 3;
BA_ "GenSigStartValue" SG_ 332 TSK_Status_EA 1;
BA_ "GenSigSwitchedByIgnition" SG_ 332 TSK_Status_EA 0;
BA_ "Fehlerwert" SG_ 332 TSK_Status_EA 7;
BA_ "GenSigSendType" SG_ 332 TSK_Status_IPA 3;
BA_ "GenSigStartValue" SG_ 332 TSK_Status_IPA 1;
BA_ "GenSigSwitchedByIgnition" SG_ 332 TSK_Status_IPA 0;
BA_ "Fehlerwert" SG_ 332 TSK_Status_IPA 7;
BA_ "GenSigSendType" SG_ 332 TSK_Status_PLA 3;
BA_ "GenSigStartValue" SG_ 332 TSK_Status_PLA 1;
BA_ "GenSigSwitchedByIgnition" SG_ 332 TSK_Status_PLA 0;
BA_ "Fehlerwert" SG_ 332 TSK_Status_PLA 7;
BA_ "GenSigSendType" SG_ 332 TSK_Status_RHP 3;
BA_ "GenSigStartValue" SG_ 332 TSK_Status_RHP 1;
BA_ "GenSigSwitchedByIgnition" SG_ 332 TSK_Status_RHP 0;
BA_ "GenSigSendType" SG_ 332 TSK_vMax_aktuell 0;
BA_ "GenSigStartValue" SG_ 332 TSK_vMax_aktuell 255;
BA_ "GenSigSendType" SG_ 332 TSK_vMax_Fahrerassistenz 0;
BA_ "GenSigStartValue" SG_ 332 TSK_vMax_Fahrerassistenz 511;
BA_ "GenSigSwitchedByIgnition" SG_ 332 TSK_vMax_Fahrerassistenz 0;
BA_ "GenSigSendType" SG_ 553 SOK_Motor_54_Signatur 0;
BA_ "GenSigFuncType" SG_ 553 SOK_Motor_54_Signatur 15;
BA_ "GenSigSwitchedByIgnition" SG_ 553 SOK_Motor_54_Signatur 0;
BA_ "GenSigSendType" SG_ 246 FDR_Allrad_Anteil_max_sek 0;
BA_ "GenSigStartValue" SG_ 246 FDR_Allrad_Anteil_max_sek 510;
BA_ "Fehlerwert" SG_ 246 FDR_Allrad_Anteil_max_sek 511;
BA_ "GenSigSendType" SG_ 246 FDR_Allrad_Anteil_min_sek 0;
BA_ "GenSigStartValue" SG_ 246 FDR_Allrad_Anteil_min_sek 510;
BA_ "Fehlerwert" SG_ 246 FDR_Allrad_Anteil_min_sek 511;
BA_ "GenSigSendType" SG_ 246 FDR_MomRad_Eingriff 0;
BA_ "GenSigStartValue" SG_ 246 FDR_MomRad_Eingriff 8190;
BA_ "GenSigSwitchedByIgnition" SG_ 246 FDR_MomRad_Eingriff 0;
BA_ "Fehlerwert" SG_ 246 FDR_MomRad_Eingriff 8191;
BA_ "GenSigSendType" SG_ 246 FDR_MomRad_Eingriff_sek 0;
BA_ "GenSigStartValue" SG_ 246 FDR_MomRad_Eingriff_sek 8190;
BA_ "GenSigSwitchedByIgnition" SG_ 246 FDR_MomRad_Eingriff_sek 0;
BA_ "Fehlerwert" SG_ 246 FDR_MomRad_Eingriff_sek 8191;
BA_ "GenSigSendType" SG_ 246 FDR_Status_Eingriff 0;
BA_ "GenSigSwitchedByIgnition" SG_ 246 FDR_Status_Eingriff 0;
BA_ "GenSigSendType" SG_ 246 FDR_Status_Eingriff_sek 0;
BA_ "GenSigSwitchedByIgnition" SG_ 246 FDR_Status_Eingriff_sek 0;
BA_ "GenSigSendType" SG_ 246 FDR_Zwangszusch_ESP 0;
BA_ "GenSigSendType" SG_ 246 MO_EMG_Generator_Leistung 0;
BA_ "GenSigStartValue" SG_ 246 MO_EMG_Generator_Leistung 2046;
BA_ "GenSigSwitchedByIgnition" SG_ 246 MO_EMG_Generator_Leistung 0;
BA_ "Fehlerwert" SG_ 246 MO_EMG_Generator_Leistung 2047;
BA_ "GenSigSendType" SG_ 246 MO_EMG_Max_Momentengradient 0;
BA_ "GenSigStartValue" SG_ 246 MO_EMG_Max_Momentengradient 126;
BA_ "GenSigSwitchedByIgnition" SG_ 246 MO_EMG_Max_Momentengradient 0;
BA_ "GenSigSendType" SG_ 246 MO_EMG_Max_Spannung_Lim 0;
BA_ "GenSigStartValue" SG_ 246 MO_EMG_Max_Spannung_Lim 254;
BA_ "GenSigSwitchedByIgnition" SG_ 246 MO_EMG_Max_Spannung_Lim 0;
BA_ "Fehlerwert" SG_ 246 MO_EMG_Max_Spannung_Lim 255;
BA_ "GenSigSendType" SG_ 246 MO_EMG_Max_Strom_Lim 0;
BA_ "GenSigStartValue" SG_ 246 MO_EMG_Max_Strom_Lim 2046;
BA_ "GenSigSwitchedByIgnition" SG_ 246 MO_EMG_Max_Strom_Lim 0;
BA_ "Fehlerwert" SG_ 246 MO_EMG_Max_Strom_Lim 2047;
BA_ "GenSigSendType" SG_ 246 MO_EMG_Min_Spannung_Lim 0;
BA_ "GenSigStartValue" SG_ 246 MO_EMG_Min_Spannung_Lim 254;
BA_ "GenSigSwitchedByIgnition" SG_ 246 MO_EMG_Min_Spannung_Lim 0;
BA_ "Fehlerwert" SG_ 246 MO_EMG_Min_Spannung_Lim 255;
BA_ "GenSigSendType" SG_ 246 MO_EMG_Min_Strom_Lim 0;
BA_ "GenSigStartValue" SG_ 246 MO_EMG_Min_Strom_Lim 2046;
BA_ "GenSigSwitchedByIgnition" SG_ 246 MO_EMG_Min_Strom_Lim 0;
BA_ "Fehlerwert" SG_ 246 MO_EMG_Min_Strom_Lim 2047;
BA_ "GenSigSendType" SG_ 246 MO_EMG_SollDrehzahl 0;
BA_ "GenSigStartValue" SG_ 246 MO_EMG_SollDrehzahl 32767;
BA_ "GenSigSwitchedByIgnition" SG_ 246 MO_EMG_SollDrehzahl 0;
BA_ "GenSigSendType" SG_ 246 MO_EMG_Sollmodus 0;
BA_ "GenSigStartValue" SG_ 246 MO_EMG_Sollmodus 15;
BA_ "GenSigSwitchedByIgnition" SG_ 246 MO_EMG_Sollmodus 0;
BA_ "GenSigSendType" SG_ 246 MO_EMG_SollMoment_02 0;
BA_ "GenSigStartValue" SG_ 246 MO_EMG_SollMoment_02 65534;
BA_ "GenSigSwitchedByIgnition" SG_ 246 MO_EMG_SollMoment_02 0;
BA_ "GenSigSendType" SG_ 246 MO_EMG_Sollspannung 0;
BA_ "GenSigStartValue" SG_ 246 MO_EMG_Sollspannung 254;
BA_ "GenSigSwitchedByIgnition" SG_ 246 MO_EMG_Sollspannung 0;
BA_ "Fehlerwert" SG_ 246 MO_EMG_Sollspannung 255;
BA_ "GenSigSendType" SG_ 246 MO_Mom_Begr_Fahr_Pred 0;
BA_ "GenSigStartValue" SG_ 246 MO_Mom_Begr_Fahr_Pred 510;
BA_ "GenSigSwitchedByIgnition" SG_ 246 MO_Mom_Begr_Fahr_Pred 0;
BA_ "GenSigSendType" SG_ 246 Motor_55_BZ 0;
BA_ "GenSigFuncType" SG_ 246 Motor_55_BZ 1;
BA_ "GenSigSwitchedByIgnition" SG_ 246 Motor_55_BZ 0;
BA_ "GenSigSendType" SG_ 246 Motor_55_CRC 0;
BA_ "GenSigFuncType" SG_ 246 Motor_55_CRC 2;
BA_ "GenSigSwitchedByIgnition" SG_ 246 Motor_55_CRC 0;
BA_ "GenSigSendType" SG_ 246 SOK_Motor_55_Signatur 0;
BA_ "GenSigFuncType" SG_ 246 SOK_Motor_55_Signatur 15;
BA_ "GenSigSendType" SG_ 246 TS_Allrad_Anteil_sek 0;
BA_ "GenSigStartValue" SG_ 246 TS_Allrad_Anteil_sek 510;
BA_ "GenSigSwitchedByIgnition" SG_ 246 TS_Allrad_Anteil_sek 0;
BA_ "Fehlerwert" SG_ 246 TS_Allrad_Anteil_sek 511;
BA_ "GenSigSendType" SG_ 246 TS_Faktor_Radmomente 0;
BA_ "GenSigSwitchedByIgnition" SG_ 246 TS_Faktor_Radmomente 0;
BA_ "GenSigSendType" SG_ 246 TS_MomRad_Ist 0;
BA_ "GenSigStartValue" SG_ 246 TS_MomRad_Ist 8190;
BA_ "GenSigSwitchedByIgnition" SG_ 246 TS_MomRad_Ist 0;
BA_ "GenSigSendType" SG_ 246 TS_MomRad_Ist_sek 0;
BA_ "GenSigStartValue" SG_ 246 TS_MomRad_Ist_sek 8190;
BA_ "GenSigSwitchedByIgnition" SG_ 246 TS_MomRad_Ist_sek 0;
BA_ "GenSigSendType" SG_ 246 TS_MomRad_Soll_Summe 0;
BA_ "GenSigStartValue" SG_ 246 TS_MomRad_Soll_Summe 8190;
BA_ "GenSigSwitchedByIgnition" SG_ 246 TS_MomRad_Soll_Summe 0;
BA_ "GenSigSendType" SG_ 246 TS_MomRad_verfuegb_max 0;
BA_ "GenSigStartValue" SG_ 246 TS_MomRad_verfuegb_max 4094;
BA_ "GenSigSwitchedByIgnition" SG_ 246 TS_MomRad_verfuegb_max 0;
BA_ "GenSigSendType" SG_ 246 TS_MomRad_verfuegb_max_sek 0;
BA_ "GenSigStartValue" SG_ 246 TS_MomRad_verfuegb_max_sek 4094;
BA_ "GenSigSwitchedByIgnition" SG_ 246 TS_MomRad_verfuegb_max_sek 0;
BA_ "GenSigSendType" SG_ 246 TS_MomRad_verfuegb_maxReku 0;
BA_ "GenSigStartValue" SG_ 246 TS_MomRad_verfuegb_maxReku 4094;
BA_ "GenSigSwitchedByIgnition" SG_ 246 TS_MomRad_verfuegb_maxReku 0;
BA_ "GenSigSendType" SG_ 246 TS_MomRad_verfuegb_maxReku_sek 0;
BA_ "GenSigStartValue" SG_ 246 TS_MomRad_verfuegb_maxReku_sek 4094;
BA_ "GenSigSwitchedByIgnition" SG_ 246 TS_MomRad_verfuegb_maxReku_sek 0;
BA_ "GenSigSendType" SG_ 246 TS_MomRad_verfuegb_maxReku_Summe 0;
BA_ "GenSigStartValue" SG_ 246 TS_MomRad_verfuegb_maxReku_Summe 4094;
BA_ "GenSigSwitchedByIgnition" SG_ 246 TS_MomRad_verfuegb_maxReku_Summe 0;
BA_ "GenSigSendType" SG_ 246 TS_MomRad_Wunsch 0;
BA_ "GenSigStartValue" SG_ 246 TS_MomRad_Wunsch 8190;
BA_ "GenSigSwitchedByIgnition" SG_ 246 TS_MomRad_Wunsch 0;
BA_ "GenSigSendType" SG_ 246 TS_MomRad_Wunsch_sek 0;
BA_ "GenSigStartValue" SG_ 246 TS_MomRad_Wunsch_sek 8190;
BA_ "GenSigSwitchedByIgnition" SG_ 246 TS_MomRad_Wunsch_sek 0;
BA_ "GenSigSendType" SG_ 246 TS_Status_DrzReg 0;
BA_ "GenSigSwitchedByIgnition" SG_ 246 TS_Status_DrzReg 0;
BA_ "GenSigSendType" SG_ 246 TS_Status_DrzReg_sek 0;
BA_ "GenSigSwitchedByIgnition" SG_ 246 TS_Status_DrzReg_sek 0;
BA_ "GenSigSendType" SG_ 246 TS_Status_MomRad_Ist 0;
BA_ "GenSigStartValue" SG_ 246 TS_Status_MomRad_Ist 2;
BA_ "GenSigSwitchedByIgnition" SG_ 246 TS_Status_MomRad_Ist 0;
BA_REL_ "GenSigTimeoutTime" BU_SG_REL_ Airbag SG_ 958 MO_Gangposition 1000;
BA_REL_ "GenSigTimeoutTime" BU_SG_REL_ Airbag SG_ 958 MO_Fahrer_bremst 1000;
BA_REL_ "GenSigTimeoutTime" BU_SG_REL_ Airbag SG_ 958 MO_QBit_Fahrer_bremst 1000;
BA_REL_ "GenSigTimeoutTime" BU_SG_REL_ Airbag SG_ 958 MO_BLS 1000;
BA_REL_ "GenSigTimeoutTime" BU_SG_REL_ Airbag SG_ 958 MO_QBit_Gangposition 1000;
BA_REL_ "GenSigTimeoutTime" BU_SG_REL_ Airbag SG_ 269 MO_QBit_Drehzahl_01 500;
BA_REL_ "GenSigTimeoutTime" BU_SG_REL_ Airbag SG_ 269 MO_Drehzahl_01 500;
BA_REL_ "GenSigTimeoutTime" BU_SG_REL_ Airbag SG_ 267 MO_Fahrpedalrohwert_01 500;
BA_REL_ "GenSigTimeoutTime" BU_SG_REL_ Airbag SG_ 267 MO_QBit_Fahrpedalwerte_01 500;
BA_REL_ "GenSigTimeoutTime" BU_SG_REL_ Airbag SG_ 267 TSK_Status 500;
BA_REL_ "GenSigTimeoutTime" BU_SG_REL_ Airbag SG_ 332 OBD_Abs_Throttle_Pos 1000;
BA_REL_ "GenSigTimeoutTime" BU_SG_REL_ Allrad_Haldex SG_ 958 MO_Gangposition 1000;
BA_REL_ "GenSigTimeoutTime" BU_SG_REL_ Allrad_Haldex SG_ 958 MO_Fahrer_bremst 1000;
BA_REL_ "GenSigTimeoutTime" BU_SG_REL_ Allrad_Haldex SG_ 958 MO_QBit_Fahrer_bremst 1000;
BA_REL_ "GenSigTimeoutTime" BU_SG_REL_ Allrad_Haldex SG_ 958 MO_Kuppl_schalter 1000;
BA_REL_ "GenSigTimeoutTime" BU_SG_REL_ Allrad_Haldex SG_ 269 MO_Mom_Soll_Roh 500;
BA_REL_ "GenSigTimeoutTime" BU_SG_REL_ Allrad_Haldex SG_ 269 MO_Mom_Ist_Summe 500;
BA_REL_ "GenSigTimeoutTime" BU_SG_REL_ Allrad_Haldex SG_ 269 MO_Mom_Soll_gefiltert 500;
BA_REL_ "GenSigTimeoutTime" BU_SG_REL_ Allrad_Haldex SG_ 269 MO_Mom_Schub 500;
BA_REL_ "GenSigTimeoutTime" BU_SG_REL_ Allrad_Haldex SG_ 269 MO_Status_Normalbetrieb_01 500;
BA_REL_ "GenSigTimeoutTime" BU_SG_REL_ Allrad_Haldex SG_ 269 MO_Drehzahl_01 500;
BA_REL_ "GenSigTimeoutTime" BU_SG_REL_ Allrad_Haldex SG_ 267 MO_Fahrpedalrohwert_01 500;
BA_REL_ "GenSigTimeoutTime" BU_SG_REL_ Allrad_Haldex SG_ 267 MO_QBit_Fahrpedalwerte_01 500;
BA_REL_ "GenSigTimeoutTime" BU_SG_REL_ DCC_Gen3 SG_ 269 MO_Mom_Soll_Roh 500;
BA_REL_ "GenSigTimeoutTime" BU_SG_REL_ DCC_Gen3 SG_ 267 MO_Fahrpedalrohwert_01 500;
BA_REL_ "GenSigTimeoutTime" BU_SG_REL_ DCC_Gen3 SG_ 332 OBD_Warm_Up_Cycle 1000;
BA_REL_ "GenSigTimeoutTime" BU_SG_REL_ ESC_MQBW SG_ 958 Motor_14_CRC 1000;
BA_REL_ "GenSigTimeoutTime" BU_SG_REL_ ESC_MQBW SG_ 958 Motor_14_BZ 1000;
BA_REL_ "GenSigTimeoutTime" BU_SG_REL_ ESC_MQBW SG_ 958 MO_StartStopp_Status 1000;
BA_REL_ "GenSigTimeoutTime" BU_SG_REL_ ESC_MQBW SG_ 958 MO_StartStopp_Wiederstart 1000;
BA_REL_ "GenSigTimeoutTime" BU_SG_REL_ ESC_MQBW SG_ 958 MO_StartStopp_Motorstopp 1000;
BA_REL_ "GenSigTimeoutTime" BU_SG_REL_ ESC_MQBW SG_ 958 MO_Kl_75 1000;
BA_REL_ "GenSigTimeoutTime" BU_SG_REL_ ESC_MQBW SG_ 958 MO_Kl_50 1000;
BA_REL_ "GenSigTimeoutTime" BU_SG_REL_ ESC_MQBW SG_ 958 MO_StartStopp_Fahrerwunsch 1000;
BA_REL_ "GenSigTimeoutTime" BU_SG_REL_ ESC_MQBW SG_ 958 MO_HYB_Fahrbereitschaft 1000;
BA_REL_ "GenSigTimeoutTime" BU_SG_REL_ ESC_MQBW SG_ 958 MO_Fahrer_bremst 1000;
BA_REL_ "GenSigTimeoutTime" BU_SG_REL_ ESC_MQBW SG_ 958 MO_QBit_Fahrer_bremst 1000;
BA_REL_ "GenSigTimeoutTime" BU_SG_REL_ ESC_MQBW SG_ 958 MO_BLS 1000;
BA_REL_ "GenSigTimeoutTime" BU_SG_REL_ ESC_MQBW SG_ 958 MO_Timeout_ESP 1000;
BA_REL_ "GenSigTimeoutTime" BU_SG_REL_ ESC_MQBW SG_ 958 MO_Kuppl_schalter 1000;
BA_REL_ "GenSigTimeoutTime" BU_SG_REL_ ESC_MQBW SG_ 958 MO_Motor_laeuft 1000;
BA_REL_ "GenSigTimeoutTime" BU_SG_REL_ ESC_MQBW SG_ 958 MO_Kickdown 1000;
BA_REL_ "GenSigTimeoutTime" BU_SG_REL_ ESC_MQBW SG_ 958 MO_QBit_KL_75 1000;
BA_REL_ "GenSigTimeoutTime" BU_SG_REL_ ESC_MQBW SG_ 958 MO_FMAus_aktiv 1000;
BA_REL_ "GenSigTimeoutTime" BU_SG_REL_ ESC_MQBW SG_ 958 MO_Zylinderabschaltung 1000;
BA_REL_ "GenSigTimeoutTime" BU_SG_REL_ ESC_MQBW SG_ 1631 TSK_QBit_Fahrzeugmasse 5000;
BA_REL_ "GenSigTimeoutTime" BU_SG_REL_ ESC_MQBW SG_ 1631 TSK_Fahrzeugmasse_02 5000;
BA_REL_ "GenSigTimeoutTime" BU_SG_REL_ ESC_MQBW SG_ 1648 MO_Bremslicht_Reku 5000;
BA_REL_ "GenSigTimeoutTime" BU_SG_REL_ ESC_MQBW SG_ 1648 MO_Fahrzeugtyp 5000;
BA_REL_ "GenSigTimeoutTime" BU_SG_REL_ ESC_MQBW SG_ 1648 MO_Anzahl_Abgesch_Zyl 5000;
BA_REL_ "GenSigTimeoutTime" BU_SG_REL_ ESC_MQBW SG_ 269 Motor_50_CRC 500;
BA_REL_ "GenSigTimeoutTime" BU_SG_REL_ ESC_MQBW SG_ 269 Motor_50_BZ 500;
BA_REL_ "GenSigTimeoutTime" BU_SG_REL_ ESC_MQBW SG_ 269 MO_Mom_Soll_Roh 500;
BA_REL_ "GenSigTimeoutTime" BU_SG_REL_ ESC_MQBW SG_ 269 MO_Mom_Ist_Summe 500;
BA_REL_ "GenSigTimeoutTime" BU_SG_REL_ ESC_MQBW SG_ 269 MO_Mom_Traegheit_Summe 500;
BA_REL_ "GenSigTimeoutTime" BU_SG_REL_ ESC_MQBW SG_ 269 MO_Mom_Schub 500;
BA_REL_ "GenSigTimeoutTime" BU_SG_REL_ ESC_MQBW SG_ 269 MO_QBit_Motormomente 500;
BA_REL_ "GenSigTimeoutTime" BU_SG_REL_ ESC_MQBW SG_ 269 MO_QBit_Drehzahl_01 500;
BA_REL_ "GenSigTimeoutTime" BU_SG_REL_ ESC_MQBW SG_ 269 MO_Drehzahl_01 500;
BA_REL_ "GenSigTimeoutTime" BU_SG_REL_ ESC_MQBW SG_ 269 MO_HYB_Zielzustand 500;
BA_REL_ "GenSigTimeoutTime" BU_SG_REL_ ESC_MQBW SG_ 269 MO_Drehzahl_VM 500;
BA_REL_ "GenSigTimeoutTime" BU_SG_REL_ ESC_MQBW SG_ 267 Motor_51_CRC 500;
BA_REL_ "GenSigTimeoutTime" BU_SG_REL_ ESC_MQBW SG_ 267 Motor_51_BZ 500;
BA_REL_ "GenSigTimeoutTime" BU_SG_REL_ ESC_MQBW SG_ 267 MO_Fahrpedalrohwert_01 500;
BA_REL_ "GenSigTimeoutTime" BU_SG_REL_ ESC_MQBW SG_ 267 MO_QBit_Fahrpedalwerte_01 500;
BA_REL_ "GenSigTimeoutTime" BU_SG_REL_ ESC_MQBW SG_ 267 MO_Fahrpedalgradient 500;
BA_REL_ "GenSigTimeoutTime" BU_SG_REL_ ESC_MQBW SG_ 267 MO_Sig_Fahrpedalgradient 500;
BA_REL_ "GenSigTimeoutTime" BU_SG_REL_ ESC_MQBW SG_ 267 MO_Moment_im_Leerlauf 500;
BA_REL_ "GenSigTimeoutTime" BU_SG_REL_ ESC_MQBW SG_ 267 MO_Solldrehz_Leerlauf 500;
BA_REL_ "GenSigTimeoutTime" BU_SG_REL_ ESC_MQBW SG_ 267 MO_temporaere_Fahrerabwesenheit 500;
BA_REL_ "GenSigTimeoutTime" BU_SG_REL_ ESC_MQBW SG_ 267 TSK_Radbremsmom 500;
BA_REL_ "GenSigTimeoutTime" BU_SG_REL_ ESC_MQBW SG_ 267 TSK_Status 500;
BA_REL_ "GenSigTimeoutTime" BU_SG_REL_ ESC_MQBW SG_ 267 TSK_Standby_Anf_ESP 500;
BA_REL_ "GenSigTimeoutTime" BU_SG_REL_ ESC_MQBW SG_ 267 TSK_Freig_Verzoeg_Anf 500;
BA_REL_ "GenSigTimeoutTime" BU_SG_REL_ ESC_MQBW SG_ 267 TSK_SRBM_Anf_ASIL 500;
BA_REL_ "GenSigTimeoutTime" BU_SG_REL_ ESC_MQBW SG_ 267 TSK_Zwangszusch_ESP 500;
BA_REL_ "GenSigTimeoutTime" BU_SG_REL_ ESC_MQBW SG_ 267 TSK_Kategorie_Verzoegerungsfkt 500;
BA_REL_ "GenSigTimeoutTime" BU_SG_REL_ ESC_MQBW SG_ 267 TSK_Notstopp_Anf 500;
BA_REL_ "GenSigTimeoutTime" BU_SG_REL_ ESC_MQBW SG_ 267 TSK_SRBM_max_Gradient 500;
BA_REL_ "GenSigTimeoutTime" BU_SG_REL_ ESC_MQBW SG_ 512 MO_NGS_Position 500;
BA_REL_ "GenSigTimeoutTime" BU_SG_REL_ ESC_MQBW SG_ 512 MO_NGS_Status 500;
BA_REL_ "GenSigTimeoutTime" BU_SG_REL_ ESC_MQBW SG_ 332 Motor_54_CRC 1000;
BA_REL_ "GenSigTimeoutTime" BU_SG_REL_ ESC_MQBW SG_ 332 Motor_54_BZ 1000;
BA_REL_ "GenSigTimeoutTime" BU_SG_REL_ ESC_MQBW SG_ 332 MO_Anforderung_HMS 1000;
BA_REL_ "GenSigTimeoutTime" BU_SG_REL_ ESC_MQBW SG_ 332 TSK_aktives_System_02 1000;
BA_REL_ "GenSigTimeoutTime" BU_SG_REL_ ESC_MQBW SG_ 332 TSK_Status_RHP 1000;
BA_REL_ "GenSigTimeoutTime" BU_SG_REL_ ESC_MQBW SG_ 332 MO_Fahrbereitschaft 1000;
BA_REL_ "GenSigTimeoutTime" BU_SG_REL_ ESC_MQBW SG_ 332 OBDProtocol_req 1000;
BA_REL_ "GenSigTimeoutTime" BU_SG_REL_ ESC_MQBW SG_ 332 OBD_Calc_Load_Val 1000;
BA_REL_ "GenSigTimeoutTime" BU_SG_REL_ ESC_MQBW SG_ 332 OBD_Eng_Cool_Temp 1000;
BA_REL_ "GenSigTimeoutTime" BU_SG_REL_ ESC_MQBW SG_ 332 OBD_Abs_Throttle_Pos 1000;
BA_REL_ "GenSigTimeoutTime" BU_SG_REL_ ESC_MQBW SG_ 332 OBD_Abs_Load_Val 1000;
BA_REL_ "GenSigTimeoutTime" BU_SG_REL_ ESC_MQBW SG_ 332 OBD_Abs_Pedal_Pos 1000;
BA_REL_ "GenSigTimeoutTime" BU_SG_REL_ ESC_MQBW SG_ 332 OBD_ClearMem_Inhibit 1000;
BA_REL_ "GenSigTimeoutTime" BU_SG_REL_ ESC_MQBW SG_ 332 OBD_Sperrung_Kaltstart_Denom 1000;
BA_REL_ "GenSigTimeoutTime" BU_SG_REL_ ESC_MQBW SG_ 332 OBD_Sperrung_IUMPR 1000;
BA_REL_ "GenSigTimeoutTime" BU_SG_REL_ ESC_MQBW SG_ 332 OBD_Kaltstart_Denominator 1000;
BA_REL_ "GenSigTimeoutTime" BU_SG_REL_ ESC_MQBW SG_ 332 OBD_Minimum_Trip 1000;
BA_REL_ "GenSigTimeoutTime" BU_SG_REL_ ESC_MQBW SG_ 332 OBD_Driving_Cycle 1000;
BA_REL_ "GenSigTimeoutTime" BU_SG_REL_ ESC_MQBW SG_ 332 OBD_Warm_Up_Cycle 1000;
BA_REL_ "GenSigTimeoutTime" BU_SG_REL_ ESC_MQBW SG_ 332 OBD_Normed_Trip 1000;
BA_REL_ "GenSigTimeoutTime" BU_SG_REL_ ESC_MQBW SG_ 332 OBD_Aussen_Temp_gef 1000;
BA_REL_ "GenSigTimeoutTime" BU_SG_REL_ ESC_MQBW SG_ 553 SOK_Motor_54_Signatur 1000;
BA_REL_ "GenSigTimeoutTime" BU_SG_REL_ ESC_MQBW SG_ 246 Motor_55_CRC 500;
BA_REL_ "GenSigTimeoutTime" BU_SG_REL_ ESC_MQBW SG_ 246 Motor_55_BZ 500;
BA_REL_ "GenSigTimeoutTime" BU_SG_REL_ ESC_MQBW SG_ 246 TS_Faktor_Radmomente 500;
BA_REL_ "GenSigTimeoutTime" BU_SG_REL_ ESC_MQBW SG_ 246 TS_Status_MomRad_Ist 500;
BA_REL_ "GenSigTimeoutTime" BU_SG_REL_ ESC_MQBW SG_ 246 TS_MomRad_verfuegb_maxReku_Summe 500;
BA_REL_ "GenSigTimeoutTime" BU_SG_REL_ ESC_MQBW SG_ 246 TS_MomRad_Ist 500;
BA_REL_ "GenSigTimeoutTime" BU_SG_REL_ ESC_MQBW SG_ 246 TS_MomRad_Soll_Summe 500;
BA_REL_ "GenSigTimeoutTime" BU_SG_REL_ ESC_MQBW SG_ 246 TS_MomRad_Wunsch 500;
BA_REL_ "GenSigTimeoutTime" BU_SG_REL_ ESC_MQBW SG_ 246 TS_MomRad_Wunsch_sek 500;
BA_REL_ "GenSigTimeoutTime" BU_SG_REL_ ESC_MQBW SG_ 246 TS_MomRad_verfuegb_max 500;
BA_REL_ "GenSigTimeoutTime" BU_SG_REL_ ESC_MQBW SG_ 246 TS_MomRad_verfuegb_maxReku 500;
BA_REL_ "GenSigTimeoutTime" BU_SG_REL_ Lenkhilfe_REPS SG_ 958 MO_StartStopp_Status 1000;
BA_REL_ "GenSigTimeoutTime" BU_SG_REL_ Lenkhilfe_REPS SG_ 958 MO_StartStopp_Wiederstart 1000;
BA_REL_ "GenSigTimeoutTime" BU_SG_REL_ Lenkhilfe_REPS SG_ 958 MO_StartStopp_Motorstopp 1000;
BA_REL_ "GenSigTimeoutTime" BU_SG_REL_ Lenkhilfe_REPS SG_ 958 MO_Kl_75 1000;
BA_REL_ "GenSigTimeoutTime" BU_SG_REL_ Lenkhilfe_REPS SG_ 958 MO_StartStopp_Fahrerwunsch 1000;
BA_REL_ "GenSigTimeoutTime" BU_SG_REL_ Lenkhilfe_REPS SG_ 958 MO_HYB_Fahrbereitschaft 1000;
BA_REL_ "GenSigTimeoutTime" BU_SG_REL_ Lenkhilfe_REPS SG_ 958 MO_BLS 1000;
BA_REL_ "GenSigTimeoutTime" BU_SG_REL_ Lenkhilfe_REPS SG_ 958 MO_Freig_Anlass 1000;
BA_REL_ "GenSigTimeoutTime" BU_SG_REL_ Lenkhilfe_REPS SG_ 958 MO_Kickdown 1000;
BA_REL_ "GenSigTimeoutTime" BU_SG_REL_ Lenkhilfe_REPS SG_ 958 MO_QBit_KL_75 1000;
BA_REL_ "GenSigTimeoutTime" BU_SG_REL_ Lenkhilfe_REPS SG_ 269 MO_Mom_Soll_Roh 500;
BA_REL_ "GenSigTimeoutTime" BU_SG_REL_ Lenkhilfe_REPS SG_ 269 MO_Mom_Ist_Summe 500;
BA_REL_ "GenSigTimeoutTime" BU_SG_REL_ Lenkhilfe_REPS SG_ 269 MO_Mom_Traegheit_Summe 500;
BA_REL_ "GenSigTimeoutTime" BU_SG_REL_ Lenkhilfe_REPS SG_ 269 MO_Mom_Schub 500;
BA_REL_ "GenSigTimeoutTime" BU_SG_REL_ Lenkhilfe_REPS SG_ 269 MO_QBit_Motormomente 500;
BA_REL_ "GenSigTimeoutTime" BU_SG_REL_ Lenkhilfe_REPS SG_ 269 MO_QBit_Drehzahl_01 500;
BA_REL_ "GenSigTimeoutTime" BU_SG_REL_ Lenkhilfe_REPS SG_ 269 MO_Drehzahl_01 500;
BA_REL_ "GenSigTimeoutTime" BU_SG_REL_ Lenkhilfe_REPS SG_ 267 MO_Fahrpedalrohwert_01 500;
BA_REL_ "GenSigTimeoutTime" BU_SG_REL_ Lenkhilfe_REPS SG_ 267 MO_QBit_Fahrpedalwerte_01 500;
BA_REL_ "GenSigTimeoutTime" BU_SG_REL_ Lenkhilfe_REPS SG_ 332 MO_Fahrbereitschaft 1000;
BA_REL_ "GenSigTimeoutTime" BU_SG_REL_ Lenkhilfe_REPS SG_ 332 OBD_Warm_Up_Cycle 1000;
VAL_ 958 MO_StartStopp_Status 0 "System_in_diesem_KL15_Zyklus_nicht_verfuegbar" 1 "System_aktiv_keine_Freigabe_durch_StartStop_Koordinator" 2 "System_aktiv_alle_Freigaben_liegen_vor" 3 "System_aktiv_mindestens_eine_Freigabe_fehlt" ;
VAL_ 958 MO_StartStopp_Wiederstart 0 "Wiederstart_inaktiv" 1 "Wiederstart_aktiv" ;
VAL_ 958 MO_StartStopp_Motorstopp 0 "Motor_Stop_inaktiv" 1 "Motor_Stop_aktiv" ;
VAL_ 958 MO_Freig_Reku 0 "Rekuperations-Modus aus" 1 "Empfehlung Spannungsanhebung" 2 "Empfehlung Spannungsabsenkung" 3 "Rekuperationsmodus aktiv, Spannungsvariation nicht notwendig" ;
VAL_ 958 MO_Kl_75 0 "Aus" 1 "Ein" ;
VAL_ 958 MO_Kl_50 0 "aus" 1 "KL50_ein_Startausfuehrung_Fahrer" ;
VAL_ 958 MO_Gangposition 0 "Gang_N" 1 "Gang_1" 2 "Gang_2" 3 "Gang_3" 4 "Gang_4" 5 "Gang_5" 6 "Gang_6" 7 "Gang_7" 8 "Gang_8" 9 "Automat_P" 10 "Automat_Vorwaerts_S" 11 "Automat_Vorwaerts_D/E" 12 "Zwischenstellung" 13 "Gang_R" 14 "Istgang_nicht_definiert" 15 "Fehler" ;
VAL_ 958 MO_StartStopp_Fahrerwunsch 0 "Init" 1 "Stoppverbot_durch_Fahrer" 2 "Stoppfreigabe_durch_Fahrer" 3 "Stoppanforderung_durch_Fahrer" ;
VAL_ 958 MO_HYB_Fahrbereitschaft 0 "keine_Fahrbereitschaft" 1 "Fahrbereitschaft" ;
VAL_ 958 MO_Ext_E_Fahrt_aktiv 0 "Rueckmeldung_E_Taster_aus" 1 "Rueckmeldung_E_Taster_ein" ;
VAL_ 958 MO_Fahrer_bremst 0 "kein_Bremsen" 1 "Bremse_betaetigt" ;
VAL_ 958 MO_QBit_Fahrer_bremst 0 "gueltiger_Wert" 1 "Ersatz_Init_oder_Fehlerwert" ;
VAL_ 958 MO_BLS 0 "kein_Bremsen" 1 "Bremse_betaetigt" ;
VAL_ 958 MO_Konsistenz_Bremsped 0 "Bremspedalinformation_plausibel" 1 "Bremspedalinformation_unplausibel" ;
VAL_ 958 MO_Timeout_ESP 0 "Empfang_iO" 1 "Timeout" ;
VAL_ 958 MO_Klima_Eingr 0 "kein Eingriff" 1 "Klimakompressor ausschalten" 2 "Klimakompressor Leistungsreduzierung" 3 "Klimakompressor aufgrund der Heissleuchtenvorwarnung ausschalten" ;
VAL_ 958 MO_Aussp_Anlass 0 "Anlasser_darf_angesteuert_werden" 1 "Anlasser_ausspuren__Ansteuerung_nicht_moeglich" ;
VAL_ 958 MO_Freig_Anlass 0 "Start_nicht_zulaessig" 1 "Startfreigabe" ;
VAL_ 958 MO_Kuppl_schalter 0 "Schalter_sagt_ausgekuppelt" 1 "Schalter_sagt_eingekuppelt" ;
VAL_ 958 MO_Interlock 0 "Interlockschalter_nicht_betaetigt" 1 "Interlockschalter_betaetigt" ;
VAL_ 958 MO_Motor_laeuft 0 "Motor_laeuft_nicht" 1 "Motor_laeuft_autark_und_stabil_und_darf_mechanisch_belastet_werden" ;
VAL_ 958 MO_Kickdown 0 "kein_Kickdown" 1 "Kickdown" ;
VAL_ 958 MO_QBit_KL_75 0 "gueltiger_Wert" 1 "Ersatz_Init_oder_Fehlerwert" ;
VAL_ 958 MO_EKlKomLeiRed 0 "keine_Leistungsbegr" 1 "Leistungsbegr_75" 2 "Leistungsbegr_50" 3 "Leistungsbegr_25" ;
VAL_ 958 MO_Handshake_STH 0 "keine EKP-Ansteuerung durch STH-Anforderung" 1 "EKP-Ansteuerung durch STH-Anforderung" ;
VAL_ 958 MO_BKV_Unterdruckwarnung 0 "Unterdruckhaushalt_iO" 1 "Unterdruckhaushalt_niO" ;
VAL_ 958 MO_Freigabe_Segeln 0 "Segelbetrieb_nicht_freigegeben" 1 "Segelbetrieb_freigegeben" ;
VAL_ 958 MO_PTC_Status 0 "nicht_unterstuetzt" 1 "Stufe_0" 2 "Stufe_1" 3 "Stufe_2" 4 "Stufe_3" 7 "PTC_am_BCM" ;
VAL_ 958 MO_QBit_Gangposition 0 "gueltiger_Wert" 1 "Ersatz_Init_oder_Fehlerwert" ;
VAL_ 958 MO_Signalquelle_Gangposition 0 "Sensorsignal" 1 "Modellsignal" ;
VAL_ 958 MO_Remotestart_Betrieb 0 "MSG_nicht_bereit_fuer_RS_Betrieb" 1 "MSG_bereit_fuer_oder_im_RS_Betrieb" ;
VAL_ 958 MO_Remotestart_moeglich 0 "Remotestart_nicht_moeglich" 1 "Remotestart_moeglich" ;
VAL_ 958 MO_FMAus_aktiv 0 "inaktiv" 1 "Segeln_mit_Motor_aus_aktiv" ;
VAL_ 958 MO_FMAus_Startvariante 0 "kein_Motorstart" 1 "Motorstart_elektrischer_Starter" 2 "GetriebeAnschleppstart" 3 "GetriebeNotAnschleppstart" ;
VAL_ 958 MO_BMS_NV_Anf_stuetzen 0 "nicht_notwendig" 1 "notwendig" ;
VAL_ 958 MO_Zylinderabschaltung 0 "Vollmotorbetrieb_VMB" 1 "Uebergang_HMB_in_VMB" 2 "Uebergang_VMB_in_HMB" 3 "Halbmotorbetrieb_HMB" ;
VAL_ 958 MO_HYB_VM_aktiv 0 "VM_nicht_aktiv" 1 "VM_aktiv" ;
VAL_ 958 MO_StartVorauss_erfuellt 0 "Signal_nicht_bedient" 1 "StartVorauss_nicht_ueberpruefbar" 2 "StartVorauss_nicht_erfuellt" 3 "StartVorauss_erfuellt" ;
VAL_ 1631 TSK_QBit_Steigung 0 "gueltiger_Wert" 1 "Ersatz_Init_oder_Fehlerwert" ;
VAL_ 1631 TSK_QBit_Fahrzeugmasse 0 "gueltiger_Wert" 1 "Ersatz_Init_oder_Fehlerwert" ;
VAL_ 1631 MO_SpannungsAnf_02 0 "keine_Anforderung" 1 "Anforderung_Stufe_1" 2 "Anforderung_Stufe_2" 3 "Anforderung_Stufe_3" ;
VAL_ 1631 MO_DPF_reg 0 "DPF_regeneriert_nicht" 1 "DPF_regeneriert" ;
VAL_ 1631 MO_Heizstrom_EKAT 127 "Fehler" ;
VAL_ 1631 MO_Heizstrom_SCR 63 "Fehler" ;
VAL_ 1631 MO_Anzeige_Kaltleuchte 0 "Lampe_aus" 1 "Lampe_an" ;
VAL_ 1631 MO_P_Generator_ungefiltert_Anf 0 "nicht_angefordert" 1 "angefordert" ;
VAL_ 1631 MO_Energieinhalt_BMS 4094 "Init" 4095 "Fehler" ;
VAL_ 1631 TSK_Fahrzeugmasse_02 255 "Fehler" ;
VAL_ 1631 TSK_Steigung_02 0 "Init_oder_nicht_verbaut" 255 "Fehler" ;
VAL_ 1648 MO_ANC_Kennfeld_Anf 0 "Kennfeld_1" 1 "Uebergang_Kennfeld_2_nach_1" 2 "Uebergang_Kennfeld_1_nach_2" 3 "Kennfeld_2" ;
VAL_ 1648 MO_Bremslicht_Reku 0 "Aus" 1 "Ein" ;
VAL_ 1648 MO_StartStopp_PopUp 0 "Statuswechsel_ohne_Taster (Init)" 1 "StSt_per_Taster_deaktiviert" 2 "StSt_per_Taster_aktiviert" 3 "nicht verwendet" ;
VAL_ 1648 MO1_Sperr_Info_WFS 0 "nicht_gesperrt" 1 "gesperrt" ;
VAL_ 1648 MO1_Freigabe_Info_WFS 0 "ungueltig" 1 "gueltig" ;
VAL_ 1648 MO_EPCL 0 "EPCL_aus_kein_Text" 1 "EPCL_gelb_Stoerung" 2 "EPCL_gelb_Leistungsbeschraenkung" 3 "EPCL_rot_Fzg_sicher_abstellen" ;
VAL_ 1648 MO_Zylabsch_Texte_02 0 "ein_ZAS_generell_keine_ZAS_Anzeigen" 1 "ZAS_im_VMB" 2 "ZAS_im_ASB_1_Zyl_aktiv" 3 "ZAS_im_ASB_2_Zyl_aktiv" 4 "ZAS_im_ASB_3_Zyl_aktiv" 5 "ZAS_im_ASB_4_Zyl_aktiv" 6 "ZAS_im_ASB_5_Zyl_aktiv" 7 "ZAS_im_ASB_6_Zyl_aktiv" 8 "ZAS_im_ASB_8_Zyl_aktiv" 9 "ZAS_im_ASB_12_Zyl_aktiv" 13 "Uebergangsbetrieb" 14 "keine_ZAS_Anzeige_ggf_Stopp_Schub_Betrieb" 15 "ZAS_Stoerungs_Anzeige" ;
VAL_ 1648 MO_Fahrzeugtyp 0 "Verbrenner_Fahrzeug" 1 "Hybrid" 2 "E_Fahrzeug" 3 "E_Fahrzeug_mit_Range_Extender" 4 "Brennstoffzellenfahrzeug" 5 "tbd" 6 "tbd" 7 "tbd" ;
VAL_ 1648 MO_Abstellzeit 254 "Init" 255 "reserviert" ;
VAL_ 1648 MO_Abstellzeit_Status 0 "Abstellzeit_nicht_berechnet" 1 "Abstellzeit_berechnet" 2 "Abstellzeit_Minimalwert" 3 "Abstellzeit_ungueltig" ;
VAL_ 1648 MO1_Freigabe_Verfallsinfo_WFS 0 "verfaellt_nicht" 1 "verfaellt" ;
VAL_ 1648 MO_Hybrid_StartStopp_LED 0 "LED_aus_und_Blinken_aus" 1 "LED_ein_und_Blinken_aus" 2 "LED_ein_und_Blinken_ein_50_percent" 3 "reserviert" ;
VAL_ 1648 MO_Fehler_Zylabsch 0 "kein_Fehler" 1 "Notlauf_Vollmotorbetrieb" 2 "Notlauf_mindestens_einem_abgesch_Zylinder" ;
VAL_ 1648 MO_Anzahl_Abgesch_Zyl 0 "Vollmotorbetrieb" 1 "1_Zylinder_abgeschaltet" 2 "2_Zylinder_abgeschaltet" 3 "3_Zylinder_abgeschaltet" 4 "4_Zylinder_abgeschaltet" 5 "5_Zylinder_abgeschaltet" 6 "6_Zylinder_abgeschaltet" 7 "8_Zylinder_abgeschaltet" ;
VAL_ 1648 MO_Zylabsch_Texte 0 "keine_Texte" 1 "Zylinderabschaltung_deaktivieren" 2 "Zylinderabschaltung_aktivieren" 3 "Zylinderabschaltung_unruhig" ;
VAL_ 1648 MO_Ethanol_BS_Texte 0 "kein_Text" 1 "E85_Warm_Up" 2 "FlexFuel_Warnung_Stufe_3" 3 "Warmfahrempfehlung_MQB__FlexFuel_Warnung_Stufe_1" 4 "FlexFuel_Warnung_Stufe_2" 5 "FlexFuel_Warnung_Stufe_4" 6 "E25_Warm_Up" ;
VAL_ 1648 MO_Drehzahl_Warnung 0 "keinen_Warnhinweis_anzeigen" 1 "Warnhinweis_anzeigen" ;
VAL_ 1648 MO_obere_Drehzahlgrenze 0 "Init" ;
VAL_ 1366 MO_Fahrzeugabstellzeit_Status 0 "Abstellzeit_nicht_berechnet" 1 "Abstellzeit_berechnet" 2 "Abstellzeit_Minimalwert" 3 "Abstellzeit_ungültig" ;
VAL_ 1366 MO_HV_Auszeit_Status 0 "Abstellzeit_nicht_berechnet" 1 "Abstellzeit_berechnet" 2 "Abstellzeit_Minimalwert" 3 "Abstellzeit_ungültig" ;
VAL_ 1366 MO_Fahrzeugabstellzeit 254 "Init" 255 "Fehler" ;
VAL_ 1366 MO_HV_Auszeit 510 "Init" 511 "Fehler" ;
VAL_ 1366 MO_Verbau_StartSys_Ritzelstarter 0 "nicht_verbaut" 1 "verbaut" ;
VAL_ 1366 MO_Verbau_StartSys_EM_MV 0 "nicht_verbaut" 1 "verbaut" ;
VAL_ 1366 MO_Verbau_StartSys_EM_HV 0 "nicht_verbaut" 1 "verbaut" ;
VAL_ 1366 MO_Verbau_StartSys_RSG_NV 0 "nicht_verbaut" 1 "verbaut" ;
VAL_ 1366 MO_Verbau_StartSys_Q_Diode 0 "nicht_verbaut" 1 "verbaut" ;
VAL_ 1366 MO_Verbau_StartSys_RSG_MV 0 "nicht_verbaut" 1 "verbaut" ;
VAL_ 1366 MO_Ziel_SoC_Fremdladung 254 "Init" ;
VAL_ 269 MO_Mom_Soll_Roh 1022 "Init" ;
VAL_ 269 MO_Mom_Ist_Summe 1022 "Init" ;
VAL_ 269 MO_Mom_Traegheit_Summe 1022 "Init" ;
VAL_ 269 MO_Mom_Soll_gefiltert 1022 "Init" ;
VAL_ 269 MO_Mom_Schub 510 "Init" ;
VAL_ 269 MO_Status_Normalbetrieb_01 0 "kein_Normalbetrieb" 1 "Normalbetrieb_erreicht" ;
VAL_ 269 MO_erste_Ungenauschwelle 0 "genau" 1 "Momente ungenauer >8%" ;
VAL_ 269 MO_QBit_Motormomente 0 "gueltiger_Wert" 1 "Ersatz_Init_oder_Fehlerwert" ;
VAL_ 269 MO_Mom_neg_verfuegbar 510 "Init" 511 "Fehler" ;
VAL_ 269 MO_Mom_Begr_Fahr 510 "Init" 511 "Fehler" ;
VAL_ 269 MO_Mom_Begr_Schalt 1022 "Init" ;
VAL_ 269 MO_QBit_Drehzahl_01 0 "gueltiger_Wert" 1 "Ersatz_Init_oder_Fehlerwert" ;
VAL_ 269 MO_HYB_EMode_Info 0 "Normal_Mode" 1 "Depleting_Mode" 2 "Charge_Mode" 3 "Sonder_Schaltprogramm" ;
VAL_ 269 MO_HYB_max_ind_VM_Mom_02 254 "Init" 255 "Fehler" ;
VAL_ 269 MO_HYB_Zielzustand 0 "Init" 1 "Leerlauf_VM" 2 "hybridisch_Fahren" 3 "Fahren_EM" 4 "Fahrbereitschaft_EM" 5 "Fahrbereitschaft_VM" 7 "Fehler" ;
VAL_ 269 MO_HYB_Modus_Ankopplung_VM 0 "Schlupfankopplung" 1 "Direktankopplung" ;
VAL_ 269 MO_HYB_Freigabe_VM_Eingr 0 "kein_Wunsch" 1 "Eingriff_nicht_freigegeben" 2 "Eingriff_erwuenscht" ;
VAL_ 269 MO_HYB_Sollstatus_K0 0 "geschlossen" 1 "schlupfend" ;
VAL_ 269 MO_HYB_Komfortstufe 0 "normal" 1 "dynamisch" ;
VAL_ 269 MO_HYB_VM_bereit 0 "VM_nicht_bereit" 1 "VM_bereit" ;
VAL_ 269 MO_HYB_Stoppmodus 0 "Softstopp" 1 "Dynamikstopp" ;
VAL_ 269 MO_HYB_LowSpeedModus 0 "LowSpeed_mit_LLDZ" 1 "LowSpeed_ohne_LLDZ" ;
VAL_ 269 MO_HYB_Schaltverhinderung 0 "keine_Schaltverhinderung" 1 "Schaltverhinderung" ;
VAL_ 269 MO_HYB_E_Faktor 0 "null" 1 "plus_1" 2 "plus_2" 3 "plus_3" 4 "plus_4" 5 "plus_5" 6 "plus_6" 7 "plus_7" 8 "minus_8" 9 "minus_7" 10 "minus_6" 11 "minus_5" 12 "minus_4" 13 "minus_3" 14 "minus_2" 15 "minus_1" ;
VAL_ 269 MO_HYB_VM_Mom_oE_02 254 "Init" 255 "Fehler" ;
VAL_ 269 MO_EM1_SollDrehzahl 32767 "Init" ;
VAL_ 269 MO_Luftpfad_Verzugszeit_praed 0 "keine_Praediktion" ;
VAL_ 269 MO_EM2_SollDrehzahl 32767 "Init" ;
VAL_ 269 MO_TNW_Min_Strom_Lim 8190 "Init" ;
VAL_ 269 MO_TNW_Max_Strom_Lim 8190 "Init" ;
VAL_ 267 MO_Fahrpedalrohwert_01 255 "Fehler" ;
VAL_ 267 MO_QBit_Fahrpedalwerte_01 0 "gueltiger_Wert" 1 "Ersatz_Init_oder_Fehlerwert" ;
VAL_ 267 MO_Fahrpedalgradient 255 "Fehler" ;
VAL_ 267 MO_Sig_Fahrpedalgradient 0 "Fahrpedalgradient positiv" 1 "Fahrpedalgradient negativ" ;
VAL_ 267 MO_rel_Saugrohrdruck 0 "Init_Ueberdruck" 63 "Fehler" ;
VAL_ 267 MO_rel_Saugrohrdruck_gem_err 0 "errechnet" 1 "gemessen" ;
VAL_ 267 MO_Moment_im_Leerlauf 0 "kein_Leergas" 1 "Leergas" ;
VAL_ 267 MO_Schubabschaltung 0 "keine_Schubabschaltung" 1 "Schubabschaltung_aktiv" ;
VAL_ 267 MO_StartStopp_StoppVorbereitung 0 "Motorstopp_nicht_in_Vorbereitung" 1 "Motorstopp_in_Vorbereitung" ;
VAL_ 267 MO_Entkopplung_Sollschlupf 125 "Notoeffnen_Anfahrelement" 126 "Init" ;
VAL_ 267 MO_temporaere_Fahrerabwesenheit 0 "nicht_erkannt" 1 "erkannt" ;
VAL_ 267 TSK_a_Soll_gradientenbegrenzt 127 "Init_oder_nicht_aktiv" ;
VAL_ 267 TSK_Status 0 "Hauptschalter_aus" 1 "Init" 2 "passiv" 3 "aktiv" 4 "Uebertreten" 5 "brake_only_Mode" 6 "reversibel_aus" 7 "irreversibel_aus" ;
VAL_ 267 TSK_v_Begrenzung_aktiv 0 "inaktiv" 1 "aktiv" ;
VAL_ 267 TSK_Standby_Anf_ESP 0 "keine_Standby_Anforderung" 1 "Standby_Anforderung" ;
VAL_ 267 TSK_Freig_Verzoeg_Anf 0 "Verzoegerungsanforderung_nicht_freigegeben" 1 "Verzoegerungsanforderung_freigegeben" ;
VAL_ 267 TSK_Limiter_ausgewaehlt 0 "kein_Limiter_ausgewaehlt" 1 "Limiter_ausgewaehlt" ;
VAL_ 267 TSK_Hauptschalter_GRA_ACC 0 "Init" 1 "Aus" 2 "Ein" 3 "Fehler" ;
VAL_ 267 TSK_SRBM_Anf_ASIL 0 "keine_SRBM_Anforderung" 1 "SRBM_Anforderung_in_ASIL_QM" 2 "SRBM_Anforderung_in_ASIL_A" 3 "SRBM_Anforderung_in_ASIL_B" 4 "SRBM_Anforderung_in_ASIL_C" ;
VAL_ 267 TSK_ax_Getriebe_02 511 "Neutralwert" ;
VAL_ 267 TSK_Zwangszusch_ESP 0 "keine_ESP_ASR_Beeinflussung" 1 "ESP_ASR_Beeinflussung" ;
VAL_ 267 TSK_Radsollmoment 65534 "Init" 65535 "Fehler" ;
VAL_ 267 TSK_Kategorie_Verzoegerungsfkt 0 "Schnittstelle_nicht_vorhanden" 1 "Kategorie_Fahrerassistenz" 2 "Kategorie_Schubverzoegerung" 3 "reserviert" ;
VAL_ 267 TSK_Notstopp_Anf 0 "Ueberwachung_aus" 1 "Ueberwachung_ein" 2 "Notstopp_ausloesen" ;
VAL_ 267 MO_Status_MinDrzEingriff 0 "kein_Eingriff" 1 "Schalteingriff" 2 "ESP_Eingriff" 3 "Achsdifferenzdrehzahl" 4 "Bauteilschutz" 5 "Rennstart_Fahrbarkeit" ;
VAL_ 267 MO_Status_MaxDrzEingriff 0 "kein_Eingriff" 1 "Schalteingriff" 2 "ESP_Eingriff" 3 "Achsdifferenzdrehzahl" 4 "Bauteilschutz" 5 "Rennstart_Fahrbarkeit" ;
VAL_ 267 MO_Status_MinDrzEingriff_sek 0 "kein_Eingriff" 1 "Schalteingriff" 2 "ESP_Eingriff" 3 "Achsdifferenzdrehzahl" 4 "Bauteilschutz" 5 "Rennstart_Fahrbarkeit" ;
VAL_ 267 MO_Status_MaxDrzEingriff_sek 0 "kein_Eingriff" 1 "Schalteingriff" 2 "ESP_Eingriff" 3 "Achsdifferenzdrehzahl" 4 "Bauteilschutz" 5 "Rennstart_Fahrbarkeit" ;
VAL_ 267 TSK_SRBM_max_Gradient 126 "Init" 127 "Fehler" ;
VAL_ 512 TSK_Wunschgeschw 1022 "keine_Anzeige" 1023 "kein_Wert_im_Speicher" ;
VAL_ 512 TSK_praediktiver_Hinweis 0 "keine_Anzeige" 1 "Vorschlag_zur_Bestaetigung" 2 "Hinweis_neuer_Setzwert" 3 "Regelung_im_Uebergang" 4 "Tempolimit_voraus" 5 "Tempolimit_erkannt" ;
VAL_ 512 TSK_naechstes_Event 0 "Init" 1 "Tempolimit_5" 2 "Tempolimit_10" 3 "Tempolimit_15" 4 "Tempolimit_20" 5 "Tempolimit_25" 6 "Tempolimit_30" 7 "Tempolimit_35" 8 "Tempolimit_40" 9 "Tempolimit_45" 10 "Tempolimit_50" 11 "Tempolimit_55" 12 "Tempolimit_60" 13 "Tempolimit_65" 14 "Tempolimit_70" 15 "Tempolimit_75" 16 "Tempolimit_80" 17 "Tempolimit_90" 18 "Tempolimit_100" 19 "Tempolimit_110" 20 "Tempolimit_120" 21 "Tempolimit_130" 22 "Tempolimit_140" 23 "Tempolimit_150" 24 "Tempolimit_160" 25 "Tempolimit_unbegrenzt" 26 "Linkskurve" 27 "Rechtskurve" 28 "Kuppe" 29 "Steigung" 30 "Gefaelle" 31 "Kreuzung" 32 "Ampel" 33 "Bahnuebergang" 34 "Ortsanfang" 35 "Kreisverkehr" 36 "naechstes_Limit_ausserh_Verfueg" 37 "Tempolimit_85" ;
VAL_ 512 TSK_Fahrzeugstatus_praed_Fkt 0 "init" 1 "Praed_Fkt_verfuegbar" 2 "Praed_Fkt_eingeschraenkt_verfueg" 3 "Praed_Fkt_nicht_verfuegbar" 4 "Praed_Fkt_Land_nicht_verfuegbar" 5 "Praed_Fkt_Auffahrt" 6 "Praed_Fkt_Abfahrt" 7 "Praed_Fkt_Regelbereich_verlassen" ;
VAL_ 512 TSK_praediktiver_Automode 0 "Automode_inaktiv" 1 "Automode_aktiv" ;
VAL_ 512 CE_StStrtDlyEmiSysPrep 0 "Startverzögerung_inaktiv" 1 "Startverzögerung_aktiv" 2 "Init" 3 "Fehler" ;
VAL_ 512 CE_StLdRdcEmiSysPrep 0 "nicht_belastbar" 1 "durch_Nebenaggregate_belastbar" 2 "voll_belastbar" 3 "Reserve" 5 "Reserve" 6 "Init" 7 "Fehler" ;
VAL_ 512 TSK_Texte 0 "kein_Text" 1 "GRA_Modus_ausgewaehlt" 2 "ACC_Modus_ausgewaehlt" 3 "Lim_Modus_ausgewaehlt" 4 "Lim_nicht_verfuegbar_ESC_passiv" 5 "GRA_nicht_verfuegbar_ESC_passiv" 6 "Lim_nicht_verfuegbar_Charisma" 7 "GRA_nicht_verfuegbar_Charisma" 8 "Lim_nicht_verfuegbar_HDC" 9 "GRA_nicht_verfuegbar_HDC" 10 "P_GRA_Modus_ausgewaehlt" 11 "P_LIM_Modus_ausgewaehlt" 12 "Bremse_ueberhitzt" 13 "kein_Laengsregler" 14 "kein_Abstandsregler" 15 "keine_Abstandsregelung" 16 "Bitte_Hauptschalter_einschalten" ;
VAL_ 512 TSK_Akustik 0 "keine_Akustik" 1 "einzelner_Warnton" 2 "dauerhafter_Warnton" ;
VAL_ 512 TSK_Texte_Primaeranz 0 "keine_Anzeige" 1 "GRA_Symbol_passiv_xxx_kmh_mph" 2 "GRA_Symbol_aktiv_xxx_kmh_mph" 3 "Bremse_ueberhitzt" 4 "Limiter_Modus_aktiviert" 5 "GRA_Modus_aktiviert" 6 "ACC_Modus_aktiviert" 7 "Opt_Geschwindigkeitswarnung" 8 "Opt_und_akustische_GeschwWarnung" 9 "Opt_GeschwWarnung_dauerhaft_mit_einmal_Akustik" 10 "Limiter_passiv_mit_Akustik" 11 "Limiter_Fehler_mit_Akustik" 12 "Limiter_Symbol_passiv_xxx_kmh_mph" 13 "Limiter_Symbol_aktiv_xxx_kmh_mph" 14 "Popup_Geschw_zu_hoch__Resume_unzulaessig" ;
VAL_ 512 TSK_Limiter_Fahrerinfo 0 "keine_Info" 1 "Limit_erreicht" 2 "Ueberschritten" 3 "Vom_Fahrer_Ueberstimmt" ;
VAL_ 512 TSK_Limiter_Anzeige 0 "Display_Anzeige_GRA_ACC" 1 "Display_Anzeige_Limiter" ;
VAL_ 512 TSK_Fahrzeugstatus_GRA 0 "GRA_verfuegbar" 1 "GRA_nicht_verfuegbar" ;
VAL_ 512 TSK_Fahrzeugstatus_Limiter 0 "Limiter_verfuegbar" 1 "Limiter_nicht_verfuegbar" ;
VAL_ 512 MO_Motorlaufwarnung 0 "keine_Anzeige" 1 "Anforderung_Motorlaufwarnung" ;
VAL_ 512 TSK_naechstes_Event_Einheit 0 "kmh" 1 "mph" ;
VAL_ 512 TSK_Status_Anzeige 0 "Hauptschalter_aus" 1 "Init" 2 "passiv" 3 "aktiv" 4 "Uebertreten" 5 "Limitiierung_aktiv" 6 "reversibel_aus" 7 "irreversibel_aus" ;
VAL_ 512 MO_Sperrung_FahrPr_BZS 0 "keine Sperrung" 1 "Sperrung BZS1" 2 "Sperrung BZS2" 4 "Sperrung BZS3" 8 "Sperrung BZS4" 16 "Sperrung BZS5" 32 "Sperrung BZS6" 64 "Sperrung BZS7" 128 "Sperrung BZS8" ;
VAL_ 512 MO_Rampenzeit_Generator_Anf 0 "0_sec" 1 "1_sec" 2 "2_sec" 3 "3_sec" 4 "4_sec" 5 "5_sec" 6 "6_sec" 7 "7_sec" 8 "8_sec" 9 "9_sec" 10 "reserviert" 11 "reserviert" 12 "reserviert" 13 "reserviert" 14 "reserviert" 15 "keine_Anforderung" ;
VAL_ 512 MO_Prio_MAX_Wunschdrehzahl 0 "Wunsch" 1 "Zwang" ;
VAL_ 512 MO_Prio_MIN_Wunschdrehzahl 0 "Wunsch" 1 "Zwang" ;
VAL_ 512 MO_Luftpfad_aktiv 0 "kein Eingriff oder nur Eingriff über Zündpfad" 1 "Eingriff über Luftpfad" ;
VAL_ 512 MO_v_Begrenz_Aktivierbar 0 "V-Begrenzung nicht möglich" 1 "V-Begrenzung möglich" ;
VAL_ 512 MO_Charisma_FahrPr 0 "keine_Funktion" 1 "Programm_1" 2 "Programm_2" 3 "Programm_3" 4 "Programm_4" 5 "Programm_5" 6 "Programm_6" 7 "Programm_7" 8 "Programm_8" 9 "Programm_9" 10 "Programm_10" 11 "Programm_11" 12 "Programm_12" 13 "Programm_13" 14 "Programm_14" 15 "Programm_15" ;
VAL_ 512 MO_Charisma_Status 0 "Init" 1 "verfuegbar" 2 "nicht_verfuegbar" 3 "asynchron_durch_Fahrerwunsch" ;
VAL_ 512 MO_StSt_Charisma_FahrPr 0 "keine_Funktion" 1 "Programm_1" 2 "Programm_2" 3 "Programm_3" 4 "Programm_4" 5 "Programm_5" 6 "Programm_6" 7 "Programm_7" 8 "Programm_8" 9 "Programm_9" 10 "Programm_10" 11 "Programm_11" 12 "Programm_12" 13 "Programm_13" 14 "Programm_14" 15 "Programm_15" ;
VAL_ 512 MO_StSt_Charisma_Status 0 "Init" 1 "verfuegbar" 2 "nicht_verfuegbar" 3 "asynchron_durch_Fahrerwunsch" ;
VAL_ 512 MO_BZS_Charisma_FahrPr 0 "keine_Funktion" 1 "Programm_1" 2 "Programm_2" 3 "Programm_3" 4 "Programm_4" 5 "Programm_5" 6 "Programm_6" 7 "Programm_7" 8 "Programm_8" 9 "Programm_9" 10 "Programm_10" 11 "Programm_11" 12 "Programm_12" 13 "Programm_13" 14 "Programm_14" 15 "Programm_15" ;
VAL_ 512 MO_BZS_Charisma_Status 0 "Init" 1 "verfuegbar" 2 "nicht_verfuegbar" 3 "asynchron_durch_Fahrerwunsch" ;
VAL_ 512 MO_NGS_Position 0 "Neutralposition_nicht_erkannt" 1 "Neutralposition_erkannt" ;
VAL_ 512 MO_NGS_Status 0 "nicht_verbaut" 1 "nicht_plausibilisiert" 2 "plausibilisiert" 3 "Fehler" ;
VAL_ 512 MO_v_Begrenzung_Niveau 0 "keine_Begrenzung_aktiv" 1 "Sicherheitsbegrenzung_1_aktiv" 2 "Sicherheitsbegrenzung_2_aktiv" 3 "Komfortbegrenzung_aktiv" ;
VAL_ 512 MO_Anzeige_Rekuperation 0 "Init_und_nicht_verbaut" ;
VAL_ 512 PEA_Fortschrittsanzeige 127 "Neutralwert" ;
VAL_ 512 MO_Anzeige_Fahrbereitschaft 0 "OFF" 1 "READY" ;
VAL_ 512 MO_Boost_verfuegbar 0 "Init" 253 "Nicht_verbaut" 254 "Funktion_deaktiv" 255 "Fehler" ;
VAL_ 512 MO_Overboost 0 "inaktiv" 1 "aktiv" ;
VAL_ 512 MO_Boost_aktiv 0 "kein_Boost_aktiv" 1 "Boost_aktiv" ;
VAL_ 512 MO_Anzeige_Betriebsmodus 0 "Init_keine_Anzeige" 1 "EV" 2 "Auto" 3 "Hold" 4 "Charge" 5 "GTE" 6 "ECO" 7 "SPORT" 8 "Auto_praediktiv" 9 "Manuell_SOC_erhoehen" 10 "Manuell_SOC_halten" 11 "Manuell_SOC_verringern" ;
VAL_ 512 PEA_Hinweis 0 "keine_Anzeige" 1 "Anzeige_Fusssymbol_1" 2 "Anzeige_Fusssymbol_2" 3 "Anzeige_Auskuppeln" ;
VAL_ 512 PEA_Ereignisanzeige 0 "keine_Anzeige" 1 "Linkskurve_voraus" 2 "Rechtskurve_voraus" 3 "Kreuzung_voraus" 4 "Gefaelle_voraus" 5 "Kreisverkehr_voraus" 6 "Fahrzeug_voraus" 7 "Tempolimit_voraus" 8 "Ereignis_voraus" 9 "Autobahnabfahrt_voraus" 10 "Autobahnauffahrt_voraus" 11 "Abbiegung_links_voraus" 12 "Abbiegung_rechts_voraus" 13 "Ortseinfahrt_voraus" 14 "Autobahnabfahrt_links_voraus" ;
VAL_ 512 PEA_Ereignisanzeige_temporaer 0 "keine_Anzeige" 1 "Anzeige_temporaer" ;
VAL_ 512 PEA_Abschalttexte 0 "keine_Anzeige" 1 "PEA_ausserhalb_Einsatzgebiet" 2 "PEA_temporaer_nicht_verfuegbar" 3 "PEA_vom_Fahrer_deaktiviert" ;
VAL_ 512 PEA_Zielgeschw_Einheit 0 "km_h" 1 "mph" ;
VAL_ 512 PEA_Zielgeschw 0 "keine_Anzeige" 1 "Wert_5" 2 "Wert_10" 3 "Wert_15" 4 "Wert_20" 5 "Wert_25" 6 "Wert_30" 7 "Wert_35" 8 "Wert_40" 9 "Wert_45" 10 "50" 11 "Wert_55" 12 "Wert_60" 13 "Wert_65" 14 "Wert_70" 15 "Wert_75" 16 "Wert_80" 17 "Wert_85" 18 "Wert_90" 19 "Wert_95" 20 "Wert_100" 21 "Wert_105" 22 "Wert_110" 23 "Wert_115" 24 "Wert_120" 25 "Wert_125" 26 "Wert_130" 27 "Wert_140" 28 "Wert_150" 29 "Wert_160" ;
VAL_ 512 MO_Antriebsstrang_Warnung_HS 0 "Keine_Anzeige" 1 "Fehlereskalationsstufe_I" 2 "Fehlereskalationsstufe_II" 3 "Fehlereskalationsstufe_III" ;
VAL_ 512 MO_Text_Aktivierung_Antrieb 0 "keine_Anzeige" 1 "Ladestecker_nicht_fahrbereit" 2 "erneute_Aktivierung_erforderlich" 3 "Warten_Antrieb_wird_aktiviert" 4 "zum_Fahren_Bremse_und_Fahrstufe" 5 "h2_Tankklappe_nicht_fahrbereit" 6 "zum_Starten_Bremse_treten" 7 "zum_Starten_Kupplung_treten" 15 "Init" ;
VAL_ 512 ISA_Tempolimit_Regelung 0 "Init" 1 "Tempolimit_5" 2 "Tempolimit_10" 3 "Tempolimit_15" 4 "Tempolimit_20" 5 "Tempolimit_25" 6 "Tempolimit_30" 7 "Tempolimit_35" 8 "Tempolimit_40" 9 "Tempolimit_45" 10 "Tempolimit_50" 11 "Tempolimit_55" 12 "Tempolimit_60" 13 "Tempolimit_65" 14 "Tempolimit_70" 15 "Tempolimit_75" 16 "Tempolimit_80" 17 "Tempolimit_90" 18 "Tempolimit_100" 19 "Tempolimit_110" 20 "Tempolimit_120" 21 "Tempolimit_130" 22 "Tempolimit_140" 23 "Tempolimit_150" 24 "Tempolimit_160" 25 "Tempolimit_unbegrenzt" 26 "Linkskurve" 27 "Rechtskurve" 28 "Kuppe" 29 "Steigung" 30 "Gefaelle" 31 "Kreuzung" 32 "Ampel" 33 "Bahnuebergang" 34 "Ortsanfang" 35 "Kreisverkehr" 36 "naechstes_Limit_ausserh_Verfueg" ;
VAL_ 512 PEA_Fahrerinfo 0 "keine_Anzeige" 1 "Anzeige_Fahreruebernahme_hart" 2 "Anzeige_Fahreruebernahme_medium" 3 "Anzeige_Fahreruebernahme_soft" 4 "Anzeige_Fahreruebernahme_Popup" 5 "Fehleranzeige_FAS_Sammelmeldung" ;
VAL_ 512 CE_CtrPrpPrep 0 "Ready" 1 "Ready_in_1" 2 "Ready_in_2" 3 "Ready_in_3" 7 "keine_Anzeige" ;
VAL_ 512 CE_PrctPrpPrep 125 "Keine_Anzeige" 126 "InitWert" 127 "Fehler" ;
VAL_ 512 MO_Kuehlmitttel_Sensor_AGB2 0 "OK" 1 "Kuehlmittel_unter_min" ;
VAL_ 512 CE_FlgEmiColdLmp 0 "Lamp_off" 1 "Lamp_on" ;
VAL_ 512 CE_FlgEmiColdTxt 0 "kein_Text" 1 "Textanzeige_Leistungsbegrenzung" ;
VAL_ 512 CE_FlgHybModAdvi 0 "kein_Text" 1 "Textanzeige_Hybridmodus_waehlen" ;
VAL_ 512 CE_FlgPTLimPrfTxt 0 "kein_Text" 1 "Textanzeige_Leistungsbegrenzung" ;
VAL_ 512 TSK_praed_Wunschgeschw 1022 "keine_Anzeige" 1023 "kein_praed_Setzwert_verfuegbar" ;
VAL_ 332 MO_Anforderung_HMS 0 "keine_Anforderung" 1 "halten" 2 "parken" 3 "halten_Standby" 4 "anfahren" 5 "Loesen_ueber_Rampe" 7 "HMS_uebernehmen" ;
VAL_ 332 FoD_DTC_TSK_GRA 0 "Kein_DTC" 1 "DTC_vorhanden_oder_in_Quali" ;
VAL_ 332 TSK_vMax_aktuell 254 "kein_Limit_aktiv" 255 "Init" ;
VAL_ 332 ISA_Status 0 "ISA_nicht_aktiv" 1 "Init" 2 "ISA_degradiert" 3 "ISA_aktiv" 4 "reserviert" 5 "reserviert" 6 "reserviert" 7 "reserviert" ;
VAL_ 332 ISA_Regelung_aktiv 0 "ISA_Regelung_nicht_aktiv" 1 "ISA_Regelung_aktiv" ;
VAL_ 332 ISA_Tempolimitwarnung 0 "ISA_keine_Warnung" 1 "ISA_Warnung_aktiv" ;
VAL_ 332 MO_Red_El_Fahrleistung 0 "keine_Anzeige" 1 "mehr_als_20Prcnt_Red" 2 "Reserve_1" 3 "Reserve_2" 4 "unter_GBB_Schwelle_Anhaenger" 5 "unter_GBB_Schwelle" 6 "unter_minimal_Schwelle" 7 "kein_Vortrieb" ;
VAL_ 332 TSK_Status_EA 0 "Aus" 1 "Init_oder_nicht_verbaut" 3 "Aktiv" 4 "Uebertreten" 5 "Abschaltung_laeuft" 6 "Reversibel_aus" 7 "Fehler" ;
VAL_ 332 FoD_DTC_TSK_ACC 0 "Kein_DTC" 1 "DTC_vorhanden_oder_in_Quali" ;
VAL_ 332 TSK_ACC_FoD_Status 0 "default" 1 "nicht_aktiv" 2 "aktiv" 3 "nicht_genutzt" ;
VAL_ 332 TSK_GRA_FoD_Status 0 "default" 1 "nicht_aktiv" 2 "aktiv" 3 "nicht_genutzt" ;
VAL_ 332 TSK_vMax_Fahrerassistenz 511 "Init_ungueltig_keine_Beschraenkung" ;
VAL_ 332 TSK_Einheit_vMax_Fahrerassistenz 0 "kmh" 1 "mph" ;
VAL_ 332 TSK_Status_PLA 0 "Aus_Funktionsbereit" 1 "Init_oder_nicht_verbaut" 2 "aktivierbar" 3 "aktiv" 5 "Abschaltung_laeuft" 6 "reversibel_aus" 7 "Fehler" ;
VAL_ 332 TSK_aktives_System 0 "keine_Funktion_aktiv" 1 "GRA_ACC" 2 "ARA" 3 "Speedlimiter" 4 "IPA" 5 "PLA" 6 "PEA_Ausrollassistent" 7 "EA" ;
VAL_ 332 TSK_erhoehter_Fahrwiderstand 0 "kein_erhoehter_Fahrwiderstand" 1 "erhoehter_Fahrwiderstand" ;
VAL_ 332 TSK_Anf_Antriebsmoment 0 "keine_Anforderung" 1 "Anforderung_aktiv" ;
VAL_ 332 TSK_Status_ARA 0 "Aus" 1 "Init_oder_nicht_verbaut" 2 "aktivierbar" 3 "aktiv" 5 "abschaltung_laeuft" 6 "reversibel_aus" 7 "Fehler" ;
VAL_ 332 TSK_Status_IPA 0 "Aus_Funktionsbereit" 1 "Init_oder_nicht_verbaut" 2 "aktivierbar" 3 "aktiv" 4 "Fahreruebernahme_angefordert" 5 "Abschaltung_laueft" 6 "reversibel_aus" 7 "Fehler" ;
VAL_ 332 TSK_aktives_System_02 0 "keine_Funktion_aktiv" 1 "GRA_ACC" 2 "ARA" 3 "Speedlimiter" 4 "IPA" 5 "PLA" 6 "PEA_Ausrollassistent" 7 "EA" 8 "Staupilot" 9 "RHP" ;
VAL_ 332 TSK_Status_RHP 0 "off" 1 "init" 2 "standby" 3 "active" 4 "driver_override" 5 "shutdown" 6 "reversible_failure" 7 "irreversible_failure" ;
VAL_ 332 MO_Kuppl_betaetigt 0 "Kupplung_nicht_betaetigt" 1 "Kupplung_betaetigt" ;
VAL_ 332 MO_QBit_Kuppl_betaetigt 0 "gueltiger_Wert" 1 "Ersatz_Init_oder_Fehlerwert" ;
VAL_ 332 MO_Klima_Regelmodus 0 "Init" 1 "Regelmodus_1" 2 "Regelmodus_2" 3 "Regelmodus_3" ;
VAL_ 332 MO_Fahrbereitschaft 0 "Fahrzykl_inaktiv__kein_Antrieb" 1 "Fahrzykl_aktiv__kein_Antrieb" 2 "Fahrzykl_aktiv__Antrieb_moeglich" ;
VAL_ 332 MO_Freilauf_Info 0 "Freilauf_freigegeben" 1 "Weiches_Veto_uebertippbar" 2 "Hartes_Veto_Abbruch" 3 "Freilauf_Anforderung" ;
VAL_ 332 CE_FlgLnchCtlPreCnd 0 "not_fulfilled" 1 "fulfilled" ;
VAL_ 332 MO_Krit_Heckobjekt 0 "Init_kein_relevantes_Objekt" 1 "Entfernung_grosser_Abstand" 2 "Annaeherung_grosser_Abstand" 3 "Entfernung_geringer_Abstand" 4 "Annaeherung_geringer_Abstand" 7 "Fehler" ;
VAL_ 332 MO_NGS_Gangpos 0 "nicht_bedient" 1 "1_3_oder_5" 2 "2_4_6_oder_R" 3 "R" 4 "Neutralposition" 5 "Zwischenposition" 6 "Sensor_temp_nicht_verfuegbar" 7 "Fehler" ;
VAL_ 332 MO_Freilauf_Status 0 "Freilauf_inaktiv_aber_moeglich" 1 "Freilauf_aktiv" 2 "Freilauf_nicht_moegl_1Verhinderer" 3 "Freilauf_nicht_moegl_gr_1Verhinderer" 7 "Fehler" ;
VAL_ 332 MO_EBoost_verf_praed 0 "Init_oder_nicht_verfuegbar" 1 "EBoost_kurzzeit_verfuegbar" 2 "EBoost_langzeit_verfuegbar" ;
VAL_ 332 MO_Heckspoiler_Anf 0 "nicht_angefordert" 1 "angefordert" ;
VAL_ 332 MO_eLaunch_verf 0 "Init" 1 "nicht_verfuegbar" 2 "verfuegbar" ;
VAL_ 332 MO_Positionierung_aktiv 0 "keine_Positionierung_aktiv" 1 "Positionierung_aktiv" ;
VAL_ 332 MO_Veto_Launchcontrol 0 "kein_Veto__LC_moeglich" 1 "Veto__LC_nicht_moeglich" ;
VAL_ 332 MO_Startwunsch 0 "kein_Startwunsch" 1 "Startwunsch" ;
VAL_ 332 MO_LaunchControl 0 "nicht_verfuegbar" 1 "verfuegbar" ;
VAL_ 332 MO_UBE_Hybrid_Reserve 1023 "Init" ;
VAL_ 332 OBDProtocol_req 0 "OBDonUDS" 1 "OBDclassic" 254 "Init" 255 "Fehler" ;
VAL_ 332 MO_Servicemodus 0 "nicht_aktiv" 1 "Service_Mode_1" 2 "Service_Mode_2" 3 "Service_Mode_3" 4 "Service_Mode_4" 5 "Service_Mode_5" 6 "Service_Mode_6" 7 "Service_Mode_7" 8 "Service_Mode_8" 9 "Service_Mode_9" 10 "Service_Mode_10" 11 "Service_Mode_11" 12 "Service_Mode_12" 13 "Service_Mode_13" 14 "Service_Mode_14" 15 "Service_Mode_15" ;
VAL_ 332 OBD_ClearMem_Inhibit 0 "FSP_Loeschen_zulaessig" 1 "FSP_Loeschen_nicht_zulaessig" ;
VAL_ 332 OBD_Sperrung_Kaltstart_Denom 0 "EVAP_Berechnung_freigegeben" 1 "EVAP_Berechnung_gesperrt" ;
VAL_ 332 MO_QBit_Aussen_Temp 0 "gueltiger_Wert" 1 "Ersatz_Init_oder_Fehlerwert" ;
VAL_ 332 OBD_Sperrung_IUMPR 0 "IUMPR_Berechnung_freigegeben" 1 "IUMPR_Berechnung_gesperrt" ;
VAL_ 332 OBD_Kaltstart_Denominator 0 "Denominator_nicht_hochzaehlen" 1 "Bedingungen_zum_Inkr_des_Kaltstart_Denom_erf" ;
VAL_ 332 OBD_Minimum_Trip 0 "kein_Min_Normed_Trip" 1 "Min_Normed_Trip" ;
VAL_ 332 OBD_Driving_Cycle 0 "kein_Driving_Cycle_erkannt" 1 "Driving_Cycle_erkannt" ;
VAL_ 332 OBD_Warm_Up_Cycle 0 "kein_Warm_Up_Cycle_erkannt" 1 "Warm_Up_Cycle_erkannt" ;
VAL_ 332 OBD_Normed_Trip 0 "kein_Normed_Trip" 1 "Normed_Trip" ;
VAL_ 332 MO_EMG_Min_Leistung 2046 "Init" 2047 "Fehler" ;
VAL_ 332 MO_EMG_Max_Leistung 2046 "Init" 2047 "Fehler" ;
VAL_ 332 MO_MVEM_MinLeistung_MVVerbrauch 1022 "Init" 1023 "Fehler" ;
VAL_ 332 MO_MVEM_MaxLeistung_MVVerbrauch 1022 "Init" 1023 "Fehler" ;
VAL_ 332 MO_UBE_Reserve 1023 "Init" ;
VAL_ 332 OBD_Aussen_Temp_gef 254 "Initwert" 255 "Fehler" ;
VAL_ 246 TS_Faktor_Radmomente 0 "Faktor_1NM" 1 "Faktor_2NM" 2 "Faktor_3NM" 3 "Faktor_4NM" ;
VAL_ 246 TS_Status_MomRad_Ist 0 "FuSi_hohe_Genauigkeit" 1 "FuSi_niedrige_Genauigkeit" 2 "QM_fehlerfrei" 3 "QM_mit_Fehlern" ;
VAL_ 246 TS_MomRad_verfuegb_maxReku_Summe 4094 "Init" ;
VAL_ 246 TS_MomRad_Ist 8190 "Init" ;
VAL_ 246 TS_MomRad_Soll_Summe 8190 "Init" ;
VAL_ 246 TS_MomRad_Wunsch 8190 "Init" ;
VAL_ 246 TS_MomRad_Wunsch_sek 8190 "Init" ;
VAL_ 246 TS_MomRad_verfuegb_max 4094 "Init" ;
VAL_ 246 TS_MomRad_verfuegb_max_sek 4094 "Init" ;
VAL_ 246 TS_MomRad_verfuegb_maxReku 4094 "Init" ;
VAL_ 246 TS_MomRad_verfuegb_maxReku_sek 4094 "Init" ;
VAL_ 246 TS_MomRad_Ist_sek 8190 "Init" ;
VAL_ 246 TS_Allrad_Anteil_sek 510 "Init" 511 "Fehler" ;
VAL_ 246 FDR_Allrad_Anteil_max_sek 510 "Init" 511 "Fehler" ;
VAL_ 246 FDR_Allrad_Anteil_min_sek 510 "Init" 511 "Fehler" ;
VAL_ 246 FDR_MomRad_Eingriff 8190 "Init" 8191 "Fehler" ;
VAL_ 246 FDR_Status_Eingriff 0 "kein_Eingriff" 1 "Eingriff" ;
VAL_ 246 FDR_MomRad_Eingriff_sek 8190 "Init" 8191 "Fehler" ;
VAL_ 246 FDR_Status_Eingriff_sek 0 "kein_Eingriff" 1 "Eingriff" ;
VAL_ 246 MO_Mom_Begr_Fahr_Pred 510 "Init" ;
VAL_ 246 FDR_Zwangszusch_ESP 0 "keine_ESP_ASR_Beeinflussung" 1 "ESP_ASR_Beeinflussung" ;
VAL_ 246 MO_EMG_Sollmodus 0 "Standby" 1 "Momentenreg" 2 "Int_Drehzahlreg" 3 "Spannungsreg" 4 "Spannungsreg_Batt_Ab" 6 "Kalibrierung" 8 "Freilauf" 9 "Momentenreg_Komfortfunktionen" 10 "Asynchrones_Bremsen" 11 "Positionieren" 12 "Int_Diagnose" 15 "Init" ;
VAL_ 246 TS_Status_DrzReg 0 "Init" 1 "Verfuegbar" 2 "Fehler_ohne_DrzReg_Abweichung" 3 "Fehler_mit_DrzReg_Abweichung" ;
VAL_ 246 TS_Status_DrzReg_sek 0 "Init" 1 "Verfuegbar" 2 "Fehler_ohne_DrzReg_Abweichung" 3 "Fehler_mit_DrzReg_Abweichung" ;
VAL_ 246 MO_EMG_SollDrehzahl 32767 "Init" ;
VAL_ 246 MO_EMG_Max_Momentengradient 125 "keine_Beschraenkung" 126 "Init" 127 "Reserve" ;
VAL_ 246 MO_EMG_Generator_Leistung 2046 "Init" 2047 "Fehler" ;
VAL_ 246 MO_EMG_Max_Strom_Lim 2046 "Init" 2047 "Fehler" ;
VAL_ 246 MO_EMG_Min_Strom_Lim 2046 "Init" 2047 "Fehler" ;
VAL_ 246 MO_EMG_Max_Spannung_Lim 254 "Init" 255 "Fehler" ;
VAL_ 246 MO_EMG_Min_Spannung_Lim 254 "Init" 255 "Fehler" ;
VAL_ 246 MO_EMG_SollMoment_02 65534 "Init" ;
VAL_ 246 MO_EMG_Sollspannung 254 "Init" 255 "Fehler" ;
